VERSION "dbc-export 1 2026.26.6.5"

NS_ :

BS_:

BU_: APB APP APS DAS EPAS3S ESP GTW IBST PARK RADC RCM RCM2 RCM3 TPMS TRCM USM

BO_ 1113 APS_warningMatrix2: 8 APS
 SG_ APS_w129_ECU_Power_Issue : 0|1@1+ (1,0) [0|1] "" Vector__XXX
 SG_ APS_w130_ECU_Thermal_Issue : 1|1@1+ (1,0) [0|1] "" Vector__XXX
 SG_ APS_w131_trap_exception : 2|1@1+ (1,0) [0|1] "" Vector__XXX
 SG_ APS_w132_appVersionMismatch : 3|1@1+ (1,0) [0|1] "" Vector__XXX
 SG_ APS_w133_ETHSwitchError : 4|1@1+ (1,0) [0|1] "" Vector__XXX
 SG_ APS_w134_appMia : 5|1@1+ (1,0) [0|1] "" Vector__XXX
 SG_ APS_w135_appCritical : 6|1@1+ (1,0) [0|1] "" Vector__XXX
 SG_ APS_w136_gpsDisabled : 7|1@1+ (1,0) [0|1] "" Vector__XXX
 SG_ APS_w137_gpsFaultReset : 8|1@1+ (1,0) [0|1] "" Vector__XXX
 SG_ APS_w138_gpsComIssue : 9|1@1+ (1,0) [0|1] "" Vector__XXX
 SG_ APS_w139_udpBufferOverflow : 10|1@1+ (1,0) [0|1] "" Vector__XXX
 SG_ APS_w140_vcfrontMiaVehicleBus : 11|1@1+ (1,0) [0|1] "" Vector__XXX
 SG_ APS_w141_rcmMiaPartyBus : 12|1@1+ (1,0) [0|1] "" Vector__XXX
 SG_ APS_w142_diMiaPartyBus : 13|1@1+ (1,0) [0|1] "" Vector__XXX
 SG_ APS_w143_espMiaPartyBus : 14|1@1+ (1,0) [0|1] "" Vector__XXX
 SG_ APS_w144_vcleftMiaPartyBus : 15|1@1+ (1,0) [0|1] "" Vector__XXX
 SG_ APS_w145_vcrightMiaPartyBus : 16|1@1+ (1,0) [0|1] "" Vector__XXX
 SG_ APS_w146_epas3pMiaPartyBus : 17|1@1+ (1,0) [0|1] "" Vector__XXX
 SG_ APS_w147_vcleftMiaVehBus : 18|1@1+ (1,0) [0|1] "" Vector__XXX
 SG_ APS_w148_vcrightMiaVehBus : 19|1@1+ (1,0) [0|1] "" Vector__XXX
 SG_ APS_w149_epblMiaVehBus : 20|1@1+ (1,0) [0|1] "" Vector__XXX
 SG_ APS_w150_sccmMiaVehBus : 21|1@1+ (1,0) [0|1] "" Vector__XXX
 SG_ APS_w151_apRecovered : 22|1@1+ (1,0) [0|1] "" Vector__XXX
 SG_ APS_w152_gpsFusionStatus : 23|1@1+ (1,0) [0|1] "" Vector__XXX
 SG_ APS_w153_eacInhibit : 24|1@1+ (1,0) [0|1] "" Vector__XXX
 SG_ APS_w155_ethLwipError : 26|1@1+ (1,0) [0|1] "" Vector__XXX
 SG_ APS_w156_lwipAssert : 27|1@1+ (1,0) [0|1] "" Vector__XXX
 SG_ APS_w157_autopilotReboot : 28|1@1+ (1,0) [0|1] "" Vector__XXX
 SG_ APS_w158_apbMia : 29|1@1+ (1,0) [0|1] "" Vector__XXX
 SG_ APS_w159_apbCritical : 30|1@1+ (1,0) [0|1] "" Vector__XXX
 SG_ APS_w160_apbVersionMismatch : 31|1@1+ (1,0) [0|1] "" Vector__XXX
 SG_ APS_w161_gpsAntennaDisconnected : 32|1@1+ (1,0) [0|1] "" Vector__XXX
 SG_ APS_w162_TurboA_DisRegPgoodErr : 33|1@1+ (1,0) [0|1] "" Vector__XXX
 SG_ APS_w163_TurboA_DisRegNFault : 34|1@1+ (1,0) [0|1] "" Vector__XXX
 SG_ APS_w164_TurboA_12VFuseFault : 35|1@1+ (1,0) [0|1] "" Vector__XXX
 SG_ APS_w165_TurboA_Temp_NOS : 36|1@1+ (1,0) [0|1] "" Vector__XXX
 SG_ APS_w166_TurboA_SMSLockStepErr : 37|1@1+ (1,0) [0|1] "" Vector__XXX
 SG_ APS_w167_TurboA_TMU_Throttle : 38|1@1+ (1,0) [0|1] "" Vector__XXX
 SG_ APS_w168_TurboA_SMS_WDOG : 39|1@1+ (1,0) [0|1] "" Vector__XXX
 SG_ APS_w169_TurboA_SCS_LKUP : 40|1@1+ (1,0) [0|1] "" Vector__XXX
 SG_ APS_w170_TurboA_A72_watchdog : 41|1@1+ (1,0) [0|1] "" Vector__XXX
 SG_ APS_w171_TurboA_SMS_taskUtilErr : 42|1@1+ (1,0) [0|1] "" Vector__XXX
 SG_ APS_w172_apFeaturesUnavailable : 43|1@1+ (1,0) [0|1] "" Vector__XXX
 SG_ APS_w178_TurboB_DisRegPgoodErr : 49|1@1+ (1,0) [0|1] "" Vector__XXX
 SG_ APS_w179_TurboB_DisRegNFault : 50|1@1+ (1,0) [0|1] "" Vector__XXX
 SG_ APS_w180_TurboB_12VFuseFault : 51|1@1+ (1,0) [0|1] "" Vector__XXX
 SG_ APS_w181_TurboB_Temp_NOS : 52|1@1+ (1,0) [0|1] "" Vector__XXX
 SG_ APS_w182_TurboB_SMSLockStepErr : 53|1@1+ (1,0) [0|1] "" Vector__XXX
 SG_ APS_w183_TurboB_TMU_Throttle : 54|1@1+ (1,0) [0|1] "" Vector__XXX
 SG_ APS_w184_TurboB_SMS_WDOG : 55|1@1+ (1,0) [0|1] "" Vector__XXX
 SG_ APS_w185_TurboB_SCS_LKUP : 56|1@1+ (1,0) [0|1] "" Vector__XXX
 SG_ APS_w186_TurboB_A72_watchdog : 57|1@1+ (1,0) [0|1] "" Vector__XXX
 SG_ APS_w187_TurboB_SMS_taskUtilErr : 58|1@1+ (1,0) [0|1] "" Vector__XXX
 SG_ APS_w188_otherTurboUartMIA : 59|1@1+ (1,0) [0|1] "" Vector__XXX
 SG_ APS_w189_vcfrontMiaPartyBus : 60|1@1+ (1,0) [0|1] "" Vector__XXX
 SG_ APS_w190_iboosterMia : 61|1@1+ (1,0) [0|1] "" Vector__XXX
 SG_ APS_w191_timesyncError : 62|1@1+ (1,0) [0|1] "" Vector__XXX
 SG_ APS_w192_CANFault : 63|1@1+ (1,0) [0|1] "" Vector__XXX

BO_ 848 APS_warningMatrix3: 8 APS
 SG_ APS_w193_camWindshieldUnclean : 0|1@1+ (1,0) [0|1] "" Vector__XXX
 SG_ APS_w194_accDriverResumeRqrd : 1|1@1+ (1,0) [0|1] "" Vector__XXX
 SG_ APS_w195_scwUnavailable : 2|1@1+ (1,0) [0|1] "" Vector__XXX
 SG_ APS_w196_stopSignWarning : 3|1@1+ (1,0) [0|1] "" Vector__XXX
 SG_ APS_w197_redLightWarning : 4|1@1+ (1,0) [0|1] "" Vector__XXX
 SG_ APS_w198_tsrUnavailable : 5|1@1+ (1,0) [0|1] "" Vector__XXX
 SG_ APS_w199_apcAbort : 6|1@1+ (1,0) [0|1] "" Vector__XXX
 SG_ APS_w200_lcSlowdown : 7|1@1+ (1,0) [0|1] "" Vector__XXX
 SG_ APS_w201_lcAborting : 8|1@1+ (1,0) [0|1] "" Vector__XXX
 SG_ APS_w202_scwNoisyEnvironment : 9|1@1+ (1,0) [0|1] "" Vector__XXX
 SG_ APS_w203_apcActivation : 10|1@1+ (1,0) [0|1] "" Vector__XXX
 SG_ APS_w204_apcFinalFront : 11|1@1+ (1,0) [0|1] "" Vector__XXX
 SG_ APS_w205_apcFinalRear : 12|1@1+ (1,0) [0|1] "" Vector__XXX
 SG_ APS_w206_autosteerNotEnabled : 13|1@1+ (1,0) [0|1] "" Vector__XXX
 SG_ APS_w207_autosteerUnavailable : 14|1@1+ (1,0) [0|1] "" Vector__XXX
 SG_ APS_w208_rackDetected : 15|1@1+ (1,0) [0|1] "" Vector__XXX
 SG_ APS_w209_autoSummonRequest : 16|1@1+ (1,0) [0|1] "" Vector__XXX
 SG_ APS_w210_camObstrcted : 17|1@1+ (1,0) [0|1] "" Vector__XXX
 SG_ APS_w211_accNoSeatBelt : 18|1@1+ (1,0) [0|1] "" Vector__XXX
 SG_ APS_w212_lcUnavailableStrikeOut : 19|1@1+ (1,0) [0|1] "" Vector__XXX
 SG_ APS_w213_autosteerStruckOut : 20|1@1+ (1,0) [0|1] "" Vector__XXX
 SG_ APS_w214_driverNotIntracting : 21|1@1+ (1,0) [0|1] "" Vector__XXX
 SG_ APS_w215_contDriverNotIntracting : 22|1@1+ (1,0) [0|1] "" Vector__XXX
 SG_ APS_w216_driverOverriding : 23|1@1+ (1,0) [0|1] "" Vector__XXX
 SG_ APS_w217_lcUnavailableSpeeding : 24|1@1+ (1,0) [0|1] "" Vector__XXX
 SG_ APS_w218_lcSpeedExceededLimit : 25|1@1+ (1,0) [0|1] "" Vector__XXX
 SG_ APS_w219_lcTempUnavailableSpeed : 26|1@1+ (1,0) [0|1] "" Vector__XXX
 SG_ APS_w220_lcTempUnavailableRoad : 27|1@1+ (1,0) [0|1] "" Vector__XXX
 SG_ APS_w221_accRadarBlind : 28|1@1+ (1,0) [0|1] "" Vector__XXX
 SG_ APS_w222_accCameraBlind : 29|1@1+ (1,0) [0|1] "" Vector__XXX
 SG_ APS_w223_accObjectInPath : 30|1@1+ (1,0) [0|1] "" Vector__XXX
 SG_ APS_w224_accCameraCalibration : 31|1@1+ (1,0) [0|1] "" Vector__XXX
 SG_ APS_w225_lcDegradedVisSpeedLmt : 32|1@1+ (1,0) [0|1] "" Vector__XXX
 SG_ APS_w226_lcCamCalNeededSpeedLmt : 33|1@1+ (1,0) [0|1] "" Vector__XXX
 SG_ APS_w227_virtualWallBlocked : 34|1@1+ (1,0) [0|1] "" Vector__XXX
 SG_ APS_w228_DEPRECATED : 35|1@1+ (1,0) [0|1] "" Vector__XXX
 SG_ APS_w229_alcUltrasoundDamaged : 36|1@1+ (1,0) [0|1] "" Vector__XXX
 SG_ APS_w230_alcUltrasoundBlocked : 37|1@1+ (1,0) [0|1] "" Vector__XXX
 SG_ APS_w231_idfEvent : 38|1@1+ (1,0) [0|1] "" Vector__XXX
 SG_ APS_w232_laneChangeRequested : 39|1@1+ (1,0) [0|1] "" Vector__XXX
 SG_ APS_w235_a72LoopDetected : 42|1@1+ (1,0) [0|1] "" Vector__XXX
 SG_ APS_w236_canSharedMemError : 43|1@1+ (1,0) [0|1] "" Vector__XXX
 SG_ APS_w237_faultMgrEventDetected : 44|1@1+ (1,0) [0|1] "" Vector__XXX
 SG_ APS_w238_resetReason : 45|1@1+ (1,0) [0|1] "" Vector__XXX
 SG_ APS_w241_ddrInitFailures : 48|1@1+ (1,0) [0|1] "" Vector__XXX
 SG_ APS_w242_tripMBISTFailure : 49|1@1+ (1,0) [0|1] "" Vector__XXX
 SG_ APS_w243_tripHWErrorStatus : 50|1@1+ (1,0) [0|1] "" Vector__XXX
 SG_ APS_w244_gpuHWFaultStatus : 51|1@1+ (1,0) [0|1] "" Vector__XXX
 SG_ APS_w245_eloopRxFromUnexpectedSo : 52|1@1+ (1,0) [0|1] "" Vector__XXX
 SG_ APS_w246_ethloopSwitchPortLinkDo : 53|1@1+ (1,0) [0|1] "" Vector__XXX
 SG_ APS_w247_ethernetFrameError : 54|1@1+ (1,0) [0|1] "" Vector__XXX
 SG_ APS_w248_ethloopSwitchPoorSqi : 55|1@1+ (1,0) [0|1] "" Vector__XXX
 SG_ APS_w249_ufsFailures : 56|1@1+ (1,0) [0|1] "" Vector__XXX
 SG_ APS_w250_ethloopSwitchMemUsageTo : 57|1@1+ (1,0) [0|1] "" Vector__XXX
 SG_ APS_w251_ethloopSwitchMemUsageTo : 58|1@1+ (1,0) [0|1] "" Vector__XXX
 SG_ APS_w252_ethSwitchPortLinkDown : 59|1@1+ (1,0) [0|1] "" Vector__XXX
 SG_ APS_w253_powerStateTimeout : 60|1@1+ (1,0) [0|1] "" Vector__XXX
 SG_ APS_w254_sleepStateTimeout : 61|1@1+ (1,0) [0|1] "" Vector__XXX
 SG_ APS_w255_bootHealth : 62|1@1+ (1,0) [0|1] "" Vector__XXX

BO_ 784 APS_warningMatrix4: 8 APS
 SG_ APS_w257_assertFailure : 0|1@1+ (1,0) [0|1] "" Vector__XXX
 SG_ APS_w258_qspiFlashSectorChecksum : 1|1@1+ (1,0) [0|1] "" Vector__XXX
 SG_ APS_w259_qspiFailure : 2|1@1+ (1,0) [0|1] "" Vector__XXX
 SG_ APS_w260_pgoodFailure : 3|1@1+ (1,0) [0|1] "" Vector__XXX
 SG_ APS_w261_vrmFaultGrpA : 4|1@1+ (1,0) [0|1] "" Vector__XXX
 SG_ APS_w262_vrmFaultGrpB : 5|1@1+ (1,0) [0|1] "" Vector__XXX
 SG_ APS_w263_vrmFaultGrpC : 6|1@1+ (1,0) [0|1] "" Vector__XXX
 SG_ APS_w264_ddrPhy0Failures : 7|1@1+ (1,0) [0|1] "" Vector__XXX
 SG_ APS_w265_ddrPhy1Failures : 8|1@1+ (1,0) [0|1] "" Vector__XXX
 SG_ APS_w266_ddrPhy2Failures : 9|1@1+ (1,0) [0|1] "" Vector__XXX
 SG_ APS_w267_ddrPhy3Failures : 10|1@1+ (1,0) [0|1] "" Vector__XXX
 SG_ APS_w268_ddrControllerFailures : 11|1@1+ (1,0) [0|1] "" Vector__XXX
 SG_ APS_w269_ethSwitchRxPageCountToo : 12|1@1+ (1,0) [0|1] "" Vector__XXX
 SG_ APS_w270_ethSwitchRxPageCountToo : 13|1@1+ (1,0) [0|1] "" Vector__XXX
 SG_ APS_w271_ddrScheduler0EccErrors : 14|1@1+ (1,0) [0|1] "" Vector__XXX
 SG_ APS_w272_ddrScheduler1EccErrors : 15|1@1+ (1,0) [0|1] "" Vector__XXX
 SG_ APS_w273_ddrScheduler2EccErrors : 16|1@1+ (1,0) [0|1] "" Vector__XXX
 SG_ APS_w274_ddrScheduler3EccErrors : 17|1@1+ (1,0) [0|1] "" Vector__XXX
 SG_ APS_w275_ddrScheduler4EccErrors : 18|1@1+ (1,0) [0|1] "" Vector__XXX
 SG_ APS_w276_ddrScheduler5EccErrors : 19|1@1+ (1,0) [0|1] "" Vector__XXX
 SG_ APS_w277_ddrScheduler6EccErrors : 20|1@1+ (1,0) [0|1] "" Vector__XXX
 SG_ APS_w278_ddrScheduler7EccErrors : 21|1@1+ (1,0) [0|1] "" Vector__XXX
 SG_ APS_w279_ufsPartitionError : 22|1@1+ (1,0) [0|1] "" Vector__XXX
 SG_ APS_w280_pepsMia : 23|1@1+ (1,0) [0|1] "" Vector__XXX
 SG_ APS_w281_rsaMia : 24|1@1+ (1,0) [0|1] "" Vector__XXX
 SG_ APS_w282_smmuError : 25|1@1+ (1,0) [0|1] "" Vector__XXX
 SG_ APS_w283_psfaMia : 26|1@1+ (1,0) [0|1] "" Vector__XXX
 SG_ APS_w284_cam12VBuckBoostAPwrIssu : 27|1@1+ (1,0) [0|1] "" Vector__XXX
 SG_ APS_w285_cam12VBuckBoostBPwrIssu : 28|1@1+ (1,0) [0|1] "" Vector__XXX
 SG_ APS_w286_cam12VEFuseAPrimaryIssu : 29|1@1+ (1,0) [0|1] "" Vector__XXX
 SG_ APS_w287_cam12VEFuseASecondaryIs : 30|1@1+ (1,0) [0|1] "" Vector__XXX
 SG_ APS_w288_brakeboosterMia : 31|1@1+ (1,0) [0|1] "" Vector__XXX
 SG_ APS_w289_turboTemperatureWarning : 32|1@1+ (1,0) [0|1] "" Vector__XXX
 SG_ APS_w290_cam12VBuckBoostBPwrRing : 33|1@1+ (1,0) [0|1] "" Vector__XXX
 SG_ APS_w291_eplannerError : 34|1@1+ (1,0) [0|1] "" Vector__XXX
 SG_ APS_w292_CH_busOff : 35|1@1+ (1,0) [0|1] "" Vector__XXX
 SG_ APS_w293_PARTY_busOff : 36|1@1+ (1,0) [0|1] "" Vector__XXX
 SG_ APS_w294_VEH_busOff : 37|1@1+ (1,0) [0|1] "" Vector__XXX
 SG_ APS_w295_PT_busOff : 38|1@1+ (1,0) [0|1] "" Vector__XXX
 SG_ APS_w296_wdogMonTaskDeadlineMiss : 39|1@1+ (1,0) [0|1] "" Vector__XXX
 SG_ APS_w297_earlyWDogAlert : 40|1@1+ (1,0) [0|1] "" Vector__XXX
 SG_ APS_w298_cpuToApCanSharedMemErro : 41|1@1+ (1,0) [0|1] "" Vector__XXX
 SG_ APS_w299_apToCpuCanSharedMemErro : 42|1@1+ (1,0) [0|1] "" Vector__XXX
 SG_ APS_w300_sharedMemoryAccessError : 43|1@1+ (1,0) [0|1] "" Vector__XXX
 SG_ APS_w301_nocTimeoutDetected : 44|1@1+ (1,0) [0|1] "" Vector__XXX
 SG_ APS_w302_canAPShmFifoFull : 45|1@1+ (1,0) [0|1] "" Vector__XXX
 SG_ APS_w303_canAPShmFifoEmpty : 46|1@1+ (1,0) [0|1] "" Vector__XXX
 SG_ APS_w304_dataAbort : 47|1@1+ (1,0) [0|1] "" Vector__XXX
 SG_ APS_w305_gpsPgoodFailure : 48|1@1+ (1,0) [0|1] "" Vector__XXX
 SG_ APS_w306_ethPgoodFailure : 49|1@1+ (1,0) [0|1] "" Vector__XXX
 SG_ APS_w307_eccEventDetected : 50|1@1+ (1,0) [0|1] "" Vector__XXX
 SG_ APS_w308_pmicErrorDetected : 51|1@1+ (1,0) [0|1] "" Vector__XXX
 SG_ APS_w309_ethBridgeDown : 52|1@1+ (1,0) [0|1] "" Vector__XXX
 SG_ APS_w310_wakeBootMetrics : 53|1@1+ (1,0) [0|1] "" Vector__XXX
 SG_ APS_w311_apbdgDasMia : 54|1@1+ (1,0) [0|1] "" Vector__XXX
 SG_ APS_w312_apbdgApMia : 55|1@1+ (1,0) [0|1] "" Vector__XXX
 SG_ APS_w313_BDY_busOff : 56|1@1+ (1,0) [0|1] "" Vector__XXX
 SG_ APS_w315_epas3pMiaBdyBus : 58|1@1+ (1,0) [0|1] "" Vector__XXX
 SG_ APS_w316_apBootHealth : 59|1@1+ (1,0) [0|1] "" Vector__XXX
 SG_ APS_w317_uiMia : 60|1@1+ (1,0) [0|1] "" Vector__XXX
 SG_ APS_w318_ethernetNetworkBufferHi : 61|1@1+ (1,0) [0|1] "" Vector__XXX
 SG_ APS_w319_vehDasImposterDetected : 62|1@1+ (1,0) [0|1] "" Vector__XXX
 SG_ APS_w320_eplannerPreconditionsMe : 63|1@1+ (1,0) [0|1] "" Vector__XXX

BO_ 1465 DAS_alertLog: 8 DAS
 SG_ DAS_alertID M : 0|15@1+ (1,0) [0|32767] "" Vector__XXX
 SG_ DAS_alertState : 15|1@1+ (1,0) [0|1] "" Vector__XXX
 SG_ DAS_sw073_escalateLDWs m73 : 16|1@1+ (1,0) [0|1] "" Vector__XXX
 SG_ DAS_sw073_silentEscalatedLDW m73 : 17|1@1+ (1,0) [0|1] "" Vector__XXX
 SG_ DAS_sw073_escalateLDWreason m73 : 18|3@1+ (1,0) [0|7] "" Vector__XXX
 SG_ DAS_sw073_rawMobileyeLDW m73 : 21|2@1+ (1,0) [0|3] "" Vector__XXX
 SG_ DAS_sw073_freespaceLDW m73 : 24|2@1+ (1,0) [0|3] "" Vector__XXX
 SG_ DAS_sw073_freespaceLeftC0 m73 : 26|7@1+ (0.2,-12.8) [-12.8|12.6] "m" Vector__XXX
 SG_ DAS_sw073_freespaceRightC0 m73 : 33|7@1+ (0.2,-12.8) [-12.8|12.6] "m" Vector__XXX
 SG_ DAS_sw073_freespaceLeftC1 m73 : 40|8@1+ (0.0016,-0.2) [-0.2|0.208] "rad" Vector__XXX
 SG_ DAS_sw073_freespaceRightC1 m73 : 48|8@1+ (0.0016,-0.2) [-0.2|0.208] "rad" Vector__XXX
 SG_ DAS_sw073_freespaceLeftFarZ m73 : 56|4@1+ (4,0) [0|60] "m" Vector__XXX
 SG_ DAS_sw073_freespaceRightFarZ m73 : 60|4@1+ (4,0) [0|60] "m" Vector__XXX
 SG_ DAS_sw230_sensor1Blocked m230 : 16|1@1+ (1,0) [0|1] "" Vector__XXX
 SG_ DAS_sw230_sensor2Blocked m230 : 17|1@1+ (1,0) [0|1] "" Vector__XXX
 SG_ DAS_sw230_sensor3Blocked m230 : 18|1@1+ (1,0) [0|1] "" Vector__XXX
 SG_ DAS_sw230_sensor4Blocked m230 : 19|1@1+ (1,0) [0|1] "" Vector__XXX
 SG_ DAS_sw230_sensor5Blocked m230 : 20|1@1+ (1,0) [0|1] "" Vector__XXX
 SG_ DAS_sw230_sensor6Blocked m230 : 21|1@1+ (1,0) [0|1] "" Vector__XXX
 SG_ DAS_sw230_sensor7Blocked m230 : 22|1@1+ (1,0) [0|1] "" Vector__XXX
 SG_ DAS_sw230_sensor8Blocked m230 : 23|1@1+ (1,0) [0|1] "" Vector__XXX
 SG_ DAS_sw230_sensor9Blocked m230 : 24|1@1+ (1,0) [0|1] "" Vector__XXX
 SG_ DAS_sw230_sensor10Blocked m230 : 25|1@1+ (1,0) [0|1] "" Vector__XXX
 SG_ DAS_sw230_sensor11Blocked m230 : 26|1@1+ (1,0) [0|1] "" Vector__XXX
 SG_ DAS_sw230_sensor12Blocked m230 : 27|1@1+ (1,0) [0|1] "" Vector__XXX

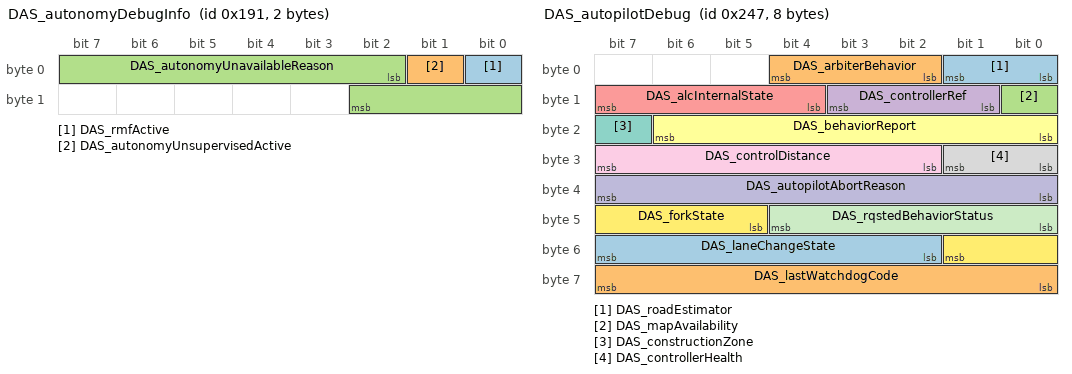
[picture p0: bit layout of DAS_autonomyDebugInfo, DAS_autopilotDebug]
BO_ 401 DAS_autonomyDebugInfo: 2 DAS
 SG_ DAS_rmfActive : 0|1@1+ (1,0) [0|1] "" Vector__XXX
 SG_ DAS_autonomyUnsupervisedActive : 1|1@1+ (1,0) [0|1] "" Vector__XXX
 SG_ DAS_autonomyUnavailableReason : 2|9@1+ (1,0) [0|511] "" Vector__XXX

BO_ 583 DAS_autopilotDebug: 8 DAS
 SG_ DAS_roadEstimator : 0|2@1+ (1,0) [0|3] "" Vector__XXX
 SG_ DAS_arbiterBehavior : 2|3@1+ (1,0) [0|7] "" Vector__XXX
 SG_ DAS_mapAvailability : 8|1@1+ (1,0) [0|1] "" Vector__XXX
 SG_ DAS_controllerRef : 9|3@1+ (1,0) [0|7] "" Vector__XXX
 SG_ DAS_alcInternalState : 12|4@1+ (1,0) [0|15] "" Vector__XXX
 SG_ DAS_behaviorReport : 16|7@1+ (1,0) [0|127] "" Vector__XXX
 SG_ DAS_constructionZone : 23|1@1+ (1,0) [0|1] "" Vector__XXX
 SG_ DAS_controllerHealth : 24|2@1+ (1,0) [0|3] "" Vector__XXX
 SG_ DAS_controlDistance : 26|6@1+ (2,0) [0|126] "m" Vector__XXX
 SG_ DAS_autopilotAbortReason : 32|8@1+ (1,0) [0|255] "" Vector__XXX
 SG_ DAS_rqstedBehaviorStatus : 40|5@1+ (1,0) [0|31] "" Vector__XXX
 SG_ DAS_forkState : 45|5@1+ (1,0) [0|31] "" Vector__XXX
 SG_ DAS_laneChangeState : 50|6@1+ (1,0) [0|63] "" Vector__XXX
 SG_ DAS_lastWatchdogCode : 56|8@1+ (1,0) [0|255] "" Vector__XXX

BO_ 1497 DAS_carLog: 8 DAS
 SG_ DAS_carLogMultiplexer M : 0|4@1+ (1,0) [0|15] "" Vector__XXX
 SG_ DAS_radarTarget5_dx m1 : 4|12@1+ (0.0625,0) [0|255.9375] "m" Vector__XXX
 SG_ DAS_radarTarget1_dx m1 : 24|12@1+ (0.0625,0) [0|255.9375] "m" Vector__XXX
 SG_ DAS_radarTarget1_VxRel m1 : 36|8@1+ (0.2,-25.6) [-25.6|25.4] "m/s" Vector__XXX
 SG_ DAS_mobileyeVehAebFlag m2 : 4|1@1+ (1,0) [0|1] "" Vector__XXX
 SG_ DAS_mobileyePedAebFlag m2 : 5|1@1+ (1,0) [0|1] "" Vector__XXX
 SG_ DAS_mobileyeIPSOapproved m2 : 6|1@1+ (1,0) [0|1] "" Vector__XXX
 SG_ DAS_fcmSteeringOverride m2 : 7|1@1+ (1,0) [0|1] "" Vector__XXX
 SG_ DAS_fcmCollisionStage3Checks m2 : 8|8@1+ (1,0) [0|255] "" Vector__XXX
 SG_ DAS_fcmThreatAssesmentMode m2 : 16|3@1+ (1,0) [0|7] "" Vector__XXX
 SG_ DAS_constructionArea m2 : 19|2@1+ (1,0) [0|3] "" Vector__XXX
 SG_ DAS_restrictionLowSpeedTraffic m2 : 21|1@1+ (1,0) [0|1] "" Vector__XXX
 SG_ DAS_associated_rad_object m2 : 22|2@1+ (1,0) [0|3] "" Vector__XXX
 SG_ DAS_LC_handsOnReason m2 : 24|6@1+ (1,0) [0|63] "" Vector__XXX
 SG_ DAS_ACC_camStatus m2 : 30|2@1+ (1,0) [0|3] "" Vector__XXX
 SG_ DAS_aeb_not_activating_reason m2 : 32|5@1+ (1,0) [0|31] "" Vector__XXX
 SG_ DAS_handsOnDetected m2 : 38|2@1+ (1,0) [1|3] "" Vector__XXX
 SG_ DAS_driveOnNavUnavailableReason m2 : 40|5@1+ (1,0) [0|31] "" Vector__XXX
 SG_ DAS_accUnavailableReason m2 : 46|7@1+ (1,0) [0|127] "" Vector__XXX
 SG_ DAS_pmmNotActivatingReason m2 : 53|5@1+ (1,0) [0|31] "" Vector__XXX
 SG_ DAS_desiredTarget_dx m3 : 16|8@1+ (0.5,0) [0|127] "m" Vector__XXX
 SG_ DAS_radarTarget2_dx m3 : 24|12@1+ (0.0625,0) [0|255.9375] "m" Vector__XXX
 SG_ DAS_radarTarget3_dx m3 : 36|12@1+ (0.0625,0) [0|255.9375] "m" Vector__XXX
 SG_ DAS_radarTarget4_dx m3 : 48|12@1+ (0.0625,0) [0|255.9375] "m" Vector__XXX
 SG_ DAS_closestInLaneTargetDx m4 : 4|12@1+ (0.0625,0) [0|255.9375] "m" Vector__XXX
 SG_ DAS_secondInLaneTargetDx m4 : 16|12@1+ (0.0625,0) [0|255.9375] "m" Vector__XXX
 SG_ DAS_closestLeftLaneTargetDx m4 : 28|12@1+ (0.0625,0) [0|255.9375] "m" Vector__XXX
 SG_ DAS_closestRightLaneTargetDx m4 : 40|12@1+ (0.0625,0) [0|255.9375] "m" Vector__XXX
 SG_ DAS_closestInLaneTargetVxRel m4 : 52|10@1+ (0.1,-51.1) [-51.1|51.2] "m/s" Vector__XXX

BO_ 970 DAS_gpsStatus: 8 DAS
 SG_ DAS_gpsStatusMultiplexer M : 0|4@1+ (1,0) [0|15] "" Vector__XXX
 SG_ DAS_gpsTransportModeState m0 : 4|1@1+ (1,0) [0|1] "" Vector__XXX
 SG_ DAS_gpsSatsInUseHardware m0 : 5|4@1+ (1,0) [0|15] "" Vector__XXX
 SG_ DAS_gpsRejectingSatData m0 : 57|1@1+ (1,0) [0|1] "" Vector__XXX
 SG_ DAS_gpsWheelsOffMotionDetected m0 : 58|1@1+ (1,0) [0|1] "" Vector__XXX
 SG_ DAS_gpsFixTypeHardware m0 : 59|3@1+ (1,0) [0|7] "" Vector__XXX
 SG_ DAS_gpsRawxEnabled m0 : 62|1@1+ (1,0) [0|1] "" Vector__XXX
 SG_ DAS_gpsRxmRawxMia m1 : 4|1@1+ (1,0) [0|1] "" Vector__XXX
 SG_ DAS_gpsRxmSfrbxMia m1 : 5|1@1+ (1,0) [0|1] "" Vector__XXX
 SG_ DAS_gpsEsfMeasMia m1 : 6|1@1+ (1,0) [0|1] "" Vector__XXX
 SG_ DAS_gpsEsfRawMia m1 : 7|1@1+ (1,0) [0|1] "" Vector__XXX
 SG_ DAS_gpsNavStatusMia m1 : 8|1@1+ (1,0) [0|1] "" Vector__XXX
 SG_ DAS_gpsSoftwareConfigured m1 : 9|1@1+ (1,0) [0|1] "" Vector__XXX
 SG_ DAS_gpsSoftwareUsed m1 : 10|1@1+ (1,0) [0|1] "" Vector__XXX
 SG_ DAS_gpsSoftwareFastStartReady m1 : 11|1@1+ (1,0) [0|1] "" Vector__XXX
 SG_ DAS_gpsSatsInUseSoftware m1 : 12|4@1+ (1,0) [0|15] "" Vector__XXX
 SG_ DAS_gpsFixTypeSoftware m1 : 16|3@1+ (1,0) [0|7] "" Vector__XXX
 SG_ DAS_gpsCWJammingInidcator m1 : 19|5@1+ (8,0) [0|248] "-" Vector__XXX
 SG_ DAS_gpsJammingState m1 : 24|2@1+ (1,0) [0|3] "" Vector__XXX
 SG_ DAS_gpsSpoofDetectorState m1 : 26|2@1+ (1,0) [0|3] "" Vector__XXX
 SG_ DAS_gpsInvalidMsgPercentage m1 : 28|4@1+ (6,0) [0|90] "%" Vector__XXX
 SG_ DAS_gnssConstellationsState m1 : 32|2@1+ (1,0) [0|3] "" Vector__XXX
 SG_ DAS_gpsReceiverNoiseLevel m1 : 34|6@1+ (8,0) [0|504] "-" Vector__XXX
 SG_ DAS_gpsAutomaticGainControl m1 : 40|8@1+ (32,0) [0|8160] "-" Vector__XXX
 SG_ DAS_gpsPreviousPositionDeltaHw m1 : 48|6@1+ (3,0) [0|189] "m" Vector__XXX
 SG_ DAS_gpsPreviousPositionDeltaSw m1 : 54|6@1+ (3,0) [0|189] "m" Vector__XXX
 SG_ DAS_gpsNmeaDispatchFailureCount m1 : 60|4@1+ (5,0) [0|75] "-" Vector__XXX
 SG_ DAS_gnssMaxInstantaneousCnorGps m2 : 4|6@1+ (1,0) [0|63] "" Vector__XXX
 SG_ DAS_gnssMaxInstantaneousCnorGal m2 : 10|6@1+ (1,0) [0|63] "" Vector__XXX
 SG_ DAS_gnssMaxInstantaneousCnorBds m2 : 16|6@1+ (1,0) [0|63] "" Vector__XXX
 SG_ DAS_gpsResetReason m2 : 22|4@1+ (1,0) [0|15] "" Vector__XXX
 SG_ DAS_gpsAccuracyHorizontal m2 : 26|6@1+ (1,0) [0|63] "m" Vector__XXX
 SG_ DAS_gpsAccuracyVertical m2 : 32|6@1+ (1,0) [0|63] "m" Vector__XXX
 SG_ DAS_gpsSolutionFallback m2 : 38|1@1+ (1,0) [0|1] "" Vector__XXX
 SG_ DAS_gpsToMcuSource m2 : 39|3@1+ (1,0) [0|7] "" Vector__XXX
 SG_ DAS_gpsSolutionSoc m2 : 42|2@1+ (1,0) [0|3] "" Vector__XXX
 SG_ DAS_gpsRedundancyActive m2 : 44|1@1+ (1,0) [0|1] "" Vector__XXX
 SG_ DAS_gpsFixTypeSoftwareSocB m2 : 45|3@1+ (1,0) [0|7] "" Vector__XXX
 SG_ DAS_gpsSatsInUseSoftwareSocB m2 : 48|4@1+ (1,0) [0|15] "" Vector__XXX
 SG_ DAS_gnssNumSatsGps m3 : 4|4@1+ (1,0) [0|15] "" Vector__XXX
 SG_ DAS_gnssNumSatsGal m3 : 8|4@1+ (1,0) [0|15] "" Vector__XXX
 SG_ DAS_gnssNumSatsBds m3 : 12|4@1+ (1,0) [0|15] "" Vector__XXX
 SG_ DAS_gnssAvgInstantaneousCnorGps m3 : 16|6@1+ (1,0) [0|63] "" Vector__XXX
 SG_ DAS_gnssAvgInstantaneousCnorGal m3 : 22|6@1+ (1,0) [0|63] "" Vector__XXX
 SG_ DAS_gnssAvgInstantaneousCnorBds m3 : 28|6@1+ (1,0) [0|63] "" Vector__XXX
 SG_ DAS_gnssAvgInstantaneousCnorGpsL m3 : 46|6@1+ (1,0) [0|63] "" Vector__XXX
 SG_ DAS_gnssAvgInstantaneousCnorGalL m3 : 52|6@1+ (1,0) [0|63] "" Vector__XXX
 SG_ DAS_gnssAvgInstantaneousCnorBdsL m3 : 58|6@1+ (1,0) [0|63] "" Vector__XXX

BO_ 1337 DAS_info: 8 DAS
 SG_ DAS_infoIndex M : 0|8@1+ (1,0) [0|255] "" Vector__XXX
 SG_ DAS_infoBuildType m10 : 8|8@1+ (1,0) [0|255] "" Vector__XXX
 SG_ DAS_infoBuildConfigID m10 : 16|16@1+ (1,0) [0|65535] "" Vector__XXX
 SG_ DAS_infoHardwareID m10 : 32|16@1+ (1,0) [0|65535] "" Vector__XXX
 SG_ DAS_infoComponentID m10 : 48|16@1+ (1,0) [0|65535] "" Vector__XXX
 SG_ DAS_infoPcbaID m11 : 16|8@1+ (1,0) [0|255] "" Vector__XXX
 SG_ DAS_infoAssemblyID m11 : 24|8@1+ (1,0) [0|255] "" Vector__XXX
 SG_ DAS_infoUsageID m11 : 32|16@1+ (1,0) [0|65535] "" Vector__XXX
 SG_ DAS_infoSubUsageID m11 : 48|16@1+ (1,0) [0|65535] "" Vector__XXX
 SG_ DAS_infoApplicationCRC m13 : 32|32@1+ (1,0) [0|4294967295] "" Vector__XXX
 SG_ DAS_infoAppGitHashBytes m17 : 8|56@1+ (1,0) [0|7.20575940379e+16] "" Vector__XXX
 SG_ DAS_infoBootGitHashBytes m18 : 8|56@1+ (1,0) [0|7.20575940379e+16] "" Vector__XXX

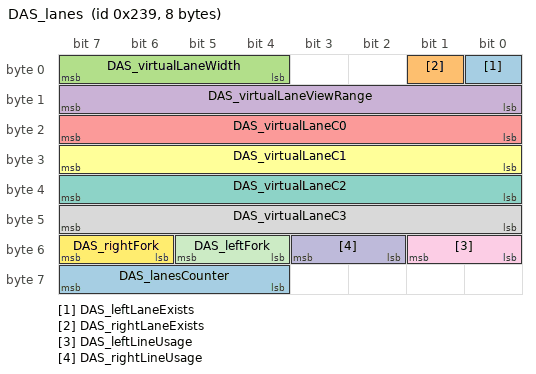
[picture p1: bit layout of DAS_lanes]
BO_ 569 DAS_lanes: 8 DAS
 SG_ DAS_leftLaneExists : 0|1@1+ (1,0) [0|1] "" Vector__XXX
 SG_ DAS_rightLaneExists : 1|1@1+ (1,0) [0|1] "" Vector__XXX
 SG_ DAS_virtualLaneWidth : 4|4@1+ (0.3125,2) [2|6.6875] "m" Vector__XXX
 SG_ DAS_virtualLaneViewRange : 8|8@1+ (1,0) [0|160] "m" Vector__XXX
 SG_ DAS_virtualLaneC0 : 16|8@1+ (0.035,-3.5) [-3.5|3.5] "m" Vector__XXX
 SG_ DAS_virtualLaneC1 : 24|8@1+ (0.0016,-0.2) [-0.2|0.2] "rad" Vector__XXX
 SG_ DAS_virtualLaneC2 : 32|8@1+ (2.0e-05,-0.0025) [-0.0025|0.0025] "m-1" Vector__XXX
 SG_ DAS_virtualLaneC3 : 40|8@1+ (2.4e-07,-3.0e-05) [-3.0e-05|3.0e-05] "m-2" Vector__XXX
 SG_ DAS_leftLineUsage : 48|2@1+ (1,0) [0|3] "" Vector__XXX
 SG_ DAS_rightLineUsage : 50|2@1+ (1,0) [0|3] "" Vector__XXX
 SG_ DAS_leftFork : 52|2@1+ (1,0) [0|3] "" Vector__XXX
 SG_ DAS_rightFork : 54|2@1+ (1,0) [0|3] "" Vector__XXX
 SG_ DAS_lanesCounter : 60|4@1+ (1,0) [0|15] "" Vector__XXX

BO_ 921 DAS_status: 8 DAS
 SG_ DAS_autopilotState : 0|4@1+ (1,0) [0|14] "" Vector__XXX
 SG_ DAS_blindSpotRearLeft : 4|2@1+ (1,0) [0|2] "" Vector__XXX
 SG_ DAS_blindSpotRearRight : 6|2@1+ (1,0) [0|2] "" Vector__XXX
 SG_ DAS_fusedSpeedLimit : 8|5@1+ (5,0) [5|150] "kph/mph" Vector__XXX
 SG_ DAS_suppressSpeedWarning : 13|1@1+ (1,0) [0|1] "" Vector__XXX
 SG_ DAS_summonObstacle : 14|1@1+ (1,0) [0|1] "" Vector__XXX
 SG_ DAS_summonClearedGate : 15|1@1+ (1,0) [0|1] "" Vector__XXX
 SG_ DAS_visionOnlySpeedLimit : 16|5@1+ (5,0) [5|150] "kph/mph" Vector__XXX
 SG_ DAS_heaterState : 21|1@1+ (1,0) [0|1] "" Vector__XXX
 SG_ DAS_forwardCollisionWarning : 22|2@1+ (1,0) [0|2] "" Vector__XXX
 SG_ DAS_autoparkReady : 24|1@1+ (1,0) [0|1] "" Vector__XXX
 SG_ DAS_autoParked : 25|1@1+ (1,0) [0|1] "" Vector__XXX
 SG_ DAS_autoparkActive : 26|1@1+ (1,0) [0|1] "" Vector__XXX
 SG_ DAS_summonFwdLeashReached : 27|1@1+ (1,0) [0|1] "" Vector__XXX
 SG_ DAS_summonRvsLeashReached : 28|1@1+ (1,0) [0|1] "" Vector__XXX
 SG_ DAS_lssState : 29|3@1+ (1,0) [0|7] "" Vector__XXX
 SG_ DAS_sideCollisionAvoid : 32|2@1+ (1,0) [0|2] "" Vector__XXX
 SG_ DAS_sideCollisionWarning : 34|2@1+ (1,0) [0|3] "" Vector__XXX
 SG_ DAS_sideCollisionInhibit : 36|1@1+ (1,0) [0|1] "" Vector__XXX
 SG_ DAS_laneDepartureWarning : 37|3@1+ (1,0) [0|7] "" Vector__XXX
 SG_ DAS_fleetSpeedState : 40|2@1+ (1,0) [0|3] "" Vector__XXX
 SG_ DAS_autopilotHandsOnState : 42|4@1+ (1,0) [0|14] "" Vector__XXX
 SG_ DAS_autoLaneChangeState : 46|5@1+ (1,0) [0|30] "" Vector__XXX
 SG_ DAS_summonAvailable : 51|1@1+ (1,0) [0|1] "" Vector__XXX
 SG_ DAS_statusCounter : 52|4@1+ (1,0) [0|15] "" Vector__XXX
 SG_ DAS_statusChecksum : 56|8@1+ (1,0) [0|255] "" Vector__XXX

BO_ 905 DAS_status2: 8 DAS
 SG_ DAS_accSpeedLimit : 0|9@1+ (0.4,0) [0|200] "mph" Vector__XXX
 SG_ DAS_versionIdentifier : 9|1@1+ (1,0) [0|1] "" Vector__XXX
 SG_ DAS_pmmObstacleSeverity : 10|3@1+ (1,0) [0|6] "" Vector__XXX
 SG_ DAS_pmmLoggingRequest : 13|1@1+ (1,0) [0|1] "" Vector__XXX
 SG_ DAS_activationFailureStatus : 14|2@1+ (1,0) [0|3] "" Vector__XXX
 SG_ DAS_pmmUltrasonicsFaultReason : 16|3@1+ (1,0) [0|7] "" Vector__XXX
 SG_ DAS_pmmRadarFaultReason : 19|2@1+ (1,0) [0|3] "" Vector__XXX
 SG_ DAS_pmmSysFaultReason : 21|3@1+ (1,0) [0|7] "" Vector__XXX
 SG_ DAS_pmmCameraFaultReason : 24|2@1+ (1,0) [0|3] "" Vector__XXX
 SG_ DAS_ACC_report : 26|5@1+ (1,0) [0|31] "" Vector__XXX
 SG_ DAS_relaxCruiseLimits : 31|1@1+ (1,0) [0|1] "" Vector__XXX
 SG_ DAS_csaState : 32|2@1+ (1,0) [0|3] "" Vector__XXX
 SG_ DAS_radarTelemetry : 34|2@1+ (1,0) [0|3] "" Vector__XXX
 SG_ DAS_robState : 36|2@1+ (1,0) [0|3] "" Vector__XXX
 SG_ DAS_driverInteractionLevel : 38|2@1+ (1,0) [0|3] "" Vector__XXX
 SG_ DAS_ppOffsetDesiredRamp : 40|8@1+ (0.01,-1.28) [-1.28|1.27] "m" Vector__XXX
 SG_ DAS_longCollisionWarning : 48|4@1+ (1,0) [0|14] "" Vector__XXX
 SG_ DAS_status2Counter : 52|4@1+ (1,0) [0|15] "" Vector__XXX
 SG_ DAS_status2Checksum : 56|8@1+ (1,0) [0|255] "" Vector__XXX

BO_ 1625 DAS_udsResponse: 8 DAS
 SG_ DAS_udsResponseData : 7|64@0+ (1,0) [0|1.84467440737e+19] "" Vector__XXX

BO_ 586 DAS_visualDebug: 8 DAS
 SG_ DAS_autosteerVehiclesUsage : 4|2@1+ (1,0) [0|3] "" Vector__XXX
 SG_ DAS_autosteerHPPUsage : 6|2@1+ (1,0) [0|3] "" Vector__XXX
 SG_ DAS_autosteerNavigationUsage : 8|2@1+ (1,0) [0|3] "" Vector__XXX
 SG_ DAS_autosteerModelUsage : 10|2@1+ (1,0) [0|3] "" Vector__XXX
 SG_ DAS_autosteerBottsDotsUsage : 12|2@1+ (1,0) [0|3] "" Vector__XXX
 SG_ DAS_offsetSide : 14|2@1+ (1,0) [0|3] "" Vector__XXX
 SG_ DAS_roadSurfaceType : 16|2@1+ (1,0) [1|3] "" Vector__XXX
 SG_ DAS_autosteerHealthAnomalyLevel : 18|3@1+ (1,0) [0|7] "" Vector__XXX
 SG_ DAS_autosteerHealthState : 21|3@1+ (1,0) [0|7] "" Vector__XXX
 SG_ DAS_lastLinePreferenceReason : 24|4@1+ (1,0) [0|15] "" Vector__XXX
 SG_ DAS_plannerState : 28|4@1+ (1,0) [0|15] "" Vector__XXX
 SG_ DAS_lastAutosteerAbortReason : 32|6@1+ (1,0) [0|63] "" Vector__XXX
 SG_ DAS_devAppInterfaceEnabled : 38|1@1+ (1,0) [0|1] "" Vector__XXX
 SG_ DAS_navAvailable : 39|1@1+ (1,0) [0|1] "" Vector__XXX
 SG_ DAS_navDistance : 40|8@1+ (100,0) [0|25500] "km" Vector__XXX
 SG_ DAS_accSmartSpeedActive : 48|1@1+ (1,0) [0|1] "" Vector__XXX
 SG_ DAS_accSmartSpeedState : 49|3@1+ (1,0) [0|6] "" Vector__XXX
 SG_ DAS_ulcInProgress : 52|1@1+ (1,0) [0|1] "" Vector__XXX
 SG_ DAS_trafficAwareSetSpeedInUse : 53|1@1+ (1,0) [0|1] "" Vector__XXX
 SG_ DAS_isaSystemState : 54|2@1+ (1,0) [0|3] "" Vector__XXX
 SG_ DAS_behaviorType : 56|2@1+ (1,0) [0|3] "" Vector__XXX
 SG_ DAS_ulcType : 58|2@1+ (1,0) [0|3] "" Vector__XXX
 SG_ DAS_rearVehDetectedThisCycle : 60|1@1+ (1,0) [0|1] "" Vector__XXX
 SG_ DAS_rearLeftVehDetectedCurrent : 61|1@1+ (1,0) [0|1] "" Vector__XXX
 SG_ DAS_rearRightVehDetectedTrip : 62|1@1+ (1,0) [0|1] "" Vector__XXX
 SG_ DAS_rearLeftVehDetectedTrip : 63|1@1+ (1,0) [0|1] "" Vector__XXX

BO_ 810 DAS_warningMatrix0: 8 DAS
 SG_ DAS_w002_ldwDisabled : 1|1@1+ (1,0) [0|1] "" Vector__XXX
 SG_ DAS_w003_isaDisabled : 2|1@1+ (1,0) [0|1] "" Vector__XXX
 SG_ DAS_w004_accDisabled : 3|1@1+ (1,0) [0|1] "" Vector__XXX
 SG_ DAS_w005_fcwCancelled : 4|1@1+ (1,0) [0|1] "" Vector__XXX
 SG_ DAS_w006_aebCancelled : 5|1@1+ (1,0) [0|1] "" Vector__XXX
 SG_ DAS_w007_ahlbDisabled : 6|1@1+ (1,0) [0|1] "" Vector__XXX
 SG_ DAS_w008_parkDisabled : 7|1@1+ (1,0) [0|1] "" Vector__XXX
 SG_ DAS_w009_aebFault : 8|1@1+ (1,0) [0|1] "" Vector__XXX
 SG_ DAS_w010_radcCalibIssue : 9|1@1+ (1,0) [0|1] "" Vector__XXX
 SG_ DAS_w011_scaEvent : 10|1@1+ (1,0) [0|1] "" Vector__XXX
 SG_ DAS_w012_Cam_BootFailure : 11|1@1+ (1,0) [0|1] "" Vector__XXX
 SG_ DAS_w013_Cam_Watchdog : 12|1@1+ (1,0) [0|1] "" Vector__XXX
 SG_ DAS_w014_swAssert : 13|1@1+ (1,0) [0|1] "" Vector__XXX
 SG_ DAS_w015_Camera_Failsafes : 14|1@1+ (1,0) [0|1] "" Vector__XXX
 SG_ DAS_w016_aeb_e_event : 15|1@1+ (1,0) [0|1] "" Vector__XXX
 SG_ DAS_w017_Cam_Msg_MIA : 16|1@1+ (1,0) [0|1] "" Vector__XXX
 SG_ DAS_w018_ECU_Power_Issue : 17|1@1+ (1,0) [0|1] "" Vector__XXX
 SG_ DAS_w019_ECU_Stack_Overflow : 18|1@1+ (1,0) [0|1] "" Vector__XXX
 SG_ DAS_w020_ECU_checkstopError : 19|1@1+ (1,0) [0|1] "" Vector__XXX
 SG_ DAS_w021_ECU_Temperature_Issue : 20|1@1+ (1,0) [0|1] "" Vector__XXX
 SG_ DAS_w022_ECU_EEPROM_Failure : 21|1@1+ (1,0) [0|1] "" Vector__XXX
 SG_ DAS_w023_ECU_Cam_Statemismatc : 22|1@1+ (1,0) [0|1] "" Vector__XXX
 SG_ DAS_w024_ECU_Watchdog_Reset : 23|1@1+ (1,0) [0|1] "" Vector__XXX
 SG_ DAS_w025_LC_Steering_Override : 24|1@1+ (1,0) [0|1] "" Vector__XXX
 SG_ DAS_w026_ECU_timingIssue : 25|1@1+ (1,0) [0|1] "" Vector__XXX
 SG_ DAS_w027_ECU_Reset_Fault : 26|1@1+ (1,0) [0|1] "" Vector__XXX
 SG_ DAS_w028_spi_rx_error : 27|1@1+ (1,0) [0|1] "" Vector__XXX
 SG_ DAS_w029_spi_tx_error : 28|1@1+ (1,0) [0|1] "" Vector__XXX
 SG_ DAS_w030_Heater_Issue : 29|1@1+ (1,0) [0|1] "" Vector__XXX
 SG_ DAS_w031_canRxError : 30|1@1+ (1,0) [0|1] "" Vector__XXX
 SG_ DAS_w032_canTxError : 31|1@1+ (1,0) [0|1] "" Vector__XXX
 SG_ DAS_w033_gtwMia : 32|1@1+ (1,0) [0|1] "" Vector__XXX
 SG_ DAS_w034_sccmMia : 33|1@1+ (1,0) [0|1] "" Vector__XXX
 SG_ DAS_w035_espMia : 34|1@1+ (1,0) [0|1] "" Vector__XXX
 SG_ DAS_w036_bdyMia : 35|1@1+ (1,0) [0|1] "" Vector__XXX
 SG_ DAS_w037_camTacIssue : 36|1@1+ (1,0) [0|1] "" Vector__XXX
 SG_ DAS_w038_camFailure : 37|1@1+ (1,0) [0|1] "" Vector__XXX
 SG_ DAS_w039_sdm_rcm_Mia : 38|1@1+ (1,0) [0|1] "" Vector__XXX
 SG_ DAS_w040_autopilotAngleSaturated : 39|1@1+ (1,0) [0|1] "" Vector__XXX
 SG_ DAS_w041_autopilotRateSaturated : 40|1@1+ (1,0) [0|1] "" Vector__XXX
 SG_ DAS_w042_autopilotAborting : 41|1@1+ (1,0) [0|1] "" Vector__XXX
 SG_ DAS_w043_camLongRunTime : 42|1@1+ (1,0) [0|1] "" Vector__XXX
 SG_ DAS_w044_appMobileyeFailure : 43|1@1+ (1,0) [0|1] "" Vector__XXX
 SG_ DAS_w045_radMia : 44|1@1+ (1,0) [0|1] "" Vector__XXX
 SG_ DAS_w046_eepromRecordAbsent : 45|1@1+ (1,0) [0|1] "" Vector__XXX
 SG_ DAS_w047_edrEvent : 46|1@1+ (1,0) [0|1] "" Vector__XXX
 SG_ DAS_w048_DAS_Features_Disabled : 47|1@1+ (1,0) [0|1] "" Vector__XXX
 SG_ DAS_w049_eyeqVersionMismatch : 48|1@1+ (1,0) [0|1] "" Vector__XXX
 SG_ DAS_w050_aeb_event : 49|1@1+ (1,0) [0|1] "" Vector__XXX
 SG_ DAS_w051_radcEcuIssue : 50|1@1+ (1,0) [0|1] "" Vector__XXX
 SG_ DAS_w052_radcSensorIssue : 51|1@1+ (1,0) [0|1] "" Vector__XXX
 SG_ DAS_w053_radcCommIssue : 52|1@1+ (1,0) [0|1] "" Vector__XXX
 SG_ DAS_w054_camAutofix : 53|1@1+ (1,0) [0|1] "" Vector__XXX
 SG_ DAS_w055_radcVersionMismatch : 54|1@1+ (1,0) [0|1] "" Vector__XXX
 SG_ DAS_w056_diMia : 55|1@1+ (1,0) [0|1] "" Vector__XXX
 SG_ DAS_w057_mcuMia : 56|1@1+ (1,0) [0|1] "" Vector__XXX
 SG_ DAS_w058_epbMia : 57|1@1+ (1,0) [0|1] "" Vector__XXX
 SG_ DAS_w059_parkMia : 58|1@1+ (1,0) [0|1] "" Vector__XXX
 SG_ DAS_w060_fcw_event : 59|1@1+ (1,0) [0|1] "" Vector__XXX
 SG_ DAS_w061_airSuspensionMia : 60|1@1+ (1,0) [0|1] "" Vector__XXX
 SG_ DAS_w062_radcAlignment : 61|1@1+ (1,0) [0|1] "" Vector__XXX
 SG_ DAS_w063_parkVersionMismatch : 62|1@1+ (1,0) [0|1] "" Vector__XXX
 SG_ DAS_w064_epasMia : 63|1@1+ (1,0) [0|1] "" Vector__XXX

BO_ 874 DAS_warningMatrix1: 8 DAS
 SG_ DAS_w065_deserializerOvercurrent : 0|1@1+ (1,0) [0|1] "" Vector__XXX
 SG_ DAS_w066_deserializerLockLost : 1|1@1+ (1,0) [0|1] "" Vector__XXX
 SG_ DAS_w067_steeringAlignment : 2|1@1+ (1,0) [0|1] "" Vector__XXX
 SG_ DAS_w068_vlInconsistency : 3|1@1+ (1,0) [0|1] "" Vector__XXX
 SG_ DAS_w069_apcSpaceMasked : 4|1@1+ (1,0) [0|1] "" Vector__XXX
 SG_ DAS_w070_apcIncompleteCal : 5|1@1+ (1,0) [0|1] "" Vector__XXX
 SG_ DAS_w071_selfparkStarted : 6|1@1+ (1,0) [0|1] "" Vector__XXX
 SG_ DAS_w072_selfparkComplete : 7|1@1+ (1,0) [0|1] "" Vector__XXX
 SG_ DAS_w073_issueEscalatedLDW : 8|1@1+ (1,0) [0|1] "" Vector__XXX
 SG_ DAS_w074_inPathStationaryObst : 9|1@1+ (1,0) [0|1] "" Vector__XXX
 SG_ DAS_w075_scMia : 10|1@1+ (1,0) [0|1] "" Vector__XXX
 SG_ DAS_w076_mobilEyeSetC : 11|1@1+ (1,0) [0|1] "" Vector__XXX
 SG_ DAS_w077_pmmActive : 12|1@1+ (1,0) [0|1] "" Vector__XXX
 SG_ DAS_w078_pmmActive2 : 13|1@1+ (1,0) [0|1] "" Vector__XXX
 SG_ DAS_w079_edrAvailable : 14|1@1+ (1,0) [0|1] "" Vector__XXX
 SG_ DAS_w080_accFailedActivation : 15|1@1+ (1,0) [0|1] "" Vector__XXX
 SG_ DAS_w081_pmmActiveBraking : 16|1@1+ (1,0) [0|1] "" Vector__XXX
 SG_ DAS_w082_inPathFSviolation : 17|1@1+ (1,0) [0|1] "" Vector__XXX
 SG_ DAS_w083_inPathRADObject : 18|1@1+ (1,0) [0|1] "" Vector__XXX
 SG_ DAS_w084_pmmIPSO : 19|1@1+ (1,0) [0|1] "" Vector__XXX
 SG_ DAS_w085_pmmSteering : 20|1@1+ (1,0) [0|1] "" Vector__XXX
 SG_ DAS_w086_robCollision : 21|1@1+ (1,0) [0|1] "" Vector__XXX
 SG_ DAS_w087_DEPRECATED : 22|1@1+ (1,0) [0|1] "" Vector__XXX
 SG_ DAS_w088_DEPRECATED : 23|1@1+ (1,0) [0|1] "" Vector__XXX
 SG_ DAS_w089_DEPRECATED : 24|1@1+ (1,0) [0|1] "" Vector__XXX
 SG_ DAS_w090_DEPRECATED : 25|1@1+ (1,0) [0|1] "" Vector__XXX
 SG_ DAS_w091_DEPRECATED : 26|1@1+ (1,0) [0|1] "" Vector__XXX
 SG_ DAS_w092_DEPRECATED : 27|1@1+ (1,0) [0|1] "" Vector__XXX
 SG_ DAS_w093_DEPRECATED : 28|1@1+ (1,0) [0|1] "" Vector__XXX
 SG_ DAS_w094_DEPRECATED : 29|1@1+ (1,0) [0|1] "" Vector__XXX
 SG_ DAS_w095_DEPRECATED : 30|1@1+ (1,0) [0|1] "" Vector__XXX
 SG_ DAS_w096_DEPRECATED : 31|1@1+ (1,0) [0|1] "" Vector__XXX
 SG_ DAS_w097_DEPRECATED : 32|1@1+ (1,0) [0|1] "" Vector__XXX
 SG_ DAS_w098_DEPRECATED : 33|1@1+ (1,0) [0|1] "" Vector__XXX
 SG_ DAS_w099_DEPRECATED : 34|1@1+ (1,0) [0|1] "" Vector__XXX
 SG_ DAS_w100_DEPRECATED : 35|1@1+ (1,0) [0|1] "" Vector__XXX
 SG_ DAS_w101_DEPRECATED : 36|1@1+ (1,0) [0|1] "" Vector__XXX
 SG_ DAS_w102_DEPRECATED : 37|1@1+ (1,0) [0|1] "" Vector__XXX
 SG_ DAS_w103_robExperimentalAEB : 38|1@1+ (1,0) [0|1] "" Vector__XXX
 SG_ DAS_w104_DEPRECATED : 39|1@1+ (1,0) [0|1] "" Vector__XXX
 SG_ DAS_w105_DEPRECATED : 40|1@1+ (1,0) [0|1] "" Vector__XXX
 SG_ DAS_w106_torsionBarCalibrated : 41|1@1+ (1,0) [0|1] "" Vector__XXX

BO_ 841 DAS_warningMatrix2: 8 DAS
 SG_ DAS_w129_mainCamExtNotCal : 0|1@1+ (1,0) [0|1] "" Vector__XXX
 SG_ DAS_w130_narrowCamExtNotCal : 1|1@1+ (1,0) [0|1] "" Vector__XXX
 SG_ DAS_w131_mainCamCalSaved : 2|1@1+ (1,0) [0|1] "" Vector__XXX
 SG_ DAS_w132_narrowCamCalSaved : 3|1@1+ (1,0) [0|1] "" Vector__XXX
 SG_ DAS_w133_mainCamInitFault : 4|1@1+ (1,0) [0|1] "" Vector__XXX
 SG_ DAS_w134_narrowCamInitFault : 5|1@1+ (1,0) [0|1] "" Vector__XXX
 SG_ DAS_w135_fisheyeCamInitFault : 6|1@1+ (1,0) [0|1] "" Vector__XXX
 SG_ DAS_w136_lPillarCamInitFault : 7|1@1+ (1,0) [0|1] "" Vector__XXX
 SG_ DAS_w137_rPillarCamInitFault : 8|1@1+ (1,0) [0|1] "" Vector__XXX
 SG_ DAS_w138_lRepeatCamInitFault : 9|1@1+ (1,0) [0|1] "" Vector__XXX
 SG_ DAS_w139_rRepeatCamInitFault : 10|1@1+ (1,0) [0|1] "" Vector__XXX
 SG_ DAS_w140_backupCamInitFault : 11|1@1+ (1,0) [0|1] "" Vector__XXX
 SG_ DAS_w141_ECU_Thermal_Issue : 12|1@1+ (1,0) [0|1] "" Vector__XXX
 SG_ DAS_w142_fwdCamPitchProblem : 13|1@1+ (1,0) [0|1] "" Vector__XXX
 SG_ DAS_w143_IDF_event : 14|1@1+ (1,0) [0|1] "" Vector__XXX
 SG_ DAS_w144_selfieCamInitFault : 15|1@1+ (1,0) [0|1] "" Vector__XXX
 SG_ DAS_w171_fisheyeCamExtNotCal : 42|1@1+ (1,0) [0|1] "" Vector__XXX
 SG_ DAS_w172_lPillarCamExtNotCal : 43|1@1+ (1,0) [0|1] "" Vector__XXX
 SG_ DAS_w173_rPillarCamExtNotCal : 44|1@1+ (1,0) [0|1] "" Vector__XXX
 SG_ DAS_w174_lRepeatCamExtNotCal : 45|1@1+ (1,0) [0|1] "" Vector__XXX
 SG_ DAS_w175_rRepeatCamExtNotCal : 46|1@1+ (1,0) [0|1] "" Vector__XXX
 SG_ DAS_w177_fisheyeCamCalSaved : 48|1@1+ (1,0) [0|1] "" Vector__XXX
 SG_ DAS_w178_lPillarCamCalSaved : 49|1@1+ (1,0) [0|1] "" Vector__XXX
 SG_ DAS_w179_rPillarCamCalSaved : 50|1@1+ (1,0) [0|1] "" Vector__XXX
 SG_ DAS_w180_lRepeatCamCalSaved : 51|1@1+ (1,0) [0|1] "" Vector__XXX
 SG_ DAS_w181_rRepeatCamCalSaved : 52|1@1+ (1,0) [0|1] "" Vector__XXX

BO_ 1082 DAS_warningMatrix3: 8 DAS
 SG_ DAS_w193_camWindshieldUnclean : 0|1@1+ (1,0) [0|1] "" Vector__XXX
 SG_ DAS_w194_accDriverResumeRqrd : 1|1@1+ (1,0) [0|1] "" Vector__XXX
 SG_ DAS_w195_scwUnavailable : 2|1@1+ (1,0) [0|1] "" Vector__XXX
 SG_ DAS_w196_stopSignWarning : 3|1@1+ (1,0) [0|1] "" Vector__XXX
 SG_ DAS_w197_redLightWarning : 4|1@1+ (1,0) [0|1] "" Vector__XXX
 SG_ DAS_w198_tsrUnavailable : 5|1@1+ (1,0) [0|1] "" Vector__XXX
 SG_ DAS_w199_apcAbort : 6|1@1+ (1,0) [0|1] "" Vector__XXX
 SG_ DAS_w200_lcSlowdown : 7|1@1+ (1,0) [0|1] "" Vector__XXX
 SG_ DAS_w201_lcAborting : 8|1@1+ (1,0) [0|1] "" Vector__XXX
 SG_ DAS_w202_scwNoisyEnvironment : 9|1@1+ (1,0) [0|1] "" Vector__XXX
 SG_ DAS_w203_apcActivation : 10|1@1+ (1,0) [0|1] "" Vector__XXX
 SG_ DAS_w204_apcFinalFront : 11|1@1+ (1,0) [0|1] "" Vector__XXX
 SG_ DAS_w205_apcFinalRear : 12|1@1+ (1,0) [0|1] "" Vector__XXX
 SG_ DAS_w206_autosteerNotEnabled : 13|1@1+ (1,0) [0|1] "" Vector__XXX
 SG_ DAS_w207_autosteerUnavailable : 14|1@1+ (1,0) [0|1] "" Vector__XXX
 SG_ DAS_w208_rackDetected : 15|1@1+ (1,0) [0|1] "" Vector__XXX
 SG_ DAS_w209_autoSummonRequest : 16|1@1+ (1,0) [0|1] "" Vector__XXX
 SG_ DAS_w210_camObstrcted : 17|1@1+ (1,0) [0|1] "" Vector__XXX
 SG_ DAS_w211_accNoSeatBelt : 18|1@1+ (1,0) [0|1] "" Vector__XXX
 SG_ DAS_w212_lcUnavailableStrikeOut : 19|1@1+ (1,0) [0|1] "" Vector__XXX
 SG_ DAS_w213_autosteerStruckOut : 20|1@1+ (1,0) [0|1] "" Vector__XXX
 SG_ DAS_w214_driverNotIntracting : 21|1@1+ (1,0) [0|1] "" Vector__XXX
 SG_ DAS_w215_contDriverNotIntracting : 22|1@1+ (1,0) [0|1] "" Vector__XXX
 SG_ DAS_w216_driverOverriding : 23|1@1+ (1,0) [0|1] "" Vector__XXX
 SG_ DAS_w217_lcUnavailableSpeeding : 24|1@1+ (1,0) [0|1] "" Vector__XXX
 SG_ DAS_w218_lcSpeedExceededLimit : 25|1@1+ (1,0) [0|1] "" Vector__XXX
 SG_ DAS_w219_lcTempUnavailableSpeed : 26|1@1+ (1,0) [0|1] "" Vector__XXX
 SG_ DAS_w220_lcTempUnavailableRoad : 27|1@1+ (1,0) [0|1] "" Vector__XXX
 SG_ DAS_w221_accRadarBlind : 28|1@1+ (1,0) [0|1] "" Vector__XXX
 SG_ DAS_w222_accCameraBlind : 29|1@1+ (1,0) [0|1] "" Vector__XXX
 SG_ DAS_w223_accObjectInPath : 30|1@1+ (1,0) [0|1] "" Vector__XXX
 SG_ DAS_w224_accCameraCalibration : 31|1@1+ (1,0) [0|1] "" Vector__XXX
 SG_ DAS_w225_lcDegradedVisSpeedLmt : 32|1@1+ (1,0) [0|1] "" Vector__XXX
 SG_ DAS_w226_lcCamCalNeededSpeedLmt : 33|1@1+ (1,0) [0|1] "" Vector__XXX
 SG_ DAS_w227_virtualWallBlocked : 34|1@1+ (1,0) [0|1] "" Vector__XXX
 SG_ DAS_w228_DEPRECATED : 35|1@1+ (1,0) [0|1] "" Vector__XXX
 SG_ DAS_w229_alcUltrasoundDamaged : 36|1@1+ (1,0) [0|1] "" Vector__XXX
 SG_ DAS_w230_alcUltrasoundBlocked : 37|1@1+ (1,0) [0|1] "" Vector__XXX
 SG_ DAS_w231_idfEvent : 38|1@1+ (1,0) [0|1] "" Vector__XXX
 SG_ DAS_w232_laneChangeRequested : 39|1@1+ (1,0) [0|1] "" Vector__XXX

BO_ 1425 EPAS3S_alertLog: 8 EPAS3S
 SG_ EPAS3S_alertID M : 0|8@1+ (1,0) [0|255] "" Vector__XXX
 SG_ EPAS3S_alertState : 15|1@1+ (1,0) [0|1] "" Vector__XXX
 SG_ EPAS3S_a147_transitionReason m147 : 16|2@1+ (1,0) [0|3] "" Vector__XXX
 SG_ EPAS3S_a149_pcbTemp m149 : 16|8@1- (1,60) [-68|187] "degC" Vector__XXX
 SG_ EPAS3S_a150_pcbTemp m150 : 16|8@1- (1,60) [-68|187] "degC" Vector__XXX
 SG_ EPAS3S_a150_phaUMainPathCalcDiff m150 : 24|15@1+ (1,0) [0|32767] "Counts" Vector__XXX
 SG_ EPAS3S_a150_phaVMainPathCalcDiff m150 : 39|15@1+ (1,0) [0|32767] "Counts" Vector__XXX
 SG_ EPAS3S_a150_otherECUAssistStatus m150 : 54|1@1+ (1,0) [0|1] "" Vector__XXX
 SG_ EPAS3S_a155_vehicleSpeed m155 : 16|10@1+ (0.5,0) [0|511.5] "kph" Vector__XXX
 SG_ EPAS3S_a156_vehicleSpeed m156 : 16|10@1+ (0.5,0) [0|511.5] "kph" Vector__XXX
 SG_ EPAS3S_a160_currentSensorStatus m160 : 16|2@1+ (1,0) [0|3] "" Vector__XXX
 SG_ EPAS3S_a160_gateDriverStatus m160 : 18|2@1+ (1,0) [0|3] "" Vector__XXX
 SG_ EPAS3S_a160_highSideDisconnectFe m160 : 20|2@1+ (1,0) [0|3] "" Vector__XXX
 SG_ EPAS3S_a160_phaseDisconnectFetSt m160 : 22|2@1+ (1,0) [0|3] "" Vector__XXX
 SG_ EPAS3S_a160_inverterFetStatus m160 : 24|2@1+ (1,0) [0|3] "" Vector__XXX
 SG_ EPAS3S_a160_hsdFetFailShortTest m160 : 26|2@1+ (1,0) [0|3] "" Vector__XXX
 SG_ EPAS3S_a160_phaDisconnFailOpenTe m160 : 28|2@1+ (1,0) [0|3] "" Vector__XXX
 SG_ EPAS3S_a160_phaDisconnFailShortT m160 : 30|2@1+ (1,0) [0|3] "" Vector__XXX
 SG_ EPAS3S_a160_invFetInitTest m160 : 32|2@1+ (1,0) [0|3] "" Vector__XXX
 SG_ EPAS3S_a160_gateDrvrInitTest m160 : 34|2@1+ (1,0) [0|3] "" Vector__XXX
 SG_ EPAS3S_a160_latentFaultTestTimeo m160 : 36|1@1+ (1,0) [0|1] "" Vector__XXX
 SG_ EPAS3S_a161_pcoMinPhaseBCurrent m161 : 16|12@1- (0.1025,0) [-209.92|209.8175] "Amps" Vector__XXX
 SG_ EPAS3S_a161_pcoMaxPhaseBCurrent m161 : 28|12@1- (0.1025,0) [-209.92|209.8175] "Amps" Vector__XXX
 SG_ EPAS3S_a161_pcoMinPhaseACurrent m161 : 40|12@1- (0.1025,0) [-209.92|209.8175] "Amps" Vector__XXX
 SG_ EPAS3S_a161_pcoMaxPhaseACurrent m161 : 52|12@1- (0.1025,0) [-209.92|209.8175] "Amps" Vector__XXX
 SG_ EPAS3S_a162_vBridgeClosed m162 : 16|16@1+ (0.00537,0) [0|351.92295] "Volts" Vector__XXX
 SG_ EPAS3S_a162_vBridgeOpen m162 : 32|16@1+ (0.00537,0) [0|351.92295] "Volts" Vector__XXX
 SG_ EPAS3S_a163_gateDrvrStatusReg m163 : 16|11@1+ (1,0) [0|2047] "Counts" Vector__XXX
 SG_ EPAS3S_a163_gateDrvrDiag2Reg m163 : 27|9@1+ (1,0) [0|511] "Counts" Vector__XXX
 SG_ EPAS3S_a163_gateDrvrDiag1Reg m163 : 36|9@1+ (1,0) [0|511] "Counts" Vector__XXX
 SG_ EPAS3S_a163_gateDrvrDiag0Reg m163 : 45|9@1+ (1,0) [0|511] "Counts" Vector__XXX
 SG_ EPAS3S_a163_diagStatus m163 : 54|1@1+ (1,0) [0|1] "" Vector__XXX
 SG_ EPAS3S_a163_powerStatus m163 : 55|1@1+ (1,0) [0|1] "" Vector__XXX
 SG_ EPAS3S_a164_dcsRegister0x19 m164 : 16|16@1+ (1,0) [0|65535] "Counts" Vector__XXX
 SG_ EPAS3S_a164_currentSensorRailed m164 : 32|1@1+ (1,0) [0|1] "" Vector__XXX

BO_TX_BU_ 1113 : APS;
BO_TX_BU_ 848 : APS;
BO_TX_BU_ 784 : APS;
BO_TX_BU_ 1465 : DAS;
BO_TX_BU_ 401 : DAS;
BO_TX_BU_ 583 : DAS;
BO_TX_BU_ 1497 : DAS;
BO_TX_BU_ 970 : DAS;
BO_TX_BU_ 1337 : DAS;
BO_TX_BU_ 569 : DAS;
BO_TX_BU_ 921 : DAS;
BO_TX_BU_ 905 : DAS;
BO_TX_BU_ 1625 : DAS;
BO_TX_BU_ 586 : DAS;
BO_TX_BU_ 810 : DAS;
BO_TX_BU_ 874 : DAS;
BO_TX_BU_ 841 : DAS;
BO_TX_BU_ 1082 : DAS;
BO_TX_BU_ 1425 : EPAS3S;
CM_ BO_ 1113 "Driver assistance computer (secondary) message: warning matrix2; frame length from the layout, not yet observed on a vehicle bus";
CM_ SG_ 1113 APS_w129_ECU_Power_Issue "Driver assistance computer (secondary): w129 ECU power issue";
CM_ SG_ 1113 APS_w130_ECU_Thermal_Issue "Driver assistance computer (secondary): w130 ECU thermal issue";
CM_ SG_ 1113 APS_w131_trap_exception "Driver assistance computer (secondary): w131 trap exception";
CM_ SG_ 1113 APS_w132_appVersionMismatch "Driver assistance computer (secondary): w132 app version mismatch";
CM_ SG_ 1113 APS_w133_ETHSwitchError "Driver assistance computer (secondary): w133 ETH switch error";
CM_ SG_ 1113 APS_w134_appMia "Driver assistance computer (secondary): w134 app mia";
CM_ SG_ 1113 APS_w135_appCritical "Driver assistance computer (secondary): w135 app critical";
CM_ SG_ 1113 APS_w136_gpsDisabled "Driver assistance computer (secondary): w136 gps disabled";
CM_ SG_ 1113 APS_w137_gpsFaultReset "Driver assistance computer (secondary): w137 gps fault reset";
CM_ SG_ 1113 APS_w138_gpsComIssue "Driver assistance computer (secondary): w138 gps com issue";
CM_ SG_ 1113 APS_w139_udpBufferOverflow "Driver assistance computer (secondary): w139 udp buffer overflow";
CM_ SG_ 1113 APS_w140_vcfrontMiaVehicleBus "Driver assistance computer (secondary): w140 vcfront mia vehicle bus";
CM_ SG_ 1113 APS_w141_rcmMiaPartyBus "Driver assistance computer (secondary): w141 rcm mia party bus";
CM_ SG_ 1113 APS_w142_diMiaPartyBus "Driver assistance computer (secondary): w142 di mia party bus";
CM_ SG_ 1113 APS_w143_espMiaPartyBus "Driver assistance computer (secondary): w143 esp mia party bus";
CM_ SG_ 1113 APS_w144_vcleftMiaPartyBus "Driver assistance computer (secondary): w144 vcleft mia party bus";
CM_ SG_ 1113 APS_w145_vcrightMiaPartyBus "Driver assistance computer (secondary): w145 vcright mia party bus";
CM_ SG_ 1113 APS_w146_epas3pMiaPartyBus "Driver assistance computer (secondary): w146 epas3p mia party bus";
CM_ SG_ 1113 APS_w147_vcleftMiaVehBus "Driver assistance computer (secondary): w147 vcleft mia veh bus";
CM_ SG_ 1113 APS_w148_vcrightMiaVehBus "Driver assistance computer (secondary): w148 vcright mia veh bus";
CM_ SG_ 1113 APS_w149_epblMiaVehBus "Driver assistance computer (secondary): w149 epbl mia veh bus";
CM_ SG_ 1113 APS_w150_sccmMiaVehBus "Driver assistance computer (secondary): w150 sccm mia veh bus";
CM_ SG_ 1113 APS_w151_apRecovered "Driver assistance computer (secondary): w151 ap recovered";
CM_ SG_ 1113 APS_w152_gpsFusionStatus "Driver assistance computer (secondary): w152 gps fusion status";
CM_ SG_ 1113 APS_w153_eacInhibit "Driver assistance computer (secondary): w153 eac inhibit";
CM_ SG_ 1113 APS_w155_ethLwipError "Driver assistance computer (secondary): w155 eth lwip error";
CM_ SG_ 1113 APS_w156_lwipAssert "Driver assistance computer (secondary): w156 lwip assert";
CM_ SG_ 1113 APS_w157_autopilotReboot "Driver assistance computer (secondary): w157 autopilot reboot";
CM_ SG_ 1113 APS_w158_apbMia "Driver assistance computer (secondary): w158 apb mia";
CM_ SG_ 1113 APS_w159_apbCritical "Driver assistance computer (secondary): w159 apb critical";
CM_ SG_ 1113 APS_w160_apbVersionMismatch "Driver assistance computer (secondary): w160 apb version mismatch";
CM_ SG_ 1113 APS_w161_gpsAntennaDisconnected "Driver assistance computer (secondary): w161 gps antenna disconnected";
CM_ SG_ 1113 APS_w162_TurboA_DisRegPgoodErr "Driver assistance computer (secondary): w162 turbo a dis reg pgood err";
CM_ SG_ 1113 APS_w163_TurboA_DisRegNFault "Driver assistance computer (secondary): w163 turbo a dis reg n fault";
CM_ SG_ 1113 APS_w164_TurboA_12VFuseFault "Driver assistance computer (secondary): w164 turbo a 12 v fuse fault";
CM_ SG_ 1113 APS_w165_TurboA_Temp_NOS "Driver assistance computer (secondary): w165 turbo a temp NOS";
CM_ SG_ 1113 APS_w166_TurboA_SMSLockStepErr "Driver assistance computer (secondary): w166 turbo a SMS lock step err";
CM_ SG_ 1113 APS_w167_TurboA_TMU_Throttle "Driver assistance computer (secondary): w167 turbo a TMU throttle";
CM_ SG_ 1113 APS_w168_TurboA_SMS_WDOG "Driver assistance computer (secondary): w168 turbo a SMS WDOG";
CM_ SG_ 1113 APS_w169_TurboA_SCS_LKUP "Driver assistance computer (secondary): w169 turbo a SCS LKUP";
CM_ SG_ 1113 APS_w170_TurboA_A72_watchdog "Driver assistance computer (secondary): w170 turbo a A72 watchdog";
CM_ SG_ 1113 APS_w171_TurboA_SMS_taskUtilErr "Driver assistance computer (secondary): w171 turbo a SMS task util err";
CM_ SG_ 1113 APS_w172_apFeaturesUnavailable "Driver assistance computer (secondary): w172 ap features unavailable";
CM_ SG_ 1113 APS_w178_TurboB_DisRegPgoodErr "Driver assistance computer (secondary): w178 turbo b dis reg pgood err";
CM_ SG_ 1113 APS_w179_TurboB_DisRegNFault "Driver assistance computer (secondary): w179 turbo b dis reg n fault";
CM_ SG_ 1113 APS_w180_TurboB_12VFuseFault "Driver assistance computer (secondary): w180 turbo b 12 v fuse fault";
CM_ SG_ 1113 APS_w181_TurboB_Temp_NOS "Driver assistance computer (secondary): w181 turbo b temp NOS";
CM_ SG_ 1113 APS_w182_TurboB_SMSLockStepErr "Driver assistance computer (secondary): w182 turbo b SMS lock step err";
CM_ SG_ 1113 APS_w183_TurboB_TMU_Throttle "Driver assistance computer (secondary): w183 turbo b TMU throttle";
CM_ SG_ 1113 APS_w184_TurboB_SMS_WDOG "Driver assistance computer (secondary): w184 turbo b SMS WDOG";
CM_ SG_ 1113 APS_w185_TurboB_SCS_LKUP "Driver assistance computer (secondary): w185 turbo b SCS LKUP";
CM_ SG_ 1113 APS_w186_TurboB_A72_watchdog "Driver assistance computer (secondary): w186 turbo b A72 watchdog";
CM_ SG_ 1113 APS_w187_TurboB_SMS_taskUtilErr "Driver assistance computer (secondary): w187 turbo b SMS task util err";
CM_ SG_ 1113 APS_w188_otherTurboUartMIA "Driver assistance computer (secondary): w188 other turbo uart MIA";
CM_ SG_ 1113 APS_w189_vcfrontMiaPartyBus "Driver assistance computer (secondary): w189 vcfront mia party bus";
CM_ SG_ 1113 APS_w190_iboosterMia "Driver assistance computer (secondary): w190 ibooster mia";
CM_ SG_ 1113 APS_w191_timesyncError "Driver assistance computer (secondary): w191 timesync error";
CM_ SG_ 1113 APS_w192_CANFault "Driver assistance computer (secondary): w192 CAN fault";
CM_ BO_ 848 "Driver assistance computer (secondary) message: warning matrix3; frame length from the layout, not yet observed on a vehicle bus";
CM_ SG_ 848 APS_w193_camWindshieldUnclean "Driver assistance computer (secondary): w193 cam windshield unclean";
CM_ SG_ 848 APS_w194_accDriverResumeRqrd "Driver assistance computer (secondary): w194 acc driver resume rqrd";
CM_ SG_ 848 APS_w195_scwUnavailable "Driver assistance computer (secondary): w195 scw unavailable";
CM_ SG_ 848 APS_w196_stopSignWarning "Driver assistance computer (secondary): w196 stop sign warning";
CM_ SG_ 848 APS_w197_redLightWarning "Driver assistance computer (secondary): w197 red light warning";
CM_ SG_ 848 APS_w198_tsrUnavailable "Driver assistance computer (secondary): w198 tsr unavailable";
CM_ SG_ 848 APS_w199_apcAbort "Driver assistance computer (secondary): w199 apc abort";
CM_ SG_ 848 APS_w200_lcSlowdown "Driver assistance computer (secondary): w200 lc slowdown";
CM_ SG_ 848 APS_w201_lcAborting "Driver assistance computer (secondary): w201 lc aborting";
CM_ SG_ 848 APS_w202_scwNoisyEnvironment "Driver assistance computer (secondary): w202 scw noisy environment";
CM_ SG_ 848 APS_w203_apcActivation "Driver assistance computer (secondary): w203 apc activation";
CM_ SG_ 848 APS_w204_apcFinalFront "Driver assistance computer (secondary): w204 apc final front";
CM_ SG_ 848 APS_w205_apcFinalRear "Driver assistance computer (secondary): w205 apc final rear";
CM_ SG_ 848 APS_w206_autosteerNotEnabled "Driver assistance computer (secondary): w206 autosteer not enabled";
CM_ SG_ 848 APS_w207_autosteerUnavailable "Driver assistance computer (secondary): w207 autosteer unavailable";
CM_ SG_ 848 APS_w208_rackDetected "Driver assistance computer (secondary): w208 rack detected";
CM_ SG_ 848 APS_w209_autoSummonRequest "Driver assistance computer (secondary): w209 auto summon request";
CM_ SG_ 848 APS_w210_camObstrcted "Driver assistance computer (secondary): w210 cam obstrcted";
CM_ SG_ 848 APS_w211_accNoSeatBelt "Driver assistance computer (secondary): w211 acc no seat belt";
CM_ SG_ 848 APS_w212_lcUnavailableStrikeOut "Driver assistance computer (secondary): w212 lc unavailable strike out";
CM_ SG_ 848 APS_w213_autosteerStruckOut "Driver assistance computer (secondary): w213 autosteer struck out";
CM_ SG_ 848 APS_w214_driverNotIntracting "Driver assistance computer (secondary): w214 driver not intracting";
CM_ SG_ 848 APS_w215_contDriverNotIntracting "Driver assistance computer (secondary): w215 cont driver not intracting";
CM_ SG_ 848 APS_w216_driverOverriding "Driver assistance computer (secondary): w216 driver overriding";
CM_ SG_ 848 APS_w217_lcUnavailableSpeeding "Driver assistance computer (secondary): w217 lc unavailable speeding";
CM_ SG_ 848 APS_w218_lcSpeedExceededLimit "Driver assistance computer (secondary): w218 lc speed exceeded limit";
CM_ SG_ 848 APS_w219_lcTempUnavailableSpeed "Driver assistance computer (secondary): w219 lc temp unavailable speed";
CM_ SG_ 848 APS_w220_lcTempUnavailableRoad "Driver assistance computer (secondary): w220 lc temp unavailable road";
CM_ SG_ 848 APS_w221_accRadarBlind "Driver assistance computer (secondary): w221 acc radar blind";
CM_ SG_ 848 APS_w222_accCameraBlind "Driver assistance computer (secondary): w222 acc camera blind";
CM_ SG_ 848 APS_w223_accObjectInPath "Driver assistance computer (secondary): w223 acc object in path";
CM_ SG_ 848 APS_w224_accCameraCalibration "Driver assistance computer (secondary): w224 acc camera calibration";
CM_ SG_ 848 APS_w225_lcDegradedVisSpeedLmt "Driver assistance computer (secondary): w225 lc degraded vis speed lmt";
CM_ SG_ 848 APS_w226_lcCamCalNeededSpeedLmt "Driver assistance computer (secondary): w226 lc cam cal needed speed lmt";
CM_ SG_ 848 APS_w227_virtualWallBlocked "Driver assistance computer (secondary): w227 virtual wall blocked";
CM_ SG_ 848 APS_w228_DEPRECATED "Driver assistance computer (secondary): w228 DEPRECATED";
CM_ SG_ 848 APS_w229_alcUltrasoundDamaged "Driver assistance computer (secondary): w229 alc ultrasound damaged";
CM_ SG_ 848 APS_w230_alcUltrasoundBlocked "Driver assistance computer (secondary): w230 alc ultrasound blocked";
CM_ SG_ 848 APS_w231_idfEvent "Driver assistance computer (secondary): w231 idf event";
CM_ SG_ 848 APS_w232_laneChangeRequested "Driver assistance computer (secondary): w232 lane change requested";
CM_ SG_ 848 APS_w235_a72LoopDetected "Driver assistance computer (secondary): w235 a72 loop detected";
CM_ SG_ 848 APS_w236_canSharedMemError "Driver assistance computer (secondary): w236 can shared mem error";
CM_ SG_ 848 APS_w237_faultMgrEventDetected "Driver assistance computer (secondary): w237 fault mgr event detected";
CM_ SG_ 848 APS_w238_resetReason "Driver assistance computer (secondary): w238 reset reason";
CM_ SG_ 848 APS_w241_ddrInitFailures "Driver assistance computer (secondary): w241 ddr init failures";
CM_ SG_ 848 APS_w242_tripMBISTFailure "Driver assistance computer (secondary): w242 trip MBIST failure";
CM_ SG_ 848 APS_w243_tripHWErrorStatus "Driver assistance computer (secondary): w243 trip HW error status";
CM_ SG_ 848 APS_w244_gpuHWFaultStatus "Driver assistance computer (secondary): w244 gpu HW fault status";
CM_ SG_ 848 APS_w245_eloopRxFromUnexpectedSo "Driver assistance computer (secondary): w245 eloop rx from unexpected source MAC";
CM_ SG_ 848 APS_w246_ethloopSwitchPortLinkDo "Driver assistance computer (secondary): w246 ethloop switch port link down";
CM_ SG_ 848 APS_w247_ethernetFrameError "Driver assistance computer (secondary): w247 ethernet frame error";
CM_ SG_ 848 APS_w248_ethloopSwitchPoorSqi "Driver assistance computer (secondary): w248 ethloop switch poor sqi";
CM_ SG_ 848 APS_w249_ufsFailures "Driver assistance computer (secondary): w249 ufs failures";
CM_ SG_ 848 APS_w250_ethloopSwitchMemUsageTo "Driver assistance computer (secondary): w250 ethloop switch mem usage too high port2";
CM_ SG_ 848 APS_w251_ethloopSwitchMemUsageTo "Driver assistance computer (secondary): w251 ethloop switch mem usage too high port3";
CM_ SG_ 848 APS_w252_ethSwitchPortLinkDown "Driver assistance computer (secondary): w252 eth switch port link down";
CM_ SG_ 848 APS_w253_powerStateTimeout "Driver assistance computer (secondary): w253 power state timeout";
CM_ SG_ 848 APS_w254_sleepStateTimeout "Driver assistance computer (secondary): w254 sleep state timeout";
CM_ SG_ 848 APS_w255_bootHealth "Driver assistance computer (secondary): w255 boot health";
CM_ BO_ 784 "Driver assistance computer (secondary) message: warning matrix4; frame length from the layout, not yet observed on a vehicle bus";
CM_ SG_ 784 APS_w257_assertFailure "Driver assistance computer (secondary): w257 assert failure";
CM_ SG_ 784 APS_w258_qspiFlashSectorChecksum "Driver assistance computer (secondary): w258 qspi flash sector checksum mismatch";
CM_ SG_ 784 APS_w259_qspiFailure "Driver assistance computer (secondary): w259 qspi failure";
CM_ SG_ 784 APS_w260_pgoodFailure "Driver assistance computer (secondary): w260 pgood failure";
CM_ SG_ 784 APS_w261_vrmFaultGrpA "Driver assistance computer (secondary): w261 vrm fault grp a";
CM_ SG_ 784 APS_w262_vrmFaultGrpB "Driver assistance computer (secondary): w262 vrm fault grp b";
CM_ SG_ 784 APS_w263_vrmFaultGrpC "Driver assistance computer (secondary): w263 vrm fault grp c";
CM_ SG_ 784 APS_w264_ddrPhy0Failures "Driver assistance computer (secondary): w264 ddr phy0 failures";
CM_ SG_ 784 APS_w265_ddrPhy1Failures "Driver assistance computer (secondary): w265 ddr phy1 failures";
CM_ SG_ 784 APS_w266_ddrPhy2Failures "Driver assistance computer (secondary): w266 ddr phy2 failures";
CM_ SG_ 784 APS_w267_ddrPhy3Failures "Driver assistance computer (secondary): w267 ddr phy3 failures";
CM_ SG_ 784 APS_w268_ddrControllerFailures "Driver assistance computer (secondary): w268 ddr controller failures";
CM_ SG_ 784 APS_w269_ethSwitchRxPageCountToo "Driver assistance computer (secondary): w269 eth switch rx page count too high port0 3";
CM_ SG_ 784 APS_w270_ethSwitchRxPageCountToo "Driver assistance computer (secondary): w270 eth switch rx page count too high port4 7";
CM_ SG_ 784 APS_w271_ddrScheduler0EccErrors "Driver assistance computer (secondary): w271 ddr scheduler0 ecc errors";
CM_ SG_ 784 APS_w272_ddrScheduler1EccErrors "Driver assistance computer (secondary): w272 ddr scheduler1 ecc errors";
CM_ SG_ 784 APS_w273_ddrScheduler2EccErrors "Driver assistance computer (secondary): w273 ddr scheduler2 ecc errors";
CM_ SG_ 784 APS_w274_ddrScheduler3EccErrors "Driver assistance computer (secondary): w274 ddr scheduler3 ecc errors";
CM_ SG_ 784 APS_w275_ddrScheduler4EccErrors "Driver assistance computer (secondary): w275 ddr scheduler4 ecc errors";
CM_ SG_ 784 APS_w276_ddrScheduler5EccErrors "Driver assistance computer (secondary): w276 ddr scheduler5 ecc errors";
CM_ SG_ 784 APS_w277_ddrScheduler6EccErrors "Driver assistance computer (secondary): w277 ddr scheduler6 ecc errors";
CM_ SG_ 784 APS_w278_ddrScheduler7EccErrors "Driver assistance computer (secondary): w278 ddr scheduler7 ecc errors";
CM_ SG_ 784 APS_w279_ufsPartitionError "Driver assistance computer (secondary): w279 ufs partition error";
CM_ SG_ 784 APS_w280_pepsMia "Driver assistance computer (secondary): w280 peps mia";
CM_ SG_ 784 APS_w281_rsaMia "Driver assistance computer (secondary): w281 rsa mia";
CM_ SG_ 784 APS_w282_smmuError "Driver assistance computer (secondary): w282 smmu error";
CM_ SG_ 784 APS_w283_psfaMia "Driver assistance computer (secondary): w283 psfa mia";
CM_ SG_ 784 APS_w284_cam12VBuckBoostAPwrIssu "Driver assistance computer (secondary): w284 cam12 v buck boost a pwr issue";
CM_ SG_ 784 APS_w285_cam12VBuckBoostBPwrIssu "Driver assistance computer (secondary): w285 cam12 v buck boost b pwr issue";
CM_ SG_ 784 APS_w286_cam12VEFuseAPrimaryIssu "Driver assistance computer (secondary): w286 cam12 VE fuse a primary issue";
CM_ SG_ 784 APS_w287_cam12VEFuseASecondaryIs "Driver assistance computer (secondary): w287 cam12 VE fuse a secondary issue";
CM_ SG_ 784 APS_w288_brakeboosterMia "Driver assistance computer (secondary): w288 brakebooster mia";
CM_ SG_ 784 APS_w289_turboTemperatureWarning "Driver assistance computer (secondary): w289 turbo temperature warning";
CM_ SG_ 784 APS_w290_cam12VBuckBoostBPwrRing "Driver assistance computer (secondary): w290 cam12 v buck boost b pwr ringing";
CM_ SG_ 784 APS_w291_eplannerError "Driver assistance computer (secondary): w291 eplanner error";
CM_ SG_ 784 APS_w292_CH_busOff "Driver assistance computer (secondary): w292 CH bus off";
CM_ SG_ 784 APS_w293_PARTY_busOff "Driver assistance computer (secondary): w293 PARTY bus off";
CM_ SG_ 784 APS_w294_VEH_busOff "Driver assistance computer (secondary): w294 VEH bus off";
CM_ SG_ 784 APS_w295_PT_busOff "Driver assistance computer (secondary): w295 PT bus off";
CM_ SG_ 784 APS_w296_wdogMonTaskDeadlineMiss "Driver assistance computer (secondary): w296 wdog mon task deadline miss";
CM_ SG_ 784 APS_w297_earlyWDogAlert "Driver assistance computer (secondary): w297 early w dog alert";
CM_ SG_ 784 APS_w298_cpuToApCanSharedMemErro "Driver assistance computer (secondary): w298 cpu to ap can shared mem error";
CM_ SG_ 784 APS_w299_apToCpuCanSharedMemErro "Driver assistance computer (secondary): w299 ap to cpu can shared mem error";
CM_ SG_ 784 APS_w300_sharedMemoryAccessError "Driver assistance computer (secondary): w300 shared memory access error";
CM_ SG_ 784 APS_w301_nocTimeoutDetected "Driver assistance computer (secondary): w301 noc timeout detected";
CM_ SG_ 784 APS_w302_canAPShmFifoFull "Driver assistance computer (secondary): w302 can AP shm fifo full";
CM_ SG_ 784 APS_w303_canAPShmFifoEmpty "Driver assistance computer (secondary): w303 can AP shm fifo empty";
CM_ SG_ 784 APS_w304_dataAbort "Driver assistance computer (secondary): w304 data abort";
CM_ SG_ 784 APS_w305_gpsPgoodFailure "Driver assistance computer (secondary): w305 gps pgood failure";
CM_ SG_ 784 APS_w306_ethPgoodFailure "Driver assistance computer (secondary): w306 eth pgood failure";
CM_ SG_ 784 APS_w307_eccEventDetected "Driver assistance computer (secondary): w307 ecc event detected";
CM_ SG_ 784 APS_w308_pmicErrorDetected "Driver assistance computer (secondary): w308 pmic error detected";
CM_ SG_ 784 APS_w309_ethBridgeDown "Driver assistance computer (secondary): w309 eth bridge down";
CM_ SG_ 784 APS_w310_wakeBootMetrics "Driver assistance computer (secondary): w310 wake boot metrics";
CM_ SG_ 784 APS_w311_apbdgDasMia "Driver assistance computer (secondary): w311 apbdg das mia";
CM_ SG_ 784 APS_w312_apbdgApMia "Driver assistance computer (secondary): w312 apbdg ap mia";
CM_ SG_ 784 APS_w313_BDY_busOff "Driver assistance computer (secondary): w313 BDY bus off";
CM_ SG_ 784 APS_w315_epas3pMiaBdyBus "Driver assistance computer (secondary): w315 epas3p mia bdy bus";
CM_ SG_ 784 APS_w316_apBootHealth "Driver assistance computer (secondary): w316 ap boot health";
CM_ SG_ 784 APS_w317_uiMia "Driver assistance computer (secondary): w317 ui mia";
CM_ SG_ 784 APS_w318_ethernetNetworkBufferHi "Driver assistance computer (secondary): w318 ethernet network buffer high watermark";
CM_ SG_ 784 APS_w319_vehDasImposterDetected "Driver assistance computer (secondary): w319 veh das imposter detected";
CM_ SG_ 784 APS_w320_eplannerPreconditionsMe "Driver assistance computer (secondary): w320 eplanner preconditions met";
CM_ BO_ 1465 "Driver assistance computer message: alert log; frame length from the layout, not yet observed on a vehicle bus";
CM_ SG_ 1465 DAS_alertID "Driver assistance computer: alert ID";
CM_ SG_ 1465 DAS_alertState "Driver assistance computer: alert state";
CM_ SG_ 1465 DAS_sw073_escalateLDWs "Driver assistance computer: sw073 escalate LD ws";
CM_ SG_ 1465 DAS_sw073_silentEscalatedLDW "Driver assistance computer: sw073 silent escalated LDW";
CM_ SG_ 1465 DAS_sw073_escalateLDWreason "Driver assistance computer: sw073 escalate LD wreason";
CM_ SG_ 1465 DAS_sw073_rawMobileyeLDW "Driver assistance computer: sw073 raw mobileye LDW";
CM_ SG_ 1465 DAS_sw073_freespaceLDW "Driver assistance computer: sw073 freespace LDW";
CM_ SG_ 1465 DAS_sw073_freespaceLeftC0 "Driver assistance computer: sw073 freespace left C0";
CM_ SG_ 1465 DAS_sw073_freespaceRightC0 "Driver assistance computer: sw073 freespace right C0";
CM_ SG_ 1465 DAS_sw073_freespaceLeftC1 "Driver assistance computer: sw073 freespace left C1";
CM_ SG_ 1465 DAS_sw073_freespaceRightC1 "Driver assistance computer: sw073 freespace right C1";
CM_ SG_ 1465 DAS_sw073_freespaceLeftFarZ "Driver assistance computer: sw073 freespace left far z";
CM_ SG_ 1465 DAS_sw073_freespaceRightFarZ "Driver assistance computer: sw073 freespace right far z";
CM_ SG_ 1465 DAS_sw230_sensor1Blocked "Driver assistance computer: sw230 sensor1 blocked";
CM_ SG_ 1465 DAS_sw230_sensor2Blocked "Driver assistance computer: sw230 sensor2 blocked";
CM_ SG_ 1465 DAS_sw230_sensor3Blocked "Driver assistance computer: sw230 sensor3 blocked";
CM_ SG_ 1465 DAS_sw230_sensor4Blocked "Driver assistance computer: sw230 sensor4 blocked";
CM_ SG_ 1465 DAS_sw230_sensor5Blocked "Driver assistance computer: sw230 sensor5 blocked";
CM_ SG_ 1465 DAS_sw230_sensor6Blocked "Driver assistance computer: sw230 sensor6 blocked";
CM_ SG_ 1465 DAS_sw230_sensor7Blocked "Driver assistance computer: sw230 sensor7 blocked";
CM_ SG_ 1465 DAS_sw230_sensor8Blocked "Driver assistance computer: sw230 sensor8 blocked";
CM_ SG_ 1465 DAS_sw230_sensor9Blocked "Driver assistance computer: sw230 sensor9 blocked";
CM_ SG_ 1465 DAS_sw230_sensor10Blocked "Driver assistance computer: sw230 sensor10 blocked";
CM_ SG_ 1465 DAS_sw230_sensor11Blocked "Driver assistance computer: sw230 sensor11 blocked";
CM_ SG_ 1465 DAS_sw230_sensor12Blocked "Driver assistance computer: sw230 sensor12 blocked";
CM_ BO_ 401 "Driver assistance computer message: autonomy debug info; frame length from the layout, not yet observed on a vehicle bus";
CM_ SG_ 401 DAS_rmfActive "Driver assistance computer: rmf active";
CM_ SG_ 401 DAS_autonomyUnsupervisedActive "Reports when the Robotaxi Unsupervised (no takeover) autonomy mode is active";
CM_ SG_ 401 DAS_autonomyUnavailableReason "Reports the reason for Autonomy being unavailable";
CM_ BO_ 583 "Driver assistance computer message: autopilot debug; frame length from the layout, not yet observed on a vehicle bus";
CM_ SG_ 583 DAS_roadEstimator "Driver assistance computer: road estimator";
CM_ SG_ 583 DAS_arbiterBehavior "Which behavior task the arbiter has selected and sent to the controller";
CM_ SG_ 583 DAS_mapAvailability "Driver assistance computer: map availability";
CM_ SG_ 583 DAS_controllerRef "Driver assistance computer: controller ref";
CM_ SG_ 583 DAS_alcInternalState "Reports the internal state of the Automatic Lane Change (ALC) machine.";
CM_ SG_ 583 DAS_behaviorReport "Which target source are we controlling for longitudinally.";
CM_ SG_ 583 DAS_constructionZone "Driver assistance computer: construction zone";
CM_ SG_ 583 DAS_controllerHealth "Driver assistance computer: controller health";
CM_ SG_ 583 DAS_controlDistance "Driver assistance computer: control distance";
CM_ SG_ 583 DAS_autopilotAbortReason "Driver assistance computer: autopilot abort reason";
CM_ SG_ 583 DAS_rqstedBehaviorStatus "Indicates the autopilot behavior state with respect to automatic lane change.";
CM_ SG_ 583 DAS_forkState "Reports the internal state of the mission planner fork state machine.";
CM_ SG_ 583 DAS_laneChangeState "Indicates the state of the lane change state machine.";
CM_ SG_ 583 DAS_lastWatchdogCode "Tracks the last APP task to have triggered a Watchdog reset.";
CM_ BO_ 1497 "Driver assistance computer message: car log; frame length from the layout, not yet observed on a vehicle bus";
CM_ SG_ 1497 DAS_carLogMultiplexer "Driver assistance computer: car log multiplexer";
CM_ SG_ 1497 DAS_radarTarget5_dx "Measures the longitudinal distance from the radar to the nearest in-path stationary radar target.";
CM_ SG_ 1497 DAS_radarTarget1_dx "The longitudinal distance from the radar to radar target 1 (closest in-path vehicle)";
CM_ SG_ 1497 DAS_radarTarget1_VxRel "Measures the relative longitudinal velocity to the Adaptive Cruise Control (ACC) radar target 1.";
CM_ SG_ 1497 DAS_mobileyeVehAebFlag "Driver assistance computer: mobileye veh aeb flag";
CM_ SG_ 1497 DAS_mobileyePedAebFlag "Driver assistance computer: mobileye ped aeb flag";
CM_ SG_ 1497 DAS_mobileyeIPSOapproved "Driver assistance computer: mobileye IPS oapproved";
CM_ SG_ 1497 DAS_fcmSteeringOverride "Driver assistance computer: fcm steering override";
CM_ SG_ 1497 DAS_fcmCollisionStage3Checks "Reports the cross checks in the forward collision monitor.";
CM_ SG_ 1497 DAS_fcmThreatAssesmentMode "Driver assistance computer: fcm threat assesment mode";
CM_ SG_ 1497 DAS_constructionArea "Identifies construction area using the output of the 'scene tag' neural net.";
CM_ SG_ 1497 DAS_restrictionLowSpeedTraffic "Reports lane change restriction for low speed traffic.";
CM_ SG_ 1497 DAS_associated_rad_object "Indicates which radar target is associated with the vision object for Forward Collision Mitigation (FCM).";
CM_ SG_ 1497 DAS_LC_handsOnReason "Detects which hands on reason triggered the visual or audible hands-on-warning.";
CM_ SG_ 1497 DAS_ACC_camStatus "Driver assistance computer: ACC cam status";
CM_ SG_ 1497 DAS_aeb_not_activating_reason "Indicates the underlying reason why the next gen LCM AEB did not activate (not yet relevant)";
CM_ SG_ 1497 DAS_handsOnDetected "Driver assistance computer: hands on detected; raw 0 = signal not available (SNA)";
CM_ SG_ 1497 DAS_driveOnNavUnavailableReason "The high level reason why Navigate on Autopilot is not available.";
CM_ SG_ 1497 DAS_accUnavailableReason "The high level reason why ACC is not available.";
CM_ SG_ 1497 DAS_pmmNotActivatingReason "The high level reason why PMM v2 is not activating.";
CM_ SG_ 1497 DAS_desiredTarget_dx "Measures the distance to lead vehicle, or vehicle in the ego lane; raw 255 = signal not available (SNA)";
CM_ SG_ 1497 DAS_radarTarget2_dx "Measures the longitudinal distance from the radar to radar target 2, the 2nd closest in-path vehicle.";
CM_ SG_ 1497 DAS_radarTarget3_dx "Measures the longitudinal distance from the radar to the nearest vehicle in the right lane.";
CM_ SG_ 1497 DAS_radarTarget4_dx "Measures the longitudinal distance from the radar to the nearest vehicle in the left lane.";
CM_ SG_ 1497 DAS_closestInLaneTargetDx "Measures the longitudinal distance from front fascia to closest in-path object.";
CM_ SG_ 1497 DAS_secondInLaneTargetDx "Measures the longitudinal distance from front fascia to 2nd closest in-path object.";
CM_ SG_ 1497 DAS_closestLeftLaneTargetDx "Measures the longitudinal distance from front fascia to closest object in the left lane.";
CM_ SG_ 1497 DAS_closestRightLaneTargetDx "Measures the longitudinal distance from front fascia to closest object in the right lane.";
CM_ SG_ 1497 DAS_closestInLaneTargetVxRel "Measures the relative longitudinal velocity of closest in-path object.";
CM_ BO_ 970 "Driver assistance computer message: gps status; frame length from the layout, not yet observed on a vehicle bus";
CM_ SG_ 970 DAS_gpsStatusMultiplexer "Driver assistance computer: gps status multiplexer";
CM_ SG_ 970 DAS_gpsTransportModeState "Indicates if the transport mode algorithm detects the car is in transport mode.";
CM_ SG_ 970 DAS_gpsSatsInUseHardware "The number of GPS satellites currently in use by hardware solution.";
CM_ SG_ 970 DAS_gpsRejectingSatData "Indicates whether or not the GPS is rejecting satellites due to poor signal.";
CM_ SG_ 970 DAS_gpsWheelsOffMotionDetected "Indicates that wheels-off acceleration detected";
CM_ SG_ 970 DAS_gpsFixTypeHardware "The fix type of the GPS receiver, see u-blox M8 spec, section 33.13.1.1";
CM_ SG_ 970 DAS_gpsRawxEnabled "GPS receiver has raw messages enabled";
CM_ SG_ 970 DAS_gpsRxmRawxMia "Driver assistance computer: gps rxm rawx mia";
CM_ SG_ 970 DAS_gpsRxmSfrbxMia "Driver assistance computer: gps rxm sfrbx mia";
CM_ SG_ 970 DAS_gpsEsfMeasMia "AP is not receiving EsfMeas message from GPS receiver";
CM_ SG_ 970 DAS_gpsEsfRawMia "AP is not receiving EsfRaw message from GPS receiver";
CM_ SG_ 970 DAS_gpsNavStatusMia "AP is not receiving NavStatus message from GPS receiver";
CM_ SG_ 970 DAS_gpsSoftwareConfigured "Software GPS solution is allowed";
CM_ SG_ 970 DAS_gpsSoftwareUsed "Software GPS solution is actively used";
CM_ SG_ 970 DAS_gpsSoftwareFastStartReady "Software GPS solution could use fast start mechanism at boot-up";
CM_ SG_ 970 DAS_gpsSatsInUseSoftware "The number of GPS satellites currently in use by software solution on SOC-A.";
CM_ SG_ 970 DAS_gpsFixTypeSoftware "The fix type of the GPS software solution on SOC-A.";
CM_ SG_ 970 DAS_gpsCWJammingInidcator "Level of continuous wave jamming detected by GPS hardware";
CM_ SG_ 970 DAS_gpsJammingState "State of GPS jamming monitor";
CM_ SG_ 970 DAS_gpsSpoofDetectorState "Instantaneous state of GPS spoofing detector. Detection only triggers at the transition from real to suspected spoof signal.";
CM_ SG_ 970 DAS_gpsInvalidMsgPercentage "Percentage of messages received by AP from GPS receiver that were invalid. Calculated over up-to 10s window.";
CM_ SG_ 970 DAS_gnssConstellationsState "Indicates if GNSS constellations match expected configuration.";
CM_ SG_ 970 DAS_gpsReceiverNoiseLevel "General noise level of GPS receiver.";
CM_ SG_ 970 DAS_gpsAutomaticGainControl "Automatic Gain Control of GPS receiver.";
CM_ SG_ 970 DAS_gpsPreviousPositionDeltaHw "Change in position of two consecutive location outputs from GPS hardware solution.";
CM_ SG_ 970 DAS_gpsPreviousPositionDeltaSw "Change in position of two consecutive location outputs from GPS software solution.";
CM_ SG_ 970 DAS_gpsNmeaDispatchFailureCount "Number of GPS messages dropped by AP without sending over to UI. Calculated over up-to 10s window.";
CM_ SG_ 970 DAS_gnssMaxInstantaneousCnorGps "Maximum carrier-to-noise ratio among all satellites from GPS constellation.";
CM_ SG_ 970 DAS_gnssMaxInstantaneousCnorGal "Maximum carrier-to-noise ratio among all satellites from GALILEO constellation.";
CM_ SG_ 970 DAS_gnssMaxInstantaneousCnorBds "Maximum carrier-to-noise ratio among all satellites from BEIDOU constellation.";
CM_ SG_ 970 DAS_gpsResetReason "When AP resets GPS receiver, this signal indicates the reason why";
CM_ SG_ 970 DAS_gpsAccuracyHorizontal "Self-reported horizontal GPS accuracy";
CM_ SG_ 970 DAS_gpsAccuracyVertical "Self-reported vertical GPS accuracy";
CM_ SG_ 970 DAS_gpsSolutionFallback "GPS solution falling back from software to hardware";
CM_ SG_ 970 DAS_gpsToMcuSource "This signal exposes which localization solution is being sent to the MCU.";
CM_ SG_ 970 DAS_gpsSolutionSoc "Reports which System on Chip (SOC) is producing the GPS localization solution.";
CM_ SG_ 970 DAS_gpsRedundancyActive "Reports whether the GPS Redundancy feature is active on the Autopilot (AP) board. This feature enables either System on Chip (SOC) to publish the Global Navigation Satellite System (GNSS) solution.";
CM_ SG_ 970 DAS_gpsFixTypeSoftwareSocB "Reports the fix type of the GPS software solution on System on Chip B (SOC-B).";
CM_ SG_ 970 DAS_gpsSatsInUseSoftwareSocB "Reports the number of GPS satellites currently in use by software solution on System on Chip B (SOC-B).";
CM_ SG_ 970 DAS_gnssNumSatsGps "Number of satellites visible from GPS constellation.";
CM_ SG_ 970 DAS_gnssNumSatsGal "Number of satellites visible from GALILEO constellation.";
CM_ SG_ 970 DAS_gnssNumSatsBds "Number of satellites visible from BEIDOU constellation.";
CM_ SG_ 970 DAS_gnssAvgInstantaneousCnorGps "Average carrier-to-noise ratio among all satellites from GPS constellation on the high band as reported by the Positioning Engine on SOC-A.";
CM_ SG_ 970 DAS_gnssAvgInstantaneousCnorGal "Average carrier-to-noise ratio among all satellites from GALILEO constellation on the high band.";
CM_ SG_ 970 DAS_gnssAvgInstantaneousCnorBds "Average carrier-to-noise ratio among all satellites from BEIDOU constellation on the high band as reported by the Positioning Engine on SOC-A.";
CM_ SG_ 970 DAS_gnssAvgInstantaneousCnorGpsL "Measures the average carrier-to-noise ratio among all satellites from GPS constellation on the low band as reported by the Positioning Engine on System on Chip A (SOC-A).";
CM_ SG_ 970 DAS_gnssAvgInstantaneousCnorGalL "Measures the average carrier-to-noise ratio among all satellites from GALILEO constellation on the low band.";
CM_ SG_ 970 DAS_gnssAvgInstantaneousCnorBdsL "Measures the average carrier-to-noise ratio among all satellites from BEIDOU constellation on the low band as reported by the Positioning Engine on System on Chip A (SOC-A).";
CM_ BO_ 1337 "Driver assistance computer message: info; frame length from the layout, not yet observed on a vehicle bus";
CM_ SG_ 1337 DAS_infoIndex "Driver assistance computer: info index";
CM_ SG_ 1337 DAS_infoBuildType "Driver assistance computer: info build type";
CM_ SG_ 1337 DAS_infoBuildConfigID "Driver assistance computer: info build config ID";
CM_ SG_ 1337 DAS_infoHardwareID "Driver assistance computer: info hardware ID";
CM_ SG_ 1337 DAS_infoComponentID "Driver assistance computer: info component ID";
CM_ SG_ 1337 DAS_infoPcbaID "Driver assistance computer: info pcba ID";
CM_ SG_ 1337 DAS_infoAssemblyID "Driver assistance computer: info assembly ID";
CM_ SG_ 1337 DAS_infoUsageID "Driver assistance computer: info usage ID";
CM_ SG_ 1337 DAS_infoSubUsageID "Driver assistance computer: info sub usage ID";
CM_ SG_ 1337 DAS_infoApplicationCRC "Driver assistance computer: info application CRC";
CM_ SG_ 1337 DAS_infoAppGitHashBytes "Driver assistance computer: info app git hash bytes";
CM_ SG_ 1337 DAS_infoBootGitHashBytes "Driver assistance computer: info boot git hash bytes";
CM_ BO_ 569 "Driver assistance computer message: lanes; frame length from the layout, not yet observed on a vehicle bus";
CM_ SG_ 569 DAS_leftLaneExists "Driver assistance computer: left lane exists";
CM_ SG_ 569 DAS_rightLaneExists "Driver assistance computer: right lane exists";
CM_ SG_ 569 DAS_virtualLaneWidth "Driver assistance computer: virtual lane width";
CM_ SG_ 569 DAS_virtualLaneViewRange "Driver assistance computer: virtual lane view range";
CM_ SG_ 569 DAS_virtualLaneC0 "Driver assistance computer: virtual lane C0";
CM_ SG_ 569 DAS_virtualLaneC1 "Driver assistance computer: virtual lane C1";
CM_ SG_ 569 DAS_virtualLaneC2 "Driver assistance computer: virtual lane C2";
CM_ SG_ 569 DAS_virtualLaneC3 "Driver assistance computer: virtual lane C3";
CM_ SG_ 569 DAS_leftLineUsage "Driver assistance computer: left line usage";
CM_ SG_ 569 DAS_rightLineUsage "Driver assistance computer: right line usage";
CM_ SG_ 569 DAS_leftFork "Driver assistance computer: left fork";
CM_ SG_ 569 DAS_rightFork "Driver assistance computer: right fork";
CM_ SG_ 569 DAS_lanesCounter "Driver assistance computer: lanes counter";
CM_ BO_ 921 "Driver assistance computer message: status; frame length from the layout, not yet observed on a vehicle bus";
CM_ SG_ 921 DAS_autopilotState "Reports the high level autopilot state; raw 15 = signal not available (SNA)";
CM_ SG_ 921 DAS_blindSpotRearLeft "Reports rear left blind spot warning level; raw 3 = signal not available (SNA)";
CM_ SG_ 921 DAS_blindSpotRearRight "Reports rear right blind spot warning level; raw 3 = signal not available (SNA)";
CM_ SG_ 921 DAS_fusedSpeedLimit "Driver assistance computer: fused speed limit; raw 0 = signal not available (SNA)";
CM_ SG_ 921 DAS_suppressSpeedWarning "Driver assistance computer: suppress speed warning";
CM_ SG_ 921 DAS_summonObstacle "Driver assistance computer: summon obstacle";
CM_ SG_ 921 DAS_summonClearedGate "Driver assistance computer: summon cleared gate";
CM_ SG_ 921 DAS_visionOnlySpeedLimit "Driver assistance computer: vision only speed limit; raw 0 = signal not available (SNA)";
CM_ SG_ 921 DAS_heaterState "The state of the app which runs the front glass heater; raw 0 = signal not available (SNA)";
CM_ SG_ 921 DAS_forwardCollisionWarning "Driver assistance computer: forward collision warning; raw 3 = signal not available (SNA)";
CM_ SG_ 921 DAS_autoparkReady "Indicates if all the conditions for Autopark are met.";
CM_ SG_ 921 DAS_autoParked "Driver assistance computer: auto parked";
CM_ SG_ 921 DAS_autoparkActive "Reports whether Autopark is currently active.";
CM_ SG_ 921 DAS_summonFwdLeashReached "Driver assistance computer: summon fwd leash reached";
CM_ SG_ 921 DAS_summonRvsLeashReached "Driver assistance computer: summon rvs leash reached";
CM_ SG_ 921 DAS_lssState "Tracks lane support system state and whether it is controlling steering angle requests for LKA / ELKA.";
CM_ SG_ 921 DAS_sideCollisionAvoid "Reports if the side collision avoidance function is active on the left or right; raw 3 = signal not available (SNA)";
CM_ SG_ 921 DAS_sideCollisionWarning "Reports if the side collision warning function is active in the left or right.";
CM_ SG_ 921 DAS_sideCollisionInhibit "Driver assistance computer: side collision inhibit";
CM_ SG_ 921 DAS_laneDepartureWarning "Driver assistance computer: lane departure warning; raw 5 = signal not available (SNA)";
CM_ SG_ 921 DAS_fleetSpeedState "The state of the fleet speed algorithm.";
CM_ SG_ 921 DAS_autopilotHandsOnState "Reports the state of the hands on state machine; raw 15 = signal not available (SNA)";
CM_ SG_ 921 DAS_autoLaneChangeState "Reports the legacy Automatic Lane Change (ALC) state used to drive the instrument cluster User Interface (UI); raw 31 = signal not available (SNA)";
CM_ SG_ 921 DAS_summonAvailable "Driver assistance computer: summon available";
CM_ SG_ 921 DAS_statusCounter "Driver assistance computer: status counter";
CM_ SG_ 921 DAS_statusChecksum "Driver assistance computer: status checksum";
CM_ BO_ 905 "Driver assistance computer message: status2; frame length from the layout, not yet observed on a vehicle bus";
CM_ SG_ 905 DAS_accSpeedLimit "Reports the Adaptive Cruise Control (ACC) speed limit, which is derived from speed limits embedded in maps; raw 511 = signal not available (SNA)";
CM_ SG_ 905 DAS_versionIdentifier "Driver assistance computer: version identifier";
CM_ SG_ 905 DAS_pmmObstacleSeverity "Detects the output of the Pedal Misapplication Mitigation (PMM) function, which limits torque or applies the brake; raw 7 = signal not available (SNA)";
CM_ SG_ 905 DAS_pmmLoggingRequest "Driver assistance computer: pmm logging request";
CM_ SG_ 905 DAS_activationFailureStatus "Driver assistance computer: activation failure status";
CM_ SG_ 905 DAS_pmmUltrasonicsFaultReason "Reports if there is a reason Pedal Misapplication Mitigation (PMM) is disabled due to a condition with the ultrasonics.";
CM_ SG_ 905 DAS_pmmRadarFaultReason "Reports if there is a reason Pedal Misapplication Mitigation (PMM) is disabled due to a radar issue.";
CM_ SG_ 905 DAS_pmmSysFaultReason "Reports if there is a reason Pedal Misapplication Mitigation (PMM) is disabled due to a system malfunction.";
CM_ SG_ 905 DAS_pmmCameraFaultReason "Reports if there is a reason Pedal Misapplication Mitigation (PMM) is disabled due to camera issues.";
CM_ SG_ 905 DAS_ACC_report "Indicates what control target Traffic-Aware Cruise Control (TACC) is controlling for. Only relevant during TACC (not Autosteer).";
CM_ SG_ 905 DAS_relaxCruiseLimits "Indicates whether DI should relax accel limits";
CM_ SG_ 905 DAS_csaState "Reports the state of the curve speed adaption algorithm.";
CM_ SG_ 905 DAS_radarTelemetry "Driver assistance computer: radar telemetry";
CM_ SG_ 905 DAS_robState "Driver assistance computer: rob state";
CM_ SG_ 905 DAS_driverInteractionLevel "Driver assistance computer: driver interaction level";
CM_ SG_ 905 DAS_ppOffsetDesiredRamp "Driver assistance computer: pp offset desired ramp";
CM_ SG_ 905 DAS_longCollisionWarning "Driver assistance computer: long collision warning; raw 15 = signal not available (SNA)";
CM_ SG_ 905 DAS_status2Counter "Driver assistance computer: status2 counter";
CM_ SG_ 905 DAS_status2Checksum "Driver assistance computer: status2 checksum";
CM_ BO_ 1625 "Driver assistance computer message: uds response; frame length from the layout, not yet observed on a vehicle bus";
CM_ SG_ 1625 DAS_udsResponseData "Driver assistance computer: uds response data";
CM_ BO_ 586 "Driver assistance computer message: visual debug; frame length from the layout, not yet observed on a vehicle bus";
CM_ SG_ 586 DAS_autosteerVehiclesUsage "Driver assistance computer: autosteer vehicles usage";
CM_ SG_ 586 DAS_autosteerHPPUsage "Driver assistance computer: autosteer HPP usage";
CM_ SG_ 586 DAS_autosteerNavigationUsage "Driver assistance computer: autosteer navigation usage";
CM_ SG_ 586 DAS_autosteerModelUsage "Driver assistance computer: autosteer model usage";
CM_ SG_ 586 DAS_autosteerBottsDotsUsage "Driver assistance computer: autosteer botts dots usage";
CM_ SG_ 586 DAS_offsetSide "Driver assistance computer: offset side";
CM_ SG_ 586 DAS_roadSurfaceType "Driver assistance computer: road surface type; raw 0 = signal not available (SNA)";
CM_ SG_ 586 DAS_autosteerHealthAnomalyLevel "Driver assistance computer: autosteer health anomaly level";
CM_ SG_ 586 DAS_autosteerHealthState "Driver assistance computer: autosteer health state";
CM_ SG_ 586 DAS_lastLinePreferenceReason "Driver assistance computer: last line preference reason";
CM_ SG_ 586 DAS_plannerState "Driver assistance computer: planner state";
CM_ SG_ 586 DAS_lastAutosteerAbortReason "Driver assistance computer: last autosteer abort reason";
CM_ SG_ 586 DAS_devAppInterfaceEnabled "Driver assistance computer: dev app interface enabled";
CM_ SG_ 586 DAS_navAvailable "Driver assistance computer: nav available";
CM_ SG_ 586 DAS_navDistance "Driver assistance computer: nav distance";
CM_ SG_ 586 DAS_accSmartSpeedActive "Driver assistance computer: acc smart speed active";
CM_ SG_ 586 DAS_accSmartSpeedState "Driver assistance computer: acc smart speed state; raw 7 = signal not available (SNA)";
CM_ SG_ 586 DAS_ulcInProgress "Reports active lane changes that were not commanded.";
CM_ SG_ 586 DAS_trafficAwareSetSpeedInUse "Indicates that autopilot is using cruise set speed based on flow of traffic";
CM_ SG_ 586 DAS_isaSystemState "ISA system state";
CM_ SG_ 586 DAS_behaviorType "Driver assistance computer: behavior type";
CM_ SG_ 586 DAS_ulcType "Reports the underlying reason for the uncommanded lane change, whether for speed or route.";
CM_ SG_ 586 DAS_rearVehDetectedThisCycle "Driver assistance computer: rear veh detected this cycle";
CM_ SG_ 586 DAS_rearLeftVehDetectedCurrent "Driver assistance computer: rear left veh detected current";
CM_ SG_ 586 DAS_rearRightVehDetectedTrip "Driver assistance computer: rear right veh detected trip";
CM_ SG_ 586 DAS_rearLeftVehDetectedTrip "Driver assistance computer: rear left veh detected trip";
CM_ BO_ 810 "Driver assistance computer message: warning matrix0; frame length from the layout, not yet observed on a vehicle bus";
CM_ SG_ 810 DAS_w002_ldwDisabled "Driver assistance computer: w002 ldw disabled";
CM_ SG_ 810 DAS_w003_isaDisabled "Driver assistance computer: w003 isa disabled";
CM_ SG_ 810 DAS_w004_accDisabled "Driver assistance computer: w004 acc disabled";
CM_ SG_ 810 DAS_w005_fcwCancelled "Driver assistance computer: w005 fcw cancelled";
CM_ SG_ 810 DAS_w006_aebCancelled "Driver assistance computer: w006 aeb cancelled";
CM_ SG_ 810 DAS_w007_ahlbDisabled "Driver assistance computer: w007 ahlb disabled";
CM_ SG_ 810 DAS_w008_parkDisabled "Driver assistance computer: w008 park disabled";
CM_ SG_ 810 DAS_w009_aebFault "Driver assistance computer: w009 aeb fault";
CM_ SG_ 810 DAS_w010_radcCalibIssue "Driver assistance computer: w010 radc calib issue";
CM_ SG_ 810 DAS_w011_scaEvent "Driver assistance computer: w011 sca event";
CM_ SG_ 810 DAS_w012_Cam_BootFailure "Driver assistance computer: w012 cam boot failure";
CM_ SG_ 810 DAS_w013_Cam_Watchdog "Driver assistance computer: w013 cam watchdog";
CM_ SG_ 810 DAS_w014_swAssert "Driver assistance computer: w014 sw assert";
CM_ SG_ 810 DAS_w015_Camera_Failsafes "Driver assistance computer: w015 camera failsafes";
CM_ SG_ 810 DAS_w016_aeb_e_event "Driver assistance computer: w016 aeb e event";
CM_ SG_ 810 DAS_w017_Cam_Msg_MIA "Driver assistance computer: w017 cam msg MIA";
CM_ SG_ 810 DAS_w018_ECU_Power_Issue "Driver assistance computer: w018 ECU power issue";
CM_ SG_ 810 DAS_w019_ECU_Stack_Overflow "Driver assistance computer: w019 ECU stack overflow";
CM_ SG_ 810 DAS_w020_ECU_checkstopError "Driver assistance computer: w020 ECU checkstop error";
CM_ SG_ 810 DAS_w021_ECU_Temperature_Issue "Driver assistance computer: w021 ECU temperature issue";
CM_ SG_ 810 DAS_w022_ECU_EEPROM_Failure "Driver assistance computer: w022 ECU EEPROM failure";
CM_ SG_ 810 DAS_w023_ECU_Cam_Statemismatc "Driver assistance computer: w023 ECU cam statemismatc";
CM_ SG_ 810 DAS_w024_ECU_Watchdog_Reset "Driver assistance computer: w024 ECU watchdog reset";
CM_ SG_ 810 DAS_w025_LC_Steering_Override "Driver assistance computer: w025 LC steering override";
CM_ SG_ 810 DAS_w026_ECU_timingIssue "Driver assistance computer: w026 ECU timing issue";
CM_ SG_ 810 DAS_w027_ECU_Reset_Fault "Driver assistance computer: w027 ECU reset fault";
CM_ SG_ 810 DAS_w028_spi_rx_error "Driver assistance computer: w028 spi rx error";
CM_ SG_ 810 DAS_w029_spi_tx_error "Driver assistance computer: w029 spi tx error";
CM_ SG_ 810 DAS_w030_Heater_Issue "Driver assistance computer: w030 heater issue";
CM_ SG_ 810 DAS_w031_canRxError "Driver assistance computer: w031 can rx error";
CM_ SG_ 810 DAS_w032_canTxError "Driver assistance computer: w032 can tx error";
CM_ SG_ 810 DAS_w033_gtwMia "Driver assistance computer: w033 gtw mia";
CM_ SG_ 810 DAS_w034_sccmMia "Driver assistance computer: w034 sccm mia";
CM_ SG_ 810 DAS_w035_espMia "Driver assistance computer: w035 esp mia";
CM_ SG_ 810 DAS_w036_bdyMia "Driver assistance computer: w036 bdy mia";
CM_ SG_ 810 DAS_w037_camTacIssue "Driver assistance computer: w037 cam tac issue";
CM_ SG_ 810 DAS_w038_camFailure "Driver assistance computer: w038 cam failure";
CM_ SG_ 810 DAS_w039_sdm_rcm_Mia "Driver assistance computer: w039 sdm rcm mia";
CM_ SG_ 810 DAS_w040_autopilotAngleSaturated "Driver assistance computer: w040 autopilot angle saturated";
CM_ SG_ 810 DAS_w041_autopilotRateSaturated "Driver assistance computer: w041 autopilot rate saturated";
CM_ SG_ 810 DAS_w042_autopilotAborting "Driver assistance computer: w042 autopilot aborting";
CM_ SG_ 810 DAS_w043_camLongRunTime "Driver assistance computer: w043 cam long run time";
CM_ SG_ 810 DAS_w044_appMobileyeFailure "Driver assistance computer: w044 app mobileye failure";
CM_ SG_ 810 DAS_w045_radMia "Driver assistance computer: w045 rad mia";
CM_ SG_ 810 DAS_w046_eepromRecordAbsent "Driver assistance computer: w046 eeprom record absent";
CM_ SG_ 810 DAS_w047_edrEvent "Driver assistance computer: w047 edr event";
CM_ SG_ 810 DAS_w048_DAS_Features_Disabled "Driver assistance computer: w048 DAS features disabled";
CM_ SG_ 810 DAS_w049_eyeqVersionMismatch "Driver assistance computer: w049 eyeq version mismatch";
CM_ SG_ 810 DAS_w050_aeb_event "Driver assistance computer: w050 aeb event";
CM_ SG_ 810 DAS_w051_radcEcuIssue "Driver assistance computer: w051 radc ecu issue";
CM_ SG_ 810 DAS_w052_radcSensorIssue "Driver assistance computer: w052 radc sensor issue";
CM_ SG_ 810 DAS_w053_radcCommIssue "Driver assistance computer: w053 radc comm issue";
CM_ SG_ 810 DAS_w054_camAutofix "Driver assistance computer: w054 cam autofix";
CM_ SG_ 810 DAS_w055_radcVersionMismatch "Driver assistance computer: w055 radc version mismatch";
CM_ SG_ 810 DAS_w056_diMia "Driver assistance computer: w056 di mia";
CM_ SG_ 810 DAS_w057_mcuMia "Driver assistance computer: w057 mcu mia";
CM_ SG_ 810 DAS_w058_epbMia "Driver assistance computer: w058 epb mia";
CM_ SG_ 810 DAS_w059_parkMia "Driver assistance computer: w059 park mia";
CM_ SG_ 810 DAS_w060_fcw_event "Driver assistance computer: w060 fcw event";
CM_ SG_ 810 DAS_w061_airSuspensionMia "Driver assistance computer: w061 air suspension mia";
CM_ SG_ 810 DAS_w062_radcAlignment "Driver assistance computer: w062 radc alignment";
CM_ SG_ 810 DAS_w063_parkVersionMismatch "Driver assistance computer: w063 park version mismatch";
CM_ SG_ 810 DAS_w064_epasMia "Driver assistance computer: w064 epas mia";
CM_ BO_ 874 "Driver assistance computer message: warning matrix1; frame length from the layout, not yet observed on a vehicle bus";
CM_ SG_ 874 DAS_w065_deserializerOvercurrent "Driver assistance computer: w065 deserializer overcurrent";
CM_ SG_ 874 DAS_w066_deserializerLockLost "Driver assistance computer: w066 deserializer lock lost";
CM_ SG_ 874 DAS_w067_steeringAlignment "Driver assistance computer: w067 steering alignment";
CM_ SG_ 874 DAS_w068_vlInconsistency "Driver assistance computer: w068 vl inconsistency";
CM_ SG_ 874 DAS_w069_apcSpaceMasked "Driver assistance computer: w069 apc space masked";
CM_ SG_ 874 DAS_w070_apcIncompleteCal "Driver assistance computer: w070 apc incomplete cal";
CM_ SG_ 874 DAS_w071_selfparkStarted "Driver assistance computer: w071 selfpark started";
CM_ SG_ 874 DAS_w072_selfparkComplete "Driver assistance computer: w072 selfpark complete";
CM_ SG_ 874 DAS_w073_issueEscalatedLDW "Driver assistance computer: w073 issue escalated LDW";
CM_ SG_ 874 DAS_w074_inPathStationaryObst "Driver assistance computer: w074 in path stationary obst";
CM_ SG_ 874 DAS_w075_scMia "Driver assistance computer: w075 sc mia";
CM_ SG_ 874 DAS_w076_mobilEyeSetC "Driver assistance computer: w076 mobil eye set c";
CM_ SG_ 874 DAS_w077_pmmActive "Driver assistance computer: w077 pmm active";
CM_ SG_ 874 DAS_w078_pmmActive2 "Driver assistance computer: w078 pmm active2";
CM_ SG_ 874 DAS_w079_edrAvailable "Driver assistance computer: w079 edr available";
CM_ SG_ 874 DAS_w080_accFailedActivation "Driver assistance computer: w080 acc failed activation";
CM_ SG_ 874 DAS_w081_pmmActiveBraking "Driver assistance computer: w081 pmm active braking";
CM_ SG_ 874 DAS_w082_inPathFSviolation "Driver assistance computer: w082 in path f sviolation";
CM_ SG_ 874 DAS_w083_inPathRADObject "Driver assistance computer: w083 in path RAD object";
CM_ SG_ 874 DAS_w084_pmmIPSO "Driver assistance computer: w084 pmm IPSO";
CM_ SG_ 874 DAS_w085_pmmSteering "Driver assistance computer: w085 pmm steering";
CM_ SG_ 874 DAS_w086_robCollision "Driver assistance computer: w086 rob collision";
CM_ SG_ 874 DAS_w087_DEPRECATED "Driver assistance computer: w087 DEPRECATED";
CM_ SG_ 874 DAS_w088_DEPRECATED "Driver assistance computer: w088 DEPRECATED";
CM_ SG_ 874 DAS_w089_DEPRECATED "Driver assistance computer: w089 DEPRECATED";
CM_ SG_ 874 DAS_w090_DEPRECATED "Driver assistance computer: w090 DEPRECATED";
CM_ SG_ 874 DAS_w091_DEPRECATED "Driver assistance computer: w091 DEPRECATED";
CM_ SG_ 874 DAS_w092_DEPRECATED "Driver assistance computer: w092 DEPRECATED";
CM_ SG_ 874 DAS_w093_DEPRECATED "Driver assistance computer: w093 DEPRECATED";
CM_ SG_ 874 DAS_w094_DEPRECATED "Driver assistance computer: w094 DEPRECATED";
CM_ SG_ 874 DAS_w095_DEPRECATED "Driver assistance computer: w095 DEPRECATED";
CM_ SG_ 874 DAS_w096_DEPRECATED "Driver assistance computer: w096 DEPRECATED";
CM_ SG_ 874 DAS_w097_DEPRECATED "Driver assistance computer: w097 DEPRECATED";
CM_ SG_ 874 DAS_w098_DEPRECATED "Driver assistance computer: w098 DEPRECATED";
CM_ SG_ 874 DAS_w099_DEPRECATED "Driver assistance computer: w099 DEPRECATED";
CM_ SG_ 874 DAS_w100_DEPRECATED "Driver assistance computer: w100 DEPRECATED";
CM_ SG_ 874 DAS_w101_DEPRECATED "Driver assistance computer: w101 DEPRECATED";
CM_ SG_ 874 DAS_w102_DEPRECATED "Driver assistance computer: w102 DEPRECATED";
CM_ SG_ 874 DAS_w103_robExperimentalAEB "Driver assistance computer: w103 rob experimental AEB";
CM_ SG_ 874 DAS_w104_DEPRECATED "Driver assistance computer: w104 DEPRECATED";
CM_ SG_ 874 DAS_w105_DEPRECATED "Driver assistance computer: w105 DEPRECATED";
CM_ SG_ 874 DAS_w106_torsionBarCalibrated "Driver assistance computer: w106 torsion bar calibrated";
CM_ BO_ 841 "Driver assistance computer message: warning matrix2; frame length from the layout, not yet observed on a vehicle bus";
CM_ SG_ 841 DAS_w129_mainCamExtNotCal "Driver assistance computer: w129 main cam ext not cal";
CM_ SG_ 841 DAS_w130_narrowCamExtNotCal "Driver assistance computer: w130 narrow cam ext not cal";
CM_ SG_ 841 DAS_w131_mainCamCalSaved "Driver assistance computer: w131 main cam cal saved";
CM_ SG_ 841 DAS_w132_narrowCamCalSaved "Driver assistance computer: w132 narrow cam cal saved";
CM_ SG_ 841 DAS_w133_mainCamInitFault "Driver assistance computer: w133 main cam init fault";
CM_ SG_ 841 DAS_w134_narrowCamInitFault "Driver assistance computer: w134 narrow cam init fault";
CM_ SG_ 841 DAS_w135_fisheyeCamInitFault "Driver assistance computer: w135 fisheye cam init fault";
CM_ SG_ 841 DAS_w136_lPillarCamInitFault "Driver assistance computer: w136 l pillar cam init fault";
CM_ SG_ 841 DAS_w137_rPillarCamInitFault "Driver assistance computer: w137 r pillar cam init fault";
CM_ SG_ 841 DAS_w138_lRepeatCamInitFault "Driver assistance computer: w138 l repeat cam init fault";
CM_ SG_ 841 DAS_w139_rRepeatCamInitFault "Driver assistance computer: w139 r repeat cam init fault";
CM_ SG_ 841 DAS_w140_backupCamInitFault "Driver assistance computer: w140 backup cam init fault";
CM_ SG_ 841 DAS_w141_ECU_Thermal_Issue "Driver assistance computer: w141 ECU thermal issue";
CM_ SG_ 841 DAS_w142_fwdCamPitchProblem "Driver assistance computer: w142 fwd cam pitch problem";
CM_ SG_ 841 DAS_w143_IDF_event "Driver assistance computer: w143 IDF event";
CM_ SG_ 841 DAS_w144_selfieCamInitFault "Driver assistance computer: w144 selfie cam init fault";
CM_ SG_ 841 DAS_w171_fisheyeCamExtNotCal "Driver assistance computer: w171 fisheye cam ext not cal";
CM_ SG_ 841 DAS_w172_lPillarCamExtNotCal "Driver assistance computer: w172 l pillar cam ext not cal";
CM_ SG_ 841 DAS_w173_rPillarCamExtNotCal "Driver assistance computer: w173 r pillar cam ext not cal";
CM_ SG_ 841 DAS_w174_lRepeatCamExtNotCal "Driver assistance computer: w174 l repeat cam ext not cal";
CM_ SG_ 841 DAS_w175_rRepeatCamExtNotCal "Driver assistance computer: w175 r repeat cam ext not cal";
CM_ SG_ 841 DAS_w177_fisheyeCamCalSaved "Driver assistance computer: w177 fisheye cam cal saved";
CM_ SG_ 841 DAS_w178_lPillarCamCalSaved "Driver assistance computer: w178 l pillar cam cal saved";
CM_ SG_ 841 DAS_w179_rPillarCamCalSaved "Driver assistance computer: w179 r pillar cam cal saved";
CM_ SG_ 841 DAS_w180_lRepeatCamCalSaved "Driver assistance computer: w180 l repeat cam cal saved";
CM_ SG_ 841 DAS_w181_rRepeatCamCalSaved "Driver assistance computer: w181 r repeat cam cal saved";
CM_ BO_ 1082 "Driver assistance computer message: warning matrix3; frame length from the layout, not yet observed on a vehicle bus";
CM_ SG_ 1082 DAS_w193_camWindshieldUnclean "Driver assistance computer: w193 cam windshield unclean";
CM_ SG_ 1082 DAS_w194_accDriverResumeRqrd "Driver assistance computer: w194 acc driver resume rqrd";
CM_ SG_ 1082 DAS_w195_scwUnavailable "Driver assistance computer: w195 scw unavailable";
CM_ SG_ 1082 DAS_w196_stopSignWarning "Driver assistance computer: w196 stop sign warning";
CM_ SG_ 1082 DAS_w197_redLightWarning "Driver assistance computer: w197 red light warning";
CM_ SG_ 1082 DAS_w198_tsrUnavailable "Driver assistance computer: w198 tsr unavailable";
CM_ SG_ 1082 DAS_w199_apcAbort "Driver assistance computer: w199 apc abort";
CM_ SG_ 1082 DAS_w200_lcSlowdown "Driver assistance computer: w200 lc slowdown";
CM_ SG_ 1082 DAS_w201_lcAborting "Driver assistance computer: w201 lc aborting";
CM_ SG_ 1082 DAS_w202_scwNoisyEnvironment "Driver assistance computer: w202 scw noisy environment";
CM_ SG_ 1082 DAS_w203_apcActivation "Driver assistance computer: w203 apc activation";
CM_ SG_ 1082 DAS_w204_apcFinalFront "Driver assistance computer: w204 apc final front";
CM_ SG_ 1082 DAS_w205_apcFinalRear "Driver assistance computer: w205 apc final rear";
CM_ SG_ 1082 DAS_w206_autosteerNotEnabled "Driver assistance computer: w206 autosteer not enabled";
CM_ SG_ 1082 DAS_w207_autosteerUnavailable "Driver assistance computer: w207 autosteer unavailable";
CM_ SG_ 1082 DAS_w208_rackDetected "Driver assistance computer: w208 rack detected";
CM_ SG_ 1082 DAS_w209_autoSummonRequest "Driver assistance computer: w209 auto summon request";
CM_ SG_ 1082 DAS_w210_camObstrcted "Driver assistance computer: w210 cam obstrcted";
CM_ SG_ 1082 DAS_w211_accNoSeatBelt "Driver assistance computer: w211 acc no seat belt";
CM_ SG_ 1082 DAS_w212_lcUnavailableStrikeOut "Driver assistance computer: w212 lc unavailable strike out";
CM_ SG_ 1082 DAS_w213_autosteerStruckOut "Driver assistance computer: w213 autosteer struck out";
CM_ SG_ 1082 DAS_w214_driverNotIntracting "Driver assistance computer: w214 driver not intracting";
CM_ SG_ 1082 DAS_w215_contDriverNotIntracting "Driver assistance computer: w215 cont driver not intracting";
CM_ SG_ 1082 DAS_w216_driverOverriding "Driver assistance computer: w216 driver overriding";
CM_ SG_ 1082 DAS_w217_lcUnavailableSpeeding "Driver assistance computer: w217 lc unavailable speeding";
CM_ SG_ 1082 DAS_w218_lcSpeedExceededLimit "Driver assistance computer: w218 lc speed exceeded limit";
CM_ SG_ 1082 DAS_w219_lcTempUnavailableSpeed "Driver assistance computer: w219 lc temp unavailable speed";
CM_ SG_ 1082 DAS_w220_lcTempUnavailableRoad "Driver assistance computer: w220 lc temp unavailable road";
CM_ SG_ 1082 DAS_w221_accRadarBlind "Driver assistance computer: w221 acc radar blind";
CM_ SG_ 1082 DAS_w222_accCameraBlind "Driver assistance computer: w222 acc camera blind";
CM_ SG_ 1082 DAS_w223_accObjectInPath "Driver assistance computer: w223 acc object in path";
CM_ SG_ 1082 DAS_w224_accCameraCalibration "Driver assistance computer: w224 acc camera calibration";
CM_ SG_ 1082 DAS_w225_lcDegradedVisSpeedLmt "Driver assistance computer: w225 lc degraded vis speed lmt";
CM_ SG_ 1082 DAS_w226_lcCamCalNeededSpeedLmt "Driver assistance computer: w226 lc cam cal needed speed lmt";
CM_ SG_ 1082 DAS_w227_virtualWallBlocked "Driver assistance computer: w227 virtual wall blocked";
CM_ SG_ 1082 DAS_w228_DEPRECATED "Driver assistance computer: w228 DEPRECATED";
CM_ SG_ 1082 DAS_w229_alcUltrasoundDamaged "Driver assistance computer: w229 alc ultrasound damaged";
CM_ SG_ 1082 DAS_w230_alcUltrasoundBlocked "Driver assistance computer: w230 alc ultrasound blocked";
CM_ SG_ 1082 DAS_w231_idfEvent "Driver assistance computer: w231 idf event";
CM_ SG_ 1082 DAS_w232_laneChangeRequested "Driver assistance computer: w232 lane change requested";
CM_ BO_ 1425 "Electric power steering (secondary) message: alert log; frame length from the layout, not yet observed on a vehicle bus";
CM_ SG_ 1425 EPAS3S_alertID "Electric power steering (secondary): alert ID";
CM_ SG_ 1425 EPAS3S_alertState "Electric power steering (secondary): alert state";
CM_ SG_ 1425 EPAS3S_a147_transitionReason "Electric power steering (secondary): a147 transition reason";
CM_ SG_ 1425 EPAS3S_a149_pcbTemp "Electric power steering (secondary): a149 pcb temp";
CM_ SG_ 1425 EPAS3S_a150_pcbTemp "Electric power steering (secondary): a150 pcb temp";
CM_ SG_ 1425 EPAS3S_a150_phaUMainPathCalcDiff "Electric power steering (secondary): a150 pha u main path calc diff";
CM_ SG_ 1425 EPAS3S_a150_phaVMainPathCalcDiff "Electric power steering (secondary): a150 pha v main path calc diff";
CM_ SG_ 1425 EPAS3S_a150_otherECUAssistStatus "Electric power steering (secondary): a150 other ECU assist status flag";
CM_ SG_ 1425 EPAS3S_a155_vehicleSpeed "Electric power steering (secondary): a155 vehicle speed";
CM_ SG_ 1425 EPAS3S_a156_vehicleSpeed "Electric power steering (secondary): a156 vehicle speed";
CM_ SG_ 1425 EPAS3S_a160_currentSensorStatus "Electric power steering (secondary): a160 current sensor status";
CM_ SG_ 1425 EPAS3S_a160_gateDriverStatus "Electric power steering (secondary): a160 gate driver status";
CM_ SG_ 1425 EPAS3S_a160_highSideDisconnectFe "Electric power steering (secondary): a160 high side disconnect fet status";
CM_ SG_ 1425 EPAS3S_a160_phaseDisconnectFetSt "Electric power steering (secondary): a160 phase disconnect fet status";
CM_ SG_ 1425 EPAS3S_a160_inverterFetStatus "Electric power steering (secondary): a160 inverter fet status";
CM_ SG_ 1425 EPAS3S_a160_hsdFetFailShortTest "Electric power steering (secondary): a160 hsd fet fail short test";
CM_ SG_ 1425 EPAS3S_a160_phaDisconnFailOpenTe "Electric power steering (secondary): a160 pha disconn fail open test";
CM_ SG_ 1425 EPAS3S_a160_phaDisconnFailShortT "Electric power steering (secondary): a160 pha disconn fail short test";
CM_ SG_ 1425 EPAS3S_a160_invFetInitTest "Electric power steering (secondary): a160 inv fet init test";
CM_ SG_ 1425 EPAS3S_a160_gateDrvrInitTest "Electric power steering (secondary): a160 gate drvr init test";
CM_ SG_ 1425 EPAS3S_a160_latentFaultTestTimeo "Electric power steering (secondary): a160 latent fault test timeout";
CM_ SG_ 1425 EPAS3S_a161_pcoMinPhaseBCurrent "Electric power steering (secondary): a161 pco min phase b current";
CM_ SG_ 1425 EPAS3S_a161_pcoMaxPhaseBCurrent "Electric power steering (secondary): a161 pco max phase b current";
CM_ SG_ 1425 EPAS3S_a161_pcoMinPhaseACurrent "Electric power steering (secondary): a161 pco min phase a current";
CM_ SG_ 1425 EPAS3S_a161_pcoMaxPhaseACurrent "Electric power steering (secondary): a161 pco max phase a current";
CM_ SG_ 1425 EPAS3S_a162_vBridgeClosed "Electric power steering (secondary): a162 v bridge closed";
CM_ SG_ 1425 EPAS3S_a162_vBridgeOpen "Electric power steering (secondary): a162 v bridge open";
CM_ SG_ 1425 EPAS3S_a163_gateDrvrStatusReg "Electric power steering (secondary): a163 gate drvr status reg";
CM_ SG_ 1425 EPAS3S_a163_gateDrvrDiag2Reg "Electric power steering (secondary): a163 gate drvr diag2 reg";
CM_ SG_ 1425 EPAS3S_a163_gateDrvrDiag1Reg "Electric power steering (secondary): a163 gate drvr diag1 reg";
CM_ SG_ 1425 EPAS3S_a163_gateDrvrDiag0Reg "Electric power steering (secondary): a163 gate drvr diag0 reg";
CM_ SG_ 1425 EPAS3S_a163_diagStatus "Electric power steering (secondary): a163 diag status";
CM_ SG_ 1425 EPAS3S_a163_powerStatus "Electric power steering (secondary): a163 power status";
CM_ SG_ 1425 EPAS3S_a164_dcsRegister0x19 "Electric power steering (secondary): a164 dcs register0x19";
CM_ SG_ 1425 EPAS3S_a164_currentSensorRailed "Electric power steering (secondary): a164 current sensor railed";
BA_DEF_ BO_ "GenMsgCycleTime" INT 0 3600000;
BA_DEF_ BO_ "GenMsgSendType" ENUM "Cyclic","NotUsed","NotUsed","NotUsed","NotUsed","NotUsed","NotUsed","IfActive","NoMsgSendType","NotUsed";
BA_DEF_ BO_ "VFrameFormat" ENUM "StandardCAN","ExtendedCAN","reserved","J1939PG","reserved","reserved","reserved","reserved","reserved","reserved","reserved","reserved","reserved","reserved","StandardCAN_FD","ExtendedCAN_FD";
BA_DEF_ BO_ "CANFD_BRS" ENUM "0","1";
BA_DEF_ SG_ "GenSigSNA" STRING;
BA_DEF_ SG_ "SystemSignalLongSymbol" STRING;
BA_DEF_ SG_ "Confidence" ENUM "validated","plausible","layout-only","contradicted";
BA_DEF_DEF_ "GenMsgCycleTime" 0;
BA_DEF_DEF_ "GenMsgSendType" "NoMsgSendType";
BA_DEF_DEF_ "VFrameFormat" "StandardCAN";
BA_DEF_DEF_ "CANFD_BRS" "1";
BA_DEF_DEF_ "GenSigSNA" "";
BA_DEF_DEF_ "SystemSignalLongSymbol" "";
BA_DEF_DEF_ "Confidence" "layout-only";
BA_ "GenMsgCycleTime" BO_ 1113 1000;
BA_ "GenMsgSendType" BO_ 1113 0;
BA_ "GenMsgCycleTime" BO_ 848 1000;
BA_ "GenMsgSendType" BO_ 848 0;
BA_ "GenMsgCycleTime" BO_ 784 1000;
BA_ "GenMsgSendType" BO_ 784 0;
BA_ "GenMsgCycleTime" BO_ 401 100;
BA_ "GenMsgSendType" BO_ 401 0;
BA_ "GenMsgCycleTime" BO_ 583 100;
BA_ "GenMsgSendType" BO_ 583 0;
BA_ "GenMsgCycleTime" BO_ 1497 333;
BA_ "GenMsgSendType" BO_ 1497 0;
BA_ "GenMsgCycleTime" BO_ 970 1000;
BA_ "GenMsgSendType" BO_ 970 0;
BA_ "GenMsgCycleTime" BO_ 1337 1000;
BA_ "GenMsgSendType" BO_ 1337 0;
BA_ "GenMsgCycleTime" BO_ 569 100;
BA_ "GenMsgSendType" BO_ 569 0;
BA_ "GenMsgCycleTime" BO_ 921 500;
BA_ "GenMsgSendType" BO_ 921 0;
BA_ "GenMsgCycleTime" BO_ 905 500;
BA_ "GenMsgSendType" BO_ 905 0;
BA_ "GenMsgCycleTime" BO_ 586 100;
BA_ "GenMsgSendType" BO_ 586 0;
BA_ "GenMsgCycleTime" BO_ 810 1000;
BA_ "GenMsgSendType" BO_ 810 0;
BA_ "GenMsgCycleTime" BO_ 874 1000;
BA_ "GenMsgSendType" BO_ 874 0;
BA_ "GenMsgCycleTime" BO_ 841 1000;
BA_ "GenMsgSendType" BO_ 841 0;
BA_ "GenMsgCycleTime" BO_ 1082 1000;
BA_ "GenMsgSendType" BO_ 1082 0;
BA_ "SystemSignalLongSymbol" SG_ 848 APS_w245_eloopRxFromUnexpectedSo "APS_w245_eloopRxFromUnexpectedSourceMAC";
BA_ "SystemSignalLongSymbol" SG_ 848 APS_w246_ethloopSwitchPortLinkDo "APS_w246_ethloopSwitchPortLinkDown";
BA_ "SystemSignalLongSymbol" SG_ 848 APS_w250_ethloopSwitchMemUsageTo "APS_w250_ethloopSwitchMemUsageTooHighPort2";
BA_ "SystemSignalLongSymbol" SG_ 848 APS_w251_ethloopSwitchMemUsageTo "APS_w251_ethloopSwitchMemUsageTooHighPort3";
BA_ "SystemSignalLongSymbol" SG_ 784 APS_w258_qspiFlashSectorChecksum "APS_w258_qspiFlashSectorChecksumMismatch";
BA_ "SystemSignalLongSymbol" SG_ 784 APS_w269_ethSwitchRxPageCountToo "APS_w269_ethSwitchRxPageCountTooHighPort0_3";
BA_ "SystemSignalLongSymbol" SG_ 784 APS_w270_ethSwitchRxPageCountToo "APS_w270_ethSwitchRxPageCountTooHighPort4_7";
BA_ "SystemSignalLongSymbol" SG_ 784 APS_w284_cam12VBuckBoostAPwrIssu "APS_w284_cam12VBuckBoostAPwrIssue";
BA_ "SystemSignalLongSymbol" SG_ 784 APS_w285_cam12VBuckBoostBPwrIssu "APS_w285_cam12VBuckBoostBPwrIssue";
BA_ "SystemSignalLongSymbol" SG_ 784 APS_w286_cam12VEFuseAPrimaryIssu "APS_w286_cam12VEFuseAPrimaryIssue";
BA_ "SystemSignalLongSymbol" SG_ 784 APS_w287_cam12VEFuseASecondaryIs "APS_w287_cam12VEFuseASecondaryIssue";
BA_ "SystemSignalLongSymbol" SG_ 784 APS_w290_cam12VBuckBoostBPwrRing "APS_w290_cam12VBuckBoostBPwrRinging";
BA_ "SystemSignalLongSymbol" SG_ 784 APS_w298_cpuToApCanSharedMemErro "APS_w298_cpuToApCanSharedMemError";
BA_ "SystemSignalLongSymbol" SG_ 784 APS_w299_apToCpuCanSharedMemErro "APS_w299_apToCpuCanSharedMemError";
BA_ "SystemSignalLongSymbol" SG_ 784 APS_w318_ethernetNetworkBufferHi "APS_w318_ethernetNetworkBufferHighWatermark";
BA_ "SystemSignalLongSymbol" SG_ 784 APS_w320_eplannerPreconditionsMe "APS_w320_eplannerPreconditionsMet";
BA_ "Confidence" SG_ 1465 DAS_alertID 1;
BA_ "Confidence" SG_ 1465 DAS_alertState 1;
BA_ "Confidence" SG_ 1465 DAS_sw073_escalateLDWreason 1;
BA_ "Confidence" SG_ 1465 DAS_sw073_freespaceLeftC0 1;
BA_ "Confidence" SG_ 1465 DAS_sw073_freespaceRightC0 1;
BA_ "Confidence" SG_ 1465 DAS_sw073_freespaceLeftC1 1;
BA_ "Confidence" SG_ 1465 DAS_sw073_freespaceRightC1 1;
BA_ "Confidence" SG_ 1465 DAS_sw073_freespaceLeftFarZ 1;
BA_ "Confidence" SG_ 1465 DAS_sw073_freespaceRightFarZ 1;
BA_ "Confidence" SG_ 401 DAS_rmfActive 0;
BA_ "Confidence" SG_ 401 DAS_autonomyUnsupervisedActive 0;
BA_ "Confidence" SG_ 401 DAS_autonomyUnavailableReason 0;
BA_ "Confidence" SG_ 583 DAS_roadEstimator 0;
BA_ "Confidence" SG_ 583 DAS_arbiterBehavior 0;
BA_ "Confidence" SG_ 583 DAS_mapAvailability 0;
BA_ "Confidence" SG_ 583 DAS_controllerRef 0;
BA_ "Confidence" SG_ 583 DAS_alcInternalState 0;
BA_ "Confidence" SG_ 583 DAS_behaviorReport 0;
BA_ "Confidence" SG_ 583 DAS_constructionZone 0;
BA_ "Confidence" SG_ 583 DAS_controllerHealth 0;
BA_ "Confidence" SG_ 583 DAS_controlDistance 0;
BA_ "Confidence" SG_ 583 DAS_autopilotAbortReason 0;
BA_ "Confidence" SG_ 583 DAS_rqstedBehaviorStatus 0;
BA_ "Confidence" SG_ 583 DAS_forkState 0;
BA_ "Confidence" SG_ 583 DAS_laneChangeState 0;
BA_ "Confidence" SG_ 583 DAS_lastWatchdogCode 0;
BA_ "Confidence" SG_ 1497 DAS_carLogMultiplexer 1;
BA_ "Confidence" SG_ 1497 DAS_radarTarget5_dx 0;
BA_ "Confidence" SG_ 1497 DAS_radarTarget1_dx 0;
BA_ "Confidence" SG_ 1497 DAS_radarTarget1_VxRel 0;
BA_ "Confidence" SG_ 1497 DAS_mobileyeVehAebFlag 0;
BA_ "Confidence" SG_ 1497 DAS_mobileyePedAebFlag 0;
BA_ "Confidence" SG_ 1497 DAS_mobileyeIPSOapproved 0;
BA_ "Confidence" SG_ 1497 DAS_fcmSteeringOverride 0;
BA_ "Confidence" SG_ 1497 DAS_fcmCollisionStage3Checks 0;
BA_ "Confidence" SG_ 1497 DAS_fcmThreatAssesmentMode 0;
BA_ "Confidence" SG_ 1497 DAS_constructionArea 0;
BA_ "Confidence" SG_ 1497 DAS_restrictionLowSpeedTraffic 0;
BA_ "Confidence" SG_ 1497 DAS_associated_rad_object 0;
BA_ "Confidence" SG_ 1497 DAS_LC_handsOnReason 0;
BA_ "Confidence" SG_ 1497 DAS_ACC_camStatus 0;
BA_ "Confidence" SG_ 1497 DAS_aeb_not_activating_reason 0;
BA_ "Confidence" SG_ 1497 DAS_handsOnDetected 0;
BA_ "GenSigSNA" SG_ 1497 DAS_handsOnDetected "0";
BA_ "Confidence" SG_ 1497 DAS_driveOnNavUnavailableReason 0;
BA_ "Confidence" SG_ 1497 DAS_accUnavailableReason 0;
BA_ "Confidence" SG_ 1497 DAS_pmmNotActivatingReason 0;
BA_ "Confidence" SG_ 1497 DAS_desiredTarget_dx 0;
BA_ "GenSigSNA" SG_ 1497 DAS_desiredTarget_dx "255";
BA_ "Confidence" SG_ 1497 DAS_radarTarget2_dx 0;
BA_ "Confidence" SG_ 1497 DAS_radarTarget3_dx 0;
BA_ "Confidence" SG_ 1497 DAS_radarTarget4_dx 0;
BA_ "Confidence" SG_ 1497 DAS_closestInLaneTargetDx 0;
BA_ "Confidence" SG_ 1497 DAS_secondInLaneTargetDx 0;
BA_ "Confidence" SG_ 1497 DAS_closestLeftLaneTargetDx 0;
BA_ "Confidence" SG_ 1497 DAS_closestRightLaneTargetDx 0;
BA_ "Confidence" SG_ 1497 DAS_closestInLaneTargetVxRel 0;
BA_ "Confidence" SG_ 970 DAS_gpsStatusMultiplexer 1;
BA_ "Confidence" SG_ 970 DAS_gpsTransportModeState 0;
BA_ "Confidence" SG_ 970 DAS_gpsSatsInUseHardware 0;
BA_ "Confidence" SG_ 970 DAS_gpsRejectingSatData 0;
BA_ "Confidence" SG_ 970 DAS_gpsWheelsOffMotionDetected 0;
BA_ "Confidence" SG_ 970 DAS_gpsFixTypeHardware 0;
BA_ "Confidence" SG_ 970 DAS_gpsRawxEnabled 0;
BA_ "Confidence" SG_ 970 DAS_gpsRxmRawxMia 0;
BA_ "Confidence" SG_ 970 DAS_gpsRxmSfrbxMia 0;
BA_ "Confidence" SG_ 970 DAS_gpsEsfMeasMia 0;
BA_ "Confidence" SG_ 970 DAS_gpsEsfRawMia 0;
BA_ "Confidence" SG_ 970 DAS_gpsNavStatusMia 0;
BA_ "Confidence" SG_ 970 DAS_gpsSoftwareConfigured 0;
BA_ "Confidence" SG_ 970 DAS_gpsSoftwareUsed 0;
BA_ "Confidence" SG_ 970 DAS_gpsSoftwareFastStartReady 0;
BA_ "Confidence" SG_ 970 DAS_gpsSatsInUseSoftware 0;
BA_ "Confidence" SG_ 970 DAS_gpsFixTypeSoftware 0;
BA_ "Confidence" SG_ 970 DAS_gpsCWJammingInidcator 0;
BA_ "Confidence" SG_ 970 DAS_gpsJammingState 0;
BA_ "Confidence" SG_ 970 DAS_gpsSpoofDetectorState 0;
BA_ "Confidence" SG_ 970 DAS_gpsInvalidMsgPercentage 0;
BA_ "Confidence" SG_ 970 DAS_gnssConstellationsState 0;
BA_ "Confidence" SG_ 970 DAS_gpsReceiverNoiseLevel 0;
BA_ "Confidence" SG_ 970 DAS_gpsAutomaticGainControl 0;
BA_ "Confidence" SG_ 970 DAS_gpsPreviousPositionDeltaHw 0;
BA_ "Confidence" SG_ 970 DAS_gpsPreviousPositionDeltaSw 0;
BA_ "Confidence" SG_ 970 DAS_gpsNmeaDispatchFailureCount 0;
BA_ "Confidence" SG_ 970 DAS_gnssMaxInstantaneousCnorGps 0;
BA_ "Confidence" SG_ 970 DAS_gnssMaxInstantaneousCnorGal 0;
BA_ "Confidence" SG_ 970 DAS_gnssMaxInstantaneousCnorBds 0;
BA_ "Confidence" SG_ 970 DAS_gpsResetReason 0;
BA_ "Confidence" SG_ 970 DAS_gpsAccuracyHorizontal 0;
BA_ "Confidence" SG_ 970 DAS_gpsAccuracyVertical 0;
BA_ "Confidence" SG_ 970 DAS_gpsSolutionFallback 0;
BA_ "Confidence" SG_ 970 DAS_gpsToMcuSource 0;
BA_ "Confidence" SG_ 970 DAS_gpsSolutionSoc 0;
BA_ "Confidence" SG_ 970 DAS_gpsRedundancyActive 0;
BA_ "Confidence" SG_ 970 DAS_gpsFixTypeSoftwareSocB 0;
BA_ "Confidence" SG_ 970 DAS_gpsSatsInUseSoftwareSocB 0;
BA_ "Confidence" SG_ 970 DAS_gnssNumSatsGps 0;
BA_ "Confidence" SG_ 970 DAS_gnssNumSatsGal 0;
BA_ "Confidence" SG_ 970 DAS_gnssNumSatsBds 0;
BA_ "Confidence" SG_ 970 DAS_gnssAvgInstantaneousCnorGps 0;
BA_ "Confidence" SG_ 970 DAS_gnssAvgInstantaneousCnorGal 0;
BA_ "Confidence" SG_ 970 DAS_gnssAvgInstantaneousCnorBds 0;
BA_ "Confidence" SG_ 970 DAS_gnssAvgInstantaneousCnorGpsL 0;
BA_ "SystemSignalLongSymbol" SG_ 970 DAS_gnssAvgInstantaneousCnorGpsL "DAS_gnssAvgInstantaneousCnorGpsLowBand";
BA_ "Confidence" SG_ 970 DAS_gnssAvgInstantaneousCnorGalL 0;
BA_ "SystemSignalLongSymbol" SG_ 970 DAS_gnssAvgInstantaneousCnorGalL "DAS_gnssAvgInstantaneousCnorGalLowBand";
BA_ "Confidence" SG_ 970 DAS_gnssAvgInstantaneousCnorBdsL 0;
BA_ "SystemSignalLongSymbol" SG_ 970 DAS_gnssAvgInstantaneousCnorBdsL "DAS_gnssAvgInstantaneousCnorBdsLowBand";
BA_ "Confidence" SG_ 1337 DAS_infoIndex 1;
BA_ "Confidence" SG_ 1337 DAS_infoBuildType 0;
BA_ "Confidence" SG_ 1337 DAS_infoBuildConfigID 0;
BA_ "Confidence" SG_ 1337 DAS_infoHardwareID 0;
BA_ "Confidence" SG_ 1337 DAS_infoComponentID 0;
BA_ "Confidence" SG_ 1337 DAS_infoPcbaID 0;
BA_ "Confidence" SG_ 1337 DAS_infoAssemblyID 0;
BA_ "Confidence" SG_ 1337 DAS_infoUsageID 0;
BA_ "Confidence" SG_ 1337 DAS_infoSubUsageID 0;
BA_ "Confidence" SG_ 1337 DAS_infoApplicationCRC 0;
BA_ "Confidence" SG_ 1337 DAS_infoAppGitHashBytes 0;
BA_ "Confidence" SG_ 1337 DAS_infoBootGitHashBytes 0;
BA_ "Confidence" SG_ 569 DAS_leftLaneExists 0;
BA_ "Confidence" SG_ 569 DAS_rightLaneExists 0;
BA_ "Confidence" SG_ 569 DAS_virtualLaneWidth 0;
BA_ "Confidence" SG_ 569 DAS_virtualLaneViewRange 0;
BA_ "Confidence" SG_ 569 DAS_virtualLaneC0 0;
BA_ "Confidence" SG_ 569 DAS_virtualLaneC1 0;
BA_ "Confidence" SG_ 569 DAS_virtualLaneC2 0;
BA_ "Confidence" SG_ 569 DAS_virtualLaneC3 0;
BA_ "Confidence" SG_ 569 DAS_leftLineUsage 0;
BA_ "Confidence" SG_ 569 DAS_rightLineUsage 0;
BA_ "Confidence" SG_ 569 DAS_leftFork 0;
BA_ "Confidence" SG_ 569 DAS_rightFork 0;
BA_ "Confidence" SG_ 569 DAS_lanesCounter 0;
BA_ "Confidence" SG_ 921 DAS_autopilotState 0;
BA_ "GenSigSNA" SG_ 921 DAS_autopilotState "15";
BA_ "Confidence" SG_ 921 DAS_blindSpotRearLeft 0;
BA_ "GenSigSNA" SG_ 921 DAS_blindSpotRearLeft "3";
BA_ "Confidence" SG_ 921 DAS_blindSpotRearRight 0;
BA_ "GenSigSNA" SG_ 921 DAS_blindSpotRearRight "3";
BA_ "Confidence" SG_ 921 DAS_fusedSpeedLimit 0;
BA_ "GenSigSNA" SG_ 921 DAS_fusedSpeedLimit "0";
BA_ "Confidence" SG_ 921 DAS_suppressSpeedWarning 0;
BA_ "Confidence" SG_ 921 DAS_summonObstacle 0;
BA_ "Confidence" SG_ 921 DAS_summonClearedGate 0;
BA_ "Confidence" SG_ 921 DAS_visionOnlySpeedLimit 0;
BA_ "GenSigSNA" SG_ 921 DAS_visionOnlySpeedLimit "0";
BA_ "Confidence" SG_ 921 DAS_heaterState 0;
BA_ "GenSigSNA" SG_ 921 DAS_heaterState "0";
BA_ "Confidence" SG_ 921 DAS_forwardCollisionWarning 0;
BA_ "GenSigSNA" SG_ 921 DAS_forwardCollisionWarning "3";
BA_ "Confidence" SG_ 921 DAS_autoparkReady 0;
BA_ "Confidence" SG_ 921 DAS_autoParked 0;
BA_ "Confidence" SG_ 921 DAS_autoparkActive 0;
BA_ "Confidence" SG_ 921 DAS_summonFwdLeashReached 0;
BA_ "Confidence" SG_ 921 DAS_summonRvsLeashReached 0;
BA_ "Confidence" SG_ 921 DAS_lssState 0;
BA_ "Confidence" SG_ 921 DAS_sideCollisionAvoid 0;
BA_ "GenSigSNA" SG_ 921 DAS_sideCollisionAvoid "3";
BA_ "Confidence" SG_ 921 DAS_sideCollisionWarning 0;
BA_ "Confidence" SG_ 921 DAS_sideCollisionInhibit 0;
BA_ "Confidence" SG_ 921 DAS_laneDepartureWarning 0;
BA_ "GenSigSNA" SG_ 921 DAS_laneDepartureWarning "5";
BA_ "Confidence" SG_ 921 DAS_fleetSpeedState 0;
BA_ "Confidence" SG_ 921 DAS_autopilotHandsOnState 0;
BA_ "GenSigSNA" SG_ 921 DAS_autopilotHandsOnState "15";
BA_ "Confidence" SG_ 921 DAS_autoLaneChangeState 0;
BA_ "GenSigSNA" SG_ 921 DAS_autoLaneChangeState "31";
BA_ "Confidence" SG_ 921 DAS_summonAvailable 0;
BA_ "Confidence" SG_ 921 DAS_statusCounter 0;
BA_ "Confidence" SG_ 921 DAS_statusChecksum 0;
BA_ "Confidence" SG_ 905 DAS_accSpeedLimit 0;
BA_ "GenSigSNA" SG_ 905 DAS_accSpeedLimit "511";
BA_ "Confidence" SG_ 905 DAS_versionIdentifier 0;
BA_ "Confidence" SG_ 905 DAS_pmmObstacleSeverity 0;
BA_ "GenSigSNA" SG_ 905 DAS_pmmObstacleSeverity "7";
BA_ "Confidence" SG_ 905 DAS_pmmLoggingRequest 0;
BA_ "Confidence" SG_ 905 DAS_activationFailureStatus 0;
BA_ "Confidence" SG_ 905 DAS_pmmUltrasonicsFaultReason 0;
BA_ "Confidence" SG_ 905 DAS_pmmRadarFaultReason 0;
BA_ "Confidence" SG_ 905 DAS_pmmSysFaultReason 0;
BA_ "Confidence" SG_ 905 DAS_pmmCameraFaultReason 0;
BA_ "Confidence" SG_ 905 DAS_ACC_report 0;
BA_ "Confidence" SG_ 905 DAS_relaxCruiseLimits 0;
BA_ "Confidence" SG_ 905 DAS_csaState 0;
BA_ "Confidence" SG_ 905 DAS_radarTelemetry 0;
BA_ "Confidence" SG_ 905 DAS_robState 0;
BA_ "Confidence" SG_ 905 DAS_driverInteractionLevel 0;
BA_ "Confidence" SG_ 905 DAS_ppOffsetDesiredRamp 0;
BA_ "Confidence" SG_ 905 DAS_longCollisionWarning 0;
BA_ "GenSigSNA" SG_ 905 DAS_longCollisionWarning "15";
BA_ "Confidence" SG_ 905 DAS_status2Counter 0;
BA_ "Confidence" SG_ 905 DAS_status2Checksum 0;
BA_ "Confidence" SG_ 1625 DAS_udsResponseData 1;
BA_ "Confidence" SG_ 586 DAS_autosteerVehiclesUsage 0;
BA_ "Confidence" SG_ 586 DAS_autosteerHPPUsage 0;
BA_ "Confidence" SG_ 586 DAS_autosteerNavigationUsage 0;
BA_ "Confidence" SG_ 586 DAS_autosteerModelUsage 0;
BA_ "Confidence" SG_ 586 DAS_autosteerBottsDotsUsage 0;
BA_ "Confidence" SG_ 586 DAS_offsetSide 0;
BA_ "Confidence" SG_ 586 DAS_roadSurfaceType 0;
BA_ "GenSigSNA" SG_ 586 DAS_roadSurfaceType "0";
BA_ "Confidence" SG_ 586 DAS_autosteerHealthAnomalyLevel 0;
BA_ "Confidence" SG_ 586 DAS_autosteerHealthState 0;
BA_ "Confidence" SG_ 586 DAS_lastLinePreferenceReason 0;
BA_ "Confidence" SG_ 586 DAS_plannerState 0;
BA_ "Confidence" SG_ 586 DAS_lastAutosteerAbortReason 0;
BA_ "Confidence" SG_ 586 DAS_devAppInterfaceEnabled 0;
BA_ "Confidence" SG_ 586 DAS_navAvailable 0;
BA_ "Confidence" SG_ 586 DAS_navDistance 0;
BA_ "Confidence" SG_ 586 DAS_accSmartSpeedActive 0;
BA_ "Confidence" SG_ 586 DAS_accSmartSpeedState 0;
BA_ "GenSigSNA" SG_ 586 DAS_accSmartSpeedState "7";
BA_ "Confidence" SG_ 586 DAS_ulcInProgress 0;
BA_ "Confidence" SG_ 586 DAS_trafficAwareSetSpeedInUse 0;
BA_ "Confidence" SG_ 586 DAS_isaSystemState 0;
BA_ "Confidence" SG_ 586 DAS_behaviorType 0;
BA_ "Confidence" SG_ 586 DAS_ulcType 0;
BA_ "Confidence" SG_ 586 DAS_rearVehDetectedThisCycle 0;
BA_ "Confidence" SG_ 586 DAS_rearLeftVehDetectedCurrent 0;
BA_ "Confidence" SG_ 586 DAS_rearRightVehDetectedTrip 0;
BA_ "Confidence" SG_ 586 DAS_rearLeftVehDetectedTrip 0;
BA_ "Confidence" SG_ 1425 EPAS3S_alertID 1;
BA_ "Confidence" SG_ 1425 EPAS3S_alertState 1;
BA_ "Confidence" SG_ 1425 EPAS3S_a147_transitionReason 1;
BA_ "Confidence" SG_ 1425 EPAS3S_a149_pcbTemp 1;
BA_ "Confidence" SG_ 1425 EPAS3S_a150_pcbTemp 1;
BA_ "Confidence" SG_ 1425 EPAS3S_a150_phaUMainPathCalcDiff 1;
BA_ "Confidence" SG_ 1425 EPAS3S_a150_phaVMainPathCalcDiff 1;
BA_ "SystemSignalLongSymbol" SG_ 1425 EPAS3S_a150_otherECUAssistStatus "EPAS3S_a150_otherECUAssistStatusFlag";
BA_ "Confidence" SG_ 1425 EPAS3S_a155_vehicleSpeed 1;
BA_ "Confidence" SG_ 1425 EPAS3S_a156_vehicleSpeed 1;
BA_ "Confidence" SG_ 1425 EPAS3S_a160_currentSensorStatus 1;
BA_ "Confidence" SG_ 1425 EPAS3S_a160_gateDriverStatus 1;
BA_ "Confidence" SG_ 1425 EPAS3S_a160_highSideDisconnectFe 1;
BA_ "SystemSignalLongSymbol" SG_ 1425 EPAS3S_a160_highSideDisconnectFe "EPAS3S_a160_highSideDisconnectFetStatus";
BA_ "Confidence" SG_ 1425 EPAS3S_a160_phaseDisconnectFetSt 1;
BA_ "SystemSignalLongSymbol" SG_ 1425 EPAS3S_a160_phaseDisconnectFetSt "EPAS3S_a160_phaseDisconnectFetStatus";
BA_ "Confidence" SG_ 1425 EPAS3S_a160_inverterFetStatus 1;
BA_ "Confidence" SG_ 1425 EPAS3S_a160_hsdFetFailShortTest 1;
BA_ "Confidence" SG_ 1425 EPAS3S_a160_phaDisconnFailOpenTe 1;
BA_ "SystemSignalLongSymbol" SG_ 1425 EPAS3S_a160_phaDisconnFailOpenTe "EPAS3S_a160_phaDisconnFailOpenTest";
BA_ "Confidence" SG_ 1425 EPAS3S_a160_phaDisconnFailShortT 1;
BA_ "SystemSignalLongSymbol" SG_ 1425 EPAS3S_a160_phaDisconnFailShortT "EPAS3S_a160_phaDisconnFailShortTest";
BA_ "Confidence" SG_ 1425 EPAS3S_a160_invFetInitTest 1;
BA_ "Confidence" SG_ 1425 EPAS3S_a160_gateDrvrInitTest 1;
BA_ "SystemSignalLongSymbol" SG_ 1425 EPAS3S_a160_latentFaultTestTimeo "EPAS3S_a160_latentFaultTestTimeout";
BA_ "Confidence" SG_ 1425 EPAS3S_a161_pcoMinPhaseBCurrent 1;
BA_ "Confidence" SG_ 1425 EPAS3S_a161_pcoMaxPhaseBCurrent 1;
BA_ "Confidence" SG_ 1425 EPAS3S_a161_pcoMinPhaseACurrent 1;
BA_ "Confidence" SG_ 1425 EPAS3S_a161_pcoMaxPhaseACurrent 1;
BA_ "Confidence" SG_ 1425 EPAS3S_a162_vBridgeClosed 1;
BA_ "Confidence" SG_ 1425 EPAS3S_a162_vBridgeOpen 1;
BA_ "Confidence" SG_ 1425 EPAS3S_a163_gateDrvrStatusReg 1;
BA_ "Confidence" SG_ 1425 EPAS3S_a163_gateDrvrDiag2Reg 1;
BA_ "Confidence" SG_ 1425 EPAS3S_a163_gateDrvrDiag1Reg 1;
BA_ "Confidence" SG_ 1425 EPAS3S_a163_gateDrvrDiag0Reg 1;
BA_ "Confidence" SG_ 1425 EPAS3S_a164_dcsRegister0x19 1;
VAL_ 1465 DAS_alertID 232 "w232_laneChangeRequested" 231 "w231_idfEvent" 230 "w230_alcUltrasoundBlocked" 229 "w229_alcUltrasoundDamaged" 228 "w228_DEPRECATED" 227 "w227_virtualWallBlocked" 226 "w226_lcCamCalNeededSpeedLmt" 225 "w225_lcDegradedVisSpeedLmt" 224 "w224_accCameraCalibration" 223 "w223_accObjectInPath" 222 "w222_accCameraBlind" 221 "w221_accRadarBlind" 220 "w220_lcTempUnavailableRoad" 219 "w219_lcTempUnavailableSpeed" 218 "w218_lcSpeedExceededLimit" 217 "w217_lcUnavailableSpeeding" 216 "w216_driverOverriding" 215 "w215_contDriverNotIntracting" 214 "w214_driverNotIntracting" 213 "w213_autosteerStruckOut" 212 "w212_lcUnavailableStrikeOut" 211 "w211_accNoSeatBelt" 210 "w210_camObstrcted" 209 "w209_autoSummonRequest" 208 "w208_rackDetected" 207 "w207_autosteerUnavailable" 206 "w206_autosteerNotEnabled" 205 "w205_apcFinalRear" 204 "w204_apcFinalFront" 203 "w203_apcActivation" 202 "w202_scwNoisyEnvironment" 201 "w201_lcAborting" 200 "w200_lcSlowdown" 199 "w199_apcAbort" 198 "w198_tsrUnavailable" 197 "w197_redLightWarning" 196 "w196_stopSignWarning" 195 "w195_scwUnavailable" 194 "w194_accDriverResumeRqrd" 193 "w193_camWindshieldUnclean" 181 "w181_rRepeatCamCalSaved" 180 "w180_lRepeatCamCalSaved" 179 "w179_rPillarCamCalSaved" 178 "w178_lPillarCamCalSaved" 177 "w177_fisheyeCamCalSaved" 175 "w175_rRepeatCamExtNotCal" 174 "w174_lRepeatCamExtNotCal" 173 "w173_rPillarCamExtNotCal" 172 "w172_lPillarCamExtNotCal" 171 "w171_fisheyeCamExtNotCal" 144 "w144_selfieCamInitFault" 143 "w143_IDF_event" 142 "w142_fwdCamPitchProblem" 141 "w141_ECU_Thermal_Issue" 140 "w140_backupCamInitFault" 139 "w139_rRepeatCamInitFault" 138 "w138_lRepeatCamInitFault" 137 "w137_rPillarCamInitFault" 136 "w136_lPillarCamInitFault" 135 "w135_fisheyeCamInitFault" 134 "w134_narrowCamInitFault" 133 "w133_mainCamInitFault" 132 "w132_narrowCamCalSaved" 131 "w131_mainCamCalSaved" 130 "w130_narrowCamExtNotCal" 129 "w129_mainCamExtNotCal" 106 "w106_torsionBarCalibrated" 105 "w105_DEPRECATED" 104 "w104_DEPRECATED" 103 "w103_robExperimentalAEB" 102 "w102_DEPRECATED" 101 "w101_DEPRECATED" 100 "w100_DEPRECATED" 99 "w099_DEPRECATED" 98 "w098_DEPRECATED" 97 "w097_DEPRECATED" 96 "w096_DEPRECATED" 95 "w095_DEPRECATED" 94 "w094_DEPRECATED" 93 "w093_DEPRECATED" 92 "w092_DEPRECATED" 91 "w091_DEPRECATED" 90 "w090_DEPRECATED" 89 "w089_DEPRECATED" 88 "w088_DEPRECATED" 87 "w087_DEPRECATED" 86 "w086_robCollision" 85 "w085_pmmSteering" 84 "w084_pmmIPSO" 83 "w083_inPathRADObject" 82 "w082_inPathFSviolation" 81 "w081_pmmActiveBraking" 80 "w080_accFailedActivation" 79 "w079_edrAvailable" 78 "w078_pmmActive2" 77 "w077_pmmActive" 76 "w076_mobilEyeSetC" 75 "w075_scMia" 74 "w074_inPathStationaryObst" 73 "w073_issueEscalatedLDW" 72 "w072_selfparkComplete" 71 "w071_selfparkStarted" 70 "w070_apcIncompleteCal" 69 "w069_apcSpaceMasked" 68 "w068_vlInconsistency" 67 "w067_steeringAlignment" 66 "w066_deserializerLockLost" 65 "w065_deserializerOvercurrent" 64 "w064_epasMia" 63 "w063_parkVersionMismatch" 62 "w062_radcAlignment" 61 "w061_airSuspensionMia" 60 "w060_fcw_event" 59 "w059_parkMia" 58 "w058_epbMia" 57 "w057_mcuMia" 56 "w056_diMia" 55 "w055_radcVersionMismatch" 54 "w054_camAutofix" 53 "w053_radcCommIssue" 52 "w052_radcSensorIssue" 51 "w051_radcEcuIssue" 50 "w050_aeb_event" 49 "w049_eyeqVersionMismatch" 48 "w048_DAS_Features_Disabled" 47 "w047_edrEvent" 46 "w046_eepromRecordAbsent" 45 "w045_radMia" 44 "w044_appMobileyeFailure" 43 "w043_camLongRunTime" 42 "w042_autopilotAborting" 41 "w041_autopilotRateSaturated" 40 "w040_autopilotAngleSaturated" 39 "w039_sdm_rcm_Mia" 38 "w038_camFailure" 37 "w037_camTacIssue" 36 "w036_bdyMia" 35 "w035_espMia" 34 "w034_sccmMia" 33 "w033_gtwMia" 32 "w032_canTxError" 31 "w031_canRxError" 30 "w030_Heater_Issue" 29 "w029_spi_tx_error" 28 "w028_spi_rx_error" 27 "w027_ECU_Reset_Fault" 26 "w026_ECU_timingIssue" 25 "w025_LC_Steering_Override" 24 "w024_ECU_Watchdog_Reset" 23 "w023_ECU_Cam_Statemismatc" 22 "w022_ECU_EEPROM_Failure" 21 "w021_ECU_Temperature_Issue" 20 "w020_ECU_checkstopError" 19 "w019_ECU_Stack_Overflow" 18 "w018_ECU_Power_Issue" 17 "w017_Cam_Msg_MIA" 16 "w016_aeb_e_event" 15 "w015_Camera_Failsafes" 14 "w014_swAssert" 13 "w013_Cam_Watchdog" 12 "w012_Cam_BootFailure" 11 "w011_scaEvent" 10 "w010_radcCalibIssue" 9 "w009_aebFault" 8 "w008_parkDisabled" 7 "w007_ahlbDisabled" 6 "w006_aebCancelled" 5 "w005_fcwCancelled" 4 "w004_accDisabled" 3 "w003_isaDisabled" 2 "w002_ldwDisabled" 0 "ALERT_DO_NOT_USE_ZERO" ;
VAL_ 1465 DAS_alertState 1 "SET" 0 "CLEARED" ;
VAL_ 1465 DAS_sw073_escalateLDWreason 4 "SELFIE" 3 "STW_TAKEOVER" 2 "DOUBLE_PULL" 1 "SINGLE_PULL" 0 "NONE" ;
VAL_ 401 DAS_rmfActive 1 "TRUE" 0 "FALSE" ;
VAL_ 401 DAS_autonomyUnsupervisedActive 1 "TRUE" 0 "FALSE" ;
VAL_ 401 DAS_autonomyUnavailableReason 414 "TRAJECTORY_ON_PUBLIC_ROAD_NOT_INDOORS" 413 "STOP_IN_LANE_NOT_HONORED" 412 "SIMPLE_SUMMON_OBSTACLE_BLOCKED" 411 "SEVERE_SINGLE_FRONT_VISION_OCCLUSION_AFTER_WIPE" 410 "PHONE_TOO_FAR_TO_START" 409 "MAX_SPEED_LIMIT_FOR_MODE_EXCEEDED" 408 "EPB_REDUNDANT_BRAKING_UNAVAILABLE" 407 "EGO_GEAR_NOT_ALLOWED" 406 "EGO_EXCEEDED_MAX_SUMMON_DISTANCE" 405 "DUAL_EPB_UNAVAILABLE" 404 "COMPRESSOR_FRAME_DROP_RATE_HIGH" 403 "CAN_RX_VALIDATION_ERROR" 402 "BRAKE_APPLIED_PARKED" 401 "ALARM_ACTIVE" 400 "SAFETY_DRIVER_UNBUCKLED_PRE_ACTIVATION" 399 "NOT_FACTORY_SCHEDULE" 398 "FSD_REGION_NOT_ALLOWED" 397 "FSD_QUIZ_REQUIRED" 396 "EPAS_EAC_NOT_ACTIVE_OTHER" 395 "EPAS_EAC_NOT_ACTIVE_HANDS_ON" 394 "DI_CONTROL_INTEGRATOR_WINDUP" 393 "SEVERE_SINGLE_FRONT_VISION_OCCLUSION_HIGH_FOGGING_RISK" 392 "EGO_NEAR_SUMMON_MAP_BOUNDARY_NOT_INDOORS" 391 "GOAL_NEAR_SUMMON_MAP_BOUNDARY_NOT_INDOORS" 390 "GRADE_TOO_HIGH_WITHOUT_REDUNDANT_BRAKING_LOW_MU" 389 "NAV_DESTINATION_OUTSIDE_GEOFENCE" 388 "RCM_COLLISION_SEVERITY_TRIGGERED" 387 "EPB_PARKING_AVAILABILITY_TOO_STEEP" 386 "REVERSE_GEAR_NOT_AVAILABLE" 385 "DESTINATION_OUTSIDE_GEOFENCE_AP" 384 "SSD_CLIP_LOGGING_CRITICAL" 383 "DRIVE_GEAR_NOT_AVAILABLE" 382 "SIDE_VISIBILITY_DEGRADED_PARKED_DOORS_CLOSED" 381 "PERSISTENT_FRAME_DROPS" 380 "PERSISTENT_HANDS_ON_NOT_ALLOWED" 379 "NAV_ROUTE_EXCEEDS_GEOFENCE_BUFFER" 378 "RANKER_OUTPUT_STALE" 377 "VISION_PLANNER_STALE" 376 "AUTO_WIPERS_OFF" 375 "COUNTRY_NOT_ALLOWED_FOR_OPERATION" 374 "OUTSIDE_TRACK_TEST_GEOFENCE" 373 "TEMPERATURE_EXCEEDS_ODD" 372 "RIDESHARE_NAV_GOAL_NOT_IN_SYNC" 371 "HV_BATTERY_AC_CHARGING_UNHEALTHY" 370 "HV_BATTERY_DC_CHARGING_UNHEALTHY" 369 "UI_RIDE_SETUP_IN_PROGRESS" 368 "AUTO_HEADLIGHTS_OFF" 367 "IMMOBILIZER_AUTH_AUTONOMY" 366 "DI_RESTRICTED_DRIVING_MANUAL_RECOVERY" 365 "SUMMON_ACTIVE_DURATION_EXCEEDED" 364 "ESKF_SPEED_SOURCE_ACTIVE" 363 "IMU_DATA_NOT_RELIABLE_WITH_FLEET_CONFIG_ENABLED" 362 "FASCIA_VISION_OCCLUSION_AT_LONG_STOP" 361 "HIGH_SPEED_ROAD_ON_ROUTE" 360 "EGO_ON_HIGH_SPEED_ROAD" 359 "UNACCOMPANIED_UNDERAGE_RIDER_DETECTED" 358 "AEB_FAULTED" 357 "AUDIO_HARDWARE_ODIN_FAILED" 356 "FASCIA_VISION_FAILSAFE_PARKED" 355 "APS_B_EPLANNER_NO_VALID_TRAJECTORY" 354 "APS_A_EPLANNER_NO_VALID_TRAJECTORY" 353 "FASCIA_CAM_INTEGRATED_HEATER_FAULT" 352 "BACKUP_CAM_INTEGRATED_HEATER_FAULT" 351 "RIGHT_REPEATER_CAM_INTEGRATED_HEATER_FAULT" 350 "LEFT_REPEATER_CAM_INTEGRATED_HEATER_FAULT" 349 "RIGHT_PILLAR_CAM_INTEGRATED_HEATER_FAULT" 348 "LEFT_PILLAR_CAM_INTEGRATED_HEATER_FAULT" 347 "RIGHT_PILLAR_CAM_WIRE_HEATER_FAULT" 346 "LEFT_PILLAR_CAM_WIRE_HEATER_FAULT" 345 "WINDSHIELD_CAM_WIRE_HEATER_FAULT" 344 "CONTROLLER_EPLANNER_UNHEALTHY" 343 "VEHICLE_COLLISION_DETECTED" 342 "VRU_COLLISION_DETECTED" 341 "MAJOR_COLLISION_DETECTED" 340 "ONGOING_COLLISION_DETECTED" 339 "INTEGRATOR_ACCELERATION_INVALID" 338 "CABIN_CAM_DRIVER_MONITORING_SYSTEM_UNAVAILABLE" 337 "DCAS_DRIVER_ATTENTION_STATE_DETERMINATION_DEGRADED" 336 "NON_MAIN_FRONT_CAMERAS_STREAM_LOST" 335 "MAIN_CAMERA_STREAM_LOST" 334 "DRIVER_WIPER_WASH_HEALTH_DEGRADED" 333 "EPB_AUTONOMY_BEHAVIOR_MISMATCH" 332 "DI_AUTONOMY_BEHAVIOR_MISMATCH" 331 "VC_AUTONOMY_BEHAVIOR_MISMATCH" 330 "DCAS_EXITED_REGION_TIMEOUT" 329 "WASHER_PUMP_NOT_HEALTHY" 328 "AP_B_SOC_UNHEALTHY" 327 "RCM_AIR_BAG_DEPLOY" 326 "RCM_NEAR_DEPLOY" 325 "AP_A_SOC_UNHEALTHY" 324 "ROUTE_EXCEEDS_SPEED_LIMIT" 323 "PERSISTENT_INVALID_NAV_ROUTE" 322 "NAV_ROUTE_EXITS_GEOFENCE" 321 "NAV_AVOID_HIGH_SPEED_ROADS_DISABLED" 320 "NAV_WHITELIST_ROUTING_DISABLED" 319 "NAV_ROUTE_RANKER_DISABLED" 318 "NAV_AVOID_SHORT_LANE_CHANGE_DISABLED" 317 "NAV_AVOID_UNPROTECTED_TURN_DISABLED" 316 "HIGHWAY_ON_ROUTE" 315 "EGO_ON_HIGHWAY" 314 "INVALID_VEHICLE_OPERATION_MODE" 313 "STEERING_ANGLE_OFFSET_HIGH" 312 "SAFETY_DRIVER_INATTENTIVE" 311 "TRACK_MODE_ACTIVE" 310 "EXT_TEMP_LOW_CERAMIC_BRAKES" 309 "GOAL_NEAR_SUMMON_MAP_BOUNDARY" 308 "SUMMON_HEARTBEAT_MISSING" 307 "EGO_NEAR_SUMMON_MAP_BOUNDARY" 306 "EGO_OUTSIDE_SUMMON_MAP_RADIUS" 305 "SUMMON_MAP_INVALID" 304 "RAW_UI_SUMMON_GOAL_INVALID" 303 "SUMMON_GOAL_INVALID" 302 "SYSTEM_CDP_UNAVAILABLE" 301 "SUMMON_COLLISION_DETECTION_ACTIVE" 300 "PHONE_TOO_FAR" 299 "PHONE_GPS_INVALID" 298 "GRADE_TOO_HIGH_WITHOUT_REDUNDANT_BRAKING" 297 "CABIN_CAM_DRIVER_MONITORING_UNAVAILABLE" 296 "CABIN_CAMERA_STREAM_FAILURE" 295 "DRIVER_PRESENCE_VISION_UNAVAILABLE" 294 "PEDAL_OVERRIDE_EXCEEDS_CONTROLLER_LIMITS" 293 "UPCOMING_FERRY_CROSSING" 292 "DRIVER_PARTIALLY_OCCLUDED" 291 "DRIVER_REQUIREMENTS_NOT_MET_VC" 290 "DRIVER_AGE_REQUIREMENTS_NOT_MET_VISION" 289 "GPS_DEGRADED" 288 "PILLARS_SWAP_DETECTED" 287 "NARROW_FISHEYE_SWAP_DETECTED" 286 "SCCM_MIA" 285 "RECENT_STALK_GEAR_SHIFT" 284 "IBOOSTER_MIA" 283 "PARKING_SPOT_SELECTED" 282 "SCROLL_WHEEL_INTERACTION" 281 "PEDAL_OVERRIDE_STRIKEOUT_FOR_DRIVE" 280 "PEDAL_OVERRIDE_STRIKEOUT" 279 "ABOVE_MAX_ACTIVATION_SPEED" 278 "DRIVER_MONITOR_SUSPENSION_ACTIVE" 277 "DRIVER_MONITOR_STRUCK_OUT_FOR_DRIVE" 276 "VC_CAMERA_AIR_CLEANING_STATUS_MIA" 275 "VC_CAMERA_FLUID_CLEANING_STATUS_MIA" 274 "INVALID_DI_PEDAL_POS" 273 "CABIN_CAMERA_FAN_RPM_FAULT" 272 "SELF_NETWORK_DECRYPTION_NOT_READY" 271 "OFF_ROAD_MODE_ACTIVE" 270 "SSD_CLIP_LOGGING_INACTIVE" 269 "CAMERA_EXPOSURE_INACTIVE" 268 "CAMERA_EXPOSURE_MISMATCH" 267 "CABIN_CAMERA_IR_LED_FAULTED" 266 "TAMPERING_DETECTED" 265 "NO_IMU_SOURCES_AVAILABLE" 264 "IMU_REDUNDANCY_LOST" 263 "DI_AUTONOMY_HEALTH_CAN_MESSAGE_MIA" 262 "ALL_WHEEL_SPEEDS_SENSORS_FAULTED" 261 "WHEEL_SPEEDS_CAN_MESSAGE_MIA" 260 "AP_THERMAL_MODEL_FAULT_DETECTED" 259 "SGK_AUTONOMY_MODE_NOT_IN_SYNC" 258 "SGK_AUTONOMY_STATE_NOT_IN_SYNC" 257 "ANY_RIGHT_DOOR_OPEN_BUTTON_FAULTED" 256 "ANY_LEFT_DOOR_OPEN_BUTTON_FAULTED" 255 "VCRIGHT_DOOR_STATUS_CAN_MESSAGE_MIA" 254 "VCLEFT_DOOR_STATUS_CAN_MESSAGE_MIA" 253 "BB_STATUS_CAN_MESSAGE_MIA" 252 "GTW_CAR_CONFIG_CAN_MESSAGE_MIA" 251 "TRAILER_MODE_ACTIVE" 250 "UI_LIMIT_MODE_ACTIVE" 249 "UI_QT_CAR_UNAVAILABLE" 248 "UI_CONNECTIVITY_HW_UNHEALTHY" 247 "UI_CONNECTIVITY_OFFLINE" 246 "UI_CENTER_DISPLAY_UNAVAILABLE" 245 "UI_HEALTH_STATUS_CAN_MESSAGE_MIA" 244 "ANY_LV_HEALTH_CAN_MESSAGE_INVALID" 243 "ANY_LV_HEALTH_CAN_MESSAGE_MIA" 242 "AP_SYSTEM_ISSUE_PENDING_REBOOT" 241 "AP_TASK_PENDING_REBOOT" 240 "APS_DUAL_CAMERA_POWER_FAILURE" 239 "APS_SINGLE_CAMERA_POWER_FAILURE" 238 "APS_ETH_BRIDGE_DOWN" 237 "APS_PEER_PMIC_FAULTED" 236 "APS_SELF_PMIC_FAULTED" 235 "APS_PEER_VRM_FAULTED" 234 "APS_SELF_VRM_FAULTED" 233 "APS_PEER_IMEM_FAULTED" 232 "APS_SELF_IMEM_FAULTED" 231 "APS_PEER_CAN_FAULTED" 230 "APS_SELF_CAN_FAULTED" 229 "APS_B_UNHEALTHY" 228 "APS_A_UNHEALTHY" 227 "PEER_VISION_FAILOVER_ACTIVE" 226 "ARBITER_SELECTED_BEHAVIOR_OUT_OF_DATE" 225 "ARBITER_SELECTED_BEHAVIOR_NOT_E2E" 224 "MISSION_PLANNER_DESIRED_BEHAVIOR_NOT_E2E" 223 "AUTONOMY_CONTROLLING_AND_NOT_PARKED" 222 "NO_VALID_SGK_STATUS" 221 "AUTONOMOUS_BEHAVIORS_LINK_NOT_ESTABLISHED" 220 "GNSS_PPS_MIA" 219 "GNSS_ANTENNA_DISCONNECTED" 218 "GNSS_UART_FAULTED" 217 "AP_THERMAL_DEGRADED_PULLOVER_REQ" 216 "AP_THERMAL_DEGRADED_BLOCK_ACTIVATION" 215 "DRIVER_PRESENT_NOT_ALLOWED" 214 "UNSUPERVISED_OPERATION_NOT_ALLOWED" 213 "NOT_IN_RT_NO_TAKEOVER_FLEET" 212 "SAFETY_OPERATOR_NOT_PRESENT" 211 "CAMERA_PRECONDITIONING_REQUIRED" 210 "BMS_CAN_MESSAGES_MIA" 209 "VEHICLE_LOSING_HV" 208 "HV_DRIVE_NO_RESTART" 207 "AUTONOMOUS_BEHAVIORS_TASK_SUSPENDING" 206 "AUDIO_BUS_DOWN" 205 "CAMERA_REDUNDANCY_NOT_READY" 204 "NO_VEHICLE_SPEED_SOURCE_AVAILABLE" 203 "DI_PRIMARY_SPEED_SOURCE_UNAVAILABLE" 202 "DI_SPEED_CAN_MESSAGE_MIA" 201 "DEFOG_SYSTEM_UNHEALTHY" 200 "COOLANT_SYSTEM_UNHEALTHY" 199 "DEFOG_SYSTEM_NOT_READY" 198 "COOLANT_SYSTEM_NOT_READY" 197 "NOT_AUTHENTICATED_FOR_DRIVE" 196 "UNASSIGNED_PASSENGER_UNBUCKLED" 195 "WAITING_FOR_PASSENGER_EGRESS" 194 "PASSENGER_UNEXPECTED_RIDE_INACTIVE" 193 "DRIVER_NOT_PRESENT_PRE_ACTIVATION" 192 "NARROW_WASH_NOT_AVAILABLE" 191 "REDUNDANT_IMU_CAN_MESSAGES_MIA" 190 "IMU_CAN_MESSAGES_MIA" 189 "BRAKING_CAN_MESSAGES_MIA" 188 "EPB_AUTONOMY_CAN_MESSAGES_MIA" 187 "PARK_BRAKE_CAN_MESSAGES_MIA" 186 "STEERING_CAN_MESSAGES_MIA" 185 "DI_SYSTEM_STATUS_CAN_MESSAGES_MIA" 184 "DI_CHASSIS_CONTROL_CAN_MESSAGE_MIA" 183 "APS_CAN_MESSAGES_MIA" 182 "POOR_LOCALIZATION_ACCURACY" 181 "VISION_FAILOVER_ACTIVE" 180 "SEAT_OCCUPANCY_STATUS_UNHEALTHY" 179 "TO_STREAMS_UNHEALTHY" 178 "SEATBELT_STATUS_UNHEALTHY" 177 "RCM_WARNING_INDICATOR_ON" 176 "REDUNDANT_BRAKES_FAIL_OPERATIONAL" 175 "REDUNDANT_BRAKES_REDUNDANCY_LOST" 174 "REDUNDANT_BRAKES_NOT_ARMED" 173 "REDUNDANT_BRAKES_NOT_READY" 172 "REDUNDANT_BRAKE_PATH_ACTIVE" 171 "RANKER_NOT_HEALTHY" 170 "PARKED_A_PEDAL_PRESSED" 169 "ANY_CANCEL_ACTIVE" 168 "BRAKE_CONFIRM_PENDING_PARK" 167 "BRAKE_APPLIED_D_R_N" 166 "BRAKE_RELEASE_PENDING_PARK" 165 "ENFORCED_UNPARK_DELAY_ACTIVE" 164 "WIPER_NOT_HEALTHY" 163 "RIGHT_PILLAR_CAM_HEATER_FAULT" 162 "LEFT_PILLAR_CAM_HEATER_FAULT" 161 "WINDSHIELD_CAM_HEATER_FAULT" 160 "ALL_TAIL_LIGHTS_FAULTED_IN_LOW_VIS" 159 "TAIL_LIGHT_FAULTED" 158 "REVERSE_LIGHT_FAULTED" 157 "RIGHT_TURN_LIGHT_FAULTED" 156 "LEFT_TURN_LIGHT_FAULTED" 155 "ALL_BRAKE_LIGHTS_FAULTED" 154 "BRAKE_LIGHT_FAULTED" 153 "HIGH_BEAM_LIGHT_FAULTED_IN_LOW_VIS" 152 "LOW_BEAM_LIGHT_FAULTED_IN_LOW_VIS" 151 "HIGH_BEAM_LIGHT_FAULTED" 150 "LOW_BEAM_LIGHT_FAULTED" 149 "HEADLIGHTS_NOT_AIMED" 148 "HEADLIGHTS_OFF_AT_NIGHT" 147 "AP_REDUNDANCY_UNAVAILABLE" 146 "DI_BRAKING_DECELERATION_UNAVAILABLE" 145 "DI_VDC_ACTIVE" 144 "DI_TC_ACTIVE" 143 "DI_VDC_STATE_NOT_NORMAL" 142 "DI_LOSING_PROPULSION" 141 "EPB_STATUS_NOT_PARKED" 140 "EPB_PARKING_AVAILABILITY_UNKNOWN" 139 "EPB_PARKING_AVAILABILITY_REQUEST_PATH_DEGRADED" 138 "EPB_PARKING_AVAILABILITY_SPEED_INVALID" 137 "EPB_PARKING_AVAILABILITY_FAULTED" 136 "TIRE_PRESSURE_SENSOR_FAULT" 135 "FLAT_TIRE" 134 "INTEGRATOR_HEALTH_CRITICAL" 133 "IMU_DATA_NOT_RELIABLE" 132 "FASCIA_FLUID_CLEAN_CRITICAL" 131 "BACKUP_FLUID_CLEAN_CRITICAL" 130 "RIGHT_REPEATER_FLUID_CLEAN_CRITICAL" 129 "LEFT_REPEATER_FLUID_CLEAN_CRITICAL" 128 "FASCIA_AIR_CLEAN_CRITICAL" 127 "BACKUP_AIR_CLEAN_CRITICAL" 126 "RIGHT_REPEATER_AIR_CLEAN_CRITICAL" 125 "LEFT_REPEATER_AIR_CLEAN_CRITICAL" 124 "FASCIA_FLUID_CLEAN_DEGRADED" 123 "BACKUP_FLUID_CLEAN_DEGRADED" 122 "RIGHT_REPEATER_FLUID_CLEAN_DEGRADED" 121 "LEFT_REPEATER_FLUID_CLEAN_DEGRADED" 120 "FASCIA_AIR_CLEAN_DEGRADED" 119 "BACKUP_AIR_CLEAN_DEGRADED" 118 "RIGHT_REPEATER_AIR_CLEAN_DEGRADED" 117 "LEFT_REPEATER_AIR_CLEAN_DEGRADED" 116 "TERTIARY_WASHER_FLUID_LOW" 115 "SECONDARY_WASHER_FLUID_LOW" 114 "WASHER_FLUID_LOW" 113 "ELEVATED_TIRE_PRESSURE_READING" 112 "LOW_TIRE_PRESSURE_READING" 111 "VISION_CABIN_OCCUPANCY_UNAVAILABLE" 110 "SGK_AUTOSTEER_MONITOR_ACTIVE" 109 "SGK_PLANNER_ACTIVE_D_R_N" 108 "FLEET_MAINTENANCE_EXPIRING_SOON" 107 "FLEET_MAINTENANCE_REQUIRED" 106 "CHARGE_CABLE_CONNECTED_OR_STATUS_UNKNOWN" 105 "PASSENGER_UNBUCKLED_ACTIVE_RIDE" 104 "PASSENGER_UNBUCKLED" 103 "SYSTEM_UNHEALTHY_DEV_OVERRIDE" 102 "SINGLE_SOC_HEALTHY_EXCEPTION" 101 "IMU_REPLICATION_NOT_READY" 100 "STATE_MACHINE_DISABLED" 99 "INCOMPATIBLE_SYSTEM_HEALTH" 98 "CABIN_CAM_BLINDED" 97 "RIDESHARE_INGRESS_NO_NAV_ROUTE" 96 "PASSENGER_EXPECTED" 95 "DRIVER_MONITOR_STRIKEOUT" 94 "DRIVER_NOT_PRESENT" 93 "CONTROLLER_SOLVER_CRITICAL" 92 "CONTROLLER_SOLVER_DEGRADED" 91 "CONTROLLER_DEGRADED_PEDAL_OVERRIDE" 90 "CONTROLLER_SOLVER_FAILURE" 89 "LV_CRITICAL_STATE" 88 "LV_DEGRADED_STATE" 87 "VEHICLE_AUTONOMY_BEHAVIOR_MISMATCH" 86 "CRUISE_STACK_MISMATCH" 85 "EPB_REDUNDANT_BRAKING_STATUS" 84 "EXTENDED_COMPUTE_INACTIVE_OTHER" 83 "EXTENDED_COMPUTE_TIME_SYNC_CRITICAL_DEGRADED" 82 "EXTENDED_COMPUTE_OTHER_SOC_STATE_UNKNOWN" 81 "EXTENDED_COMPUTE_OTHER_SOC_STATE_INACTIVE" 80 "EXTENDED_COMPUTE_PCIE_LINK_HEALTH" 79 "EXTENDED_COMPUTE_ETHERNET_LINK_HEALTH" 78 "EXTENDED_COMPUTE_OTHER_SOC_HEALTH_CRITICAL" 77 "EXTENDED_COMPUTE_OTHER_SOC_HEALTH_UNKNOWN" 76 "EXTENDED_COMPUTE_SOC_HEALTH_CRITICAL" 75 "EXTENDED_COMPUTE_SOC_HEALTH_UNKNOWN" 74 "FSD_FROM_PARK_DISABLED" 73 "NOT_IN_PARK_NO_TAKEOVER" 72 "NO_FIXED_ROUTE" 71 "NAV_GOAL_INVALID" 70 "ANY_EPAS_FAULT" 69 "EPAS_SYSTEM_TORQUE_REDUCED" 68 "EPAS_SECONDARY_MASTER" 67 "EPAS_REDUNDANCY_LOST" 66 "EPAS_DRIVERLESS_MODE_NOT_ACTIVE" 65 "EPAS_EAC_NOT_ACTIVE" 64 "EPAS_EAC_UNAVAILABLE" 63 "STEERING_ANGLE_INVALID" 62 "CRUISE_FAULT" 61 "CRUISE_NOT_ACTIVE_OTHER" 60 "CRUISE_NOT_ACTIVE_ESTOP" 59 "CRUISE_UNAVAILABLE_OTHER" 58 "CRUISE_UNAVAILABLE_BRAKE_APPLIED" 57 "NOT_POWER_STATE_DRIVE" 56 "FRUNK_OPEN" 55 "TRUNK_OPEN" 54 "PASSENGER_DOOR_OPEN" 53 "DRIVER_DOOR_OPEN" 52 "VISION_FPS_LOW_CAMERA_DROPS" 51 "VISION_LATENCY_HIGH" 50 "SAFETY_DRIVER_UNBUCKLED" 49 "FASCIA_VISION_OCCLUSION_AT_STOP" 48 "SEVERE_RIGHT_VISION_OCCLUSION_REVERSE" 47 "SEVERE_LEFT_VISION_OCCLUSION_REVERSE" 46 "SEVERE_BACKUP_VISION_OCCLUSION_REVERSE" 45 "SEVERE_RIGHT_VISION_OCCLUSION_MANEUVER" 44 "SEVERE_LEFT_VISION_OCCLUSION_MANEUVER" 43 "SEVERE_RIGHT_VISION_OCCLUSION" 42 "SEVERE_LEFT_VISION_OCCLUSION" 41 "SEVERE_MULTIPLE_FRONT_VISION_OCCLUSION" 40 "SEVERE_SINGLE_FRONT_VISION_OCCLUSION" 39 "CAMERA_HEALTH_METRICS_UNHEALTHY" 38 "VISION_SCENETAGS_UNHEALTHY" 37 "VISION_AUTOWIPER_UNHEALTHY" 36 "VISION_AUTOHIGHBEAM_UNHEALTHY" 35 "VISION_FAILSAFES_UNHEALTHY" 34 "RIGHT_VISION_FAILSAFE_PARKED" 33 "LEFT_VISION_FAILSAFE_PARKED" 32 "FRONT_VISION_FAILSAFE_PARKED" 31 "REAR_VISION_FAILSAFE_PARKED" 30 "CAMERA_OFFGASSING" 29 "CAMERA_OFFGASSING_PRE_ALERT" 28 "INTERMITTENT_FRAME_DROPS" 27 "CAMERA_AUTOEXPOSURE_LOST" 26 "OUT_OF_SYNC_CAMERA_STREAMS" 25 "FASCIA_CAMERA_STREAM_LOST" 24 "BACKUP_CAMERA_STREAM_LOST" 23 "RIGHT_CAMERAS_STREAM_LOST" 22 "LEFT_CAMERAS_STREAM_LOST" 21 "FRONT_CAMERAS_STREAM_LOST" 20 "CAMERA_MCU_FW_MISMATCH" 19 "FACTORY_CALIBRATION" 18 "CAMERA_PITCH_OUT_OF_BOUNDS" 17 "CAMERA_CALIBRATION" 16 "GNSS_DEGRADED_SIGNAL_STRENGTH" 15 "AP_POWER_REQUEST_NOT_NOMINAL" 14 "SENTRY_ACTIVE" 13 "NO_REDUNDANT_BRAKING" 12 "HK_RESTRICTED" 11 "OUTSIDE_GEOFENCE" 10 "RUN_MODE_NOT_FSD" 9 "AEB_ACTIVE" 8 "SUMMON_ACTIVE" 7 "AUTOPARK_ACTIVE" 6 "FSD_DISABLED" 5 "CAR_WASH_MODE" 4 "DELIVERED" 3 "NO_AUTONOMY_MODE_ACTIVE" 2 "NEUTRAL_GEAR" 1 "NONE" 0 "UNKNOWN" ;
VAL_ 583 DAS_roadEstimator 3 "ROAD_ESTIMATOR_CRITICAL" 2 "ROAD_ESTIMATOR_DEGRADED" 1 "ROAD_ESTIMATOR_UNSTABLE_MEASUREMENTS" 0 "ROAD_ESTIMATOR_HEALTHY" ;
VAL_ 583 DAS_arbiterBehavior 4 "ARBITER_CITY_STREETS" 3 "ARBITER_LANE_CHANGE_RIGHT" 2 "ARBITER_LANE_CHANGE_LEFT" 1 "ARBITER_IN_LANE" 0 "ARBITER_INVALID" ;
VAL_ 583 DAS_mapAvailability 1 "APM_MAP_AVAILABLE" 0 "APM_MAP_NOT_AVAILABLE" ;
VAL_ 583 DAS_controllerRef 6 "CONTROLLER_REFERENCE_INDETERMINATE" 5 "CONTROLLER_REFERENCE_REF_TOO_SHORT" 4 "CONTROLLER_REFERENCE_BAD_REF_UPDATE" 3 "CONTROLLER_REFERENCE_STALE_LOCALIZATION" 2 "CONTROLLER_REFERENCE_STALE_REFERENCE" 1 "CONTROLLER_REFERENCE_UNHEALTHY" 0 "CONTROLLER_REFERENCE_HEALTHY" ;
VAL_ 583 DAS_alcInternalState 12 "ALC_RETRY" 11 "ALC_SOFT_ABORTING_RIGHT" 10 "ALC_SOFT_ABORTING_LEFT" 9 "ALC_ACTIVE_ACC_RIGHT" 8 "ALC_ACTIVE_ACC_LEFT" 7 "ALC_ACTIVE_RIGHT" 6 "ALC_ACTIVE_LEFT" 5 "ALC_PRE_ACTIVE_RIGHT" 4 "ALC_PRE_ACTIVE_LEFT" 3 "ALC_BEHAVIOR_CHECK" 2 "ALC_ABORTING" 1 "ALC_IDLE" 0 "ALC_DISABLED" ;
VAL_ 583 DAS_behaviorReport 71 "BEHAVIOR_MAX_SPEED_IN_REVERSE" 70 "BEHAVIOR_STOPPING_FOR_GEAR_CHANGE" 69 "BEHAVIOR_ROAD_SPEED" 68 "BEHAVIOR_CAMERA_FAILSAFES" 67 "BEHAVIOR_CAUTION_LIGHTS" 66 "BEHAVIOR_DRY_STEERING" 65 "BEHAVIOR_CREEP_FOR_SHORT_REF" 64 "BEHAVIOR_FAILED_LANE_CHANGE" 63 "BEHAVIOR_AHB_MANUAL_OVERRIDE" 62 "BEHAVIOR_FORWARD_LATERAL_OBJECT" 61 "BEHAVIOR_POOR_VISIBILITY" 60 "BEHAVIOR_MAIN_CAMERA_SUN_GLARE" 59 "BEHAVIOR_CITY_MERGE_OBJECT" 58 "BEHAVIOR_TRAJECTORY_OUTLIER_PRESSURE" 57 "BEHAVIOR_REFERENCE_LENGTH" 56 "BEHAVIOR_PATH_BLOCKED_BEYOND_TRAJ" 55 "BEHAVIOR_PATH_BLOCKED" 54 "BEHAVIOR_UNSUPPORTED_MANEUVER" 53 "BEHAVIOR_CROSSING_OBJECT" 52 "BEHAVIOR_CLEAR_TO_GO" 51 "BEHAVIOR_APPROACHING_TURN" 50 "BEHAVIOR_DYNAMIC_PINCH_POINT" 49 "BEHAVIOR_VANISHING_CIPV_KEEP_CALM" 48 "BEHAVIOR_ONRAMP_BOOST" 47 "BEHAVIOR_TRAFFIC_CONTROL_LAUNCH" 46 "BEHAVIOR_NARROW_CORRIDOR" 45 "BEHAVIOR_SPEED_BUMP" 44 "BEHAVIOR_SUGGESTED_VISION_SPEED" 43 "BEHAVIOR_ROUNDABOUT" 42 "BEHAVIOR_TOLLBOOTH" 41 "BEHAVIOR_CROSS_TRAFFIC_AVOIDANCE" 40 "BEHAVIOR_CROSSWALK" 39 "BEHAVIOR_RELEVANT_VRU" 38 "BEHAVIOR_RISK_MANAGER" 37 "BEHAVIOR_STATIC_OBJECT_MERGE_RIGHT" 36 "BEHAVIOR_STATIC_OBJECT_MERGE_LEFT" 35 "BEHAVIOR_CUTIN_VEHICLE" 34 "BEHAVIOR_STATIC_OBJECT" 33 "BEHAVIOR_LANE_SPEED_DIFF" 32 "BEHAVIOR_END_OF_NAV_ROUTE" 31 "BEHAVIOR_STEERING_SATURATED" 30 "BEHAVIOR_ACTIVE_SAFETY_SLOWDOWN" 29 "BEHAVIOR_MP_AP_INACTIVE" 28 "BEHAVIOR_MP_ULC" 27 "BEHAVIOR_MP_DI_CRUISE" 26 "BEHAVIOR_MP_AP_STATE_MACHINE" 25 "BEHAVIOR_MP_DRIVER_MONITOR" 24 "BEHAVIOR_MP_NOT_BUCKLED" 23 "BEHAVIOR_MP_AP_RESTRICTION" 22 "BEHAVIOR_CUTIN_VEHICLE_RIGHT" 21 "BEHAVIOR_CUTIN_VEHICLE_LEFT" 20 "BEHAVIOR_MERGE_VEHICLE_RIGHT" 19 "BEHAVIOR_MERGE_VEHICLE_LEFT" 18 "BEHAVIOR_NAV_PATH_CSA" 17 "BEHAVIOR_NAV_FLEET_SPEEDS" 16 "BEHAVIOR_VISION_SPEEDS" 15 "BEHAVIOR_SLOWING_FOR_TARGET_LANE" 14 "BEHAVIOR_DRIVABLE_SPACE_VIOLATION" 13 "BEHAVIOR_MAP_LANE_GEOMETRY" 12 "BEHAVIOR_VISION_LANE_GEOMETRY" 11 "BEHAVIOR_TRAFFIC_CONTROL" 10 "BEHAVIOR_UNDERTAKE_VEHICLE" 9 "BEHAVIOR_TARGET_LANE_VEHICLE" 8 "BEHAVIOR_IN_LANE_VEHICLE" 7 "BEHAVIOR_UNDERTAKE_ASSIST_KEEP_CALM" 6 "BEHAVIOR_TRAFFIC_CONTROL_STOPPED_STATE" 5 "BEHAVIOR_FLEET_SPEEDS" 4 "BEHAVIOR_KEEP_CALM" 3 "BEHAVIOR_RADAR_ONLY_BRAKING" 2 "BEHAVIOR_CURVE_SPEED_ADAPTATION" 1 "BEHAVIOR_VIEW_RANGE" ;
VAL_ 583 DAS_controllerHealth 3 "CONTROLLER_SOLVER_FAILURE" 2 "CONTROLLER_CRITICAL" 1 "CONTROLLER_DEGRADED" 0 "CONTROLLER_HEALTHY" ;
VAL_ 583 DAS_autopilotAbortReason 255 "ABORT_REASON_MAX" 80 "ABORT_DRIVER_SEAT_TRAVEL" 79 "ABORT_DRIVER_OCCLUDED_DISTRACTED" 78 "ABORT_DRIVER_REACHING_DISTRACTED" 77 "ABORT_LOW_CABIN_ILLUMINANCE" 76 "ABORT_CABIN_CAM_OCCLUSION_DNP" 75 "ABORT_DRIVER_OCCLUDED" 74 "ABORT_DRIVER_NOT_DETECTED_SELFIE" 73 "ABORT_DRIVER_E2E_UNKNOWN" 72 "ABORT_DRIVER_EMPTY_SEAT" 71 "ABORT_DRIVER_SEAT_RECLINED" 70 "ABORT_FSD_REGION_NOT_ALLOWED" 69 "ABORT_FERRY_CROSSING" 68 "ABORT_DOOR_OPEN" 67 "ABORT_FRUNK_OPEN" 66 "ABORT_TRUNK_OPEN" 65 "ABORT_CABIN_CAM_ISSUE" 64 "ABORT_TASK_FLOW_TRACE_TIMEOUT" 63 "ABORT_SEALED_MERGE_CROSSING" 62 "ABORT_FSD_GEOFENCE_DISABLED" 61 "ABORT_EXTENDED_COMPUTE_INACTIVE_PCIE_LINK_HEALTH" 60 "ABORT_EXTENDED_COMPUTE_INACTIVE_ETHERNET_LINK_HEALTH" 59 "ABORT_EXTENDED_COMPUTE_INACTIVE_OTHER_SOC_HEALTH_CRITICAL" 58 "ABORT_EXTENDED_COMPUTE_INACTIVE_OTHER_SOC_HEALTH_UNKNOWN" 57 "ABORT_CABIN_CAM_BLIND" 56 "ABORT_AHB_MANUAL_OVERRIDE" 55 "ABORT_DRIVER_NOT_PRESENT" 54 "ABORT_PERCEPTION_HEALTH_STALE" 53 "ABORT_PERCEPTION_HEALTH_POST_PROCESSING" 52 "ABORT_EXTENDED_COMPUTE_INACTIVE" 51 "ABORT_CITY_STREETS_REF_TOO_SHORT" 50 "ABORT_INVALID_BEHAVIOR" 49 "ABORT_ONCOMING_LANE" 48 "ABORT_HEADLIGHT_OFF_AT_NIGHT" 47 "ABORT_IBOOSTER_MIA" 46 "ABORT_INTEGRATOR_HEALTH_CRITICAL" 45 "ABORT_USER_OVERRIDE_STRIKEOUT" 44 "ABORT_SEATBELT_UNBUCKLED" 43 "ABORT_PERCEPTION_HEALTH_VISION" 42 "ABORT_INVALID_VEHICLE_SPEED" 41 "ABORT_INVALID_DI_PEDAL_POS" 40 "ABORT_W048_FEATURES_DISABLED" 39 "ABORT_EPAS_STEERING_ANGLE_INVALID" 38 "ABORT_STEERING_SATURATED_LANE_DEPARTURE" 37 "ABORT_REACHED_END_OF_NAV_STOP" 36 "ABORT_GORE_INCURSION" 35 "ABORT_MISSION_PLANNER_NO_VISION_LANES_FOUND" 34 "ABORT_CONTROLLER_REF_TOO_SHORT" 33 "ABORT_AEB" 32 "ABORT_CONTROLLER_BAD_REF_UPDATE" 31 "ABORT_CONTROLLER_STALE_LOCALIZATION" 30 "ABORT_CONTROLLER_STALE_REFERENCE" 29 "ABORT_MAP_HEALTH" 28 "ABORT_THERMAL_ISSUE" 27 "ABORT_CONTROLLER_NOT_ALLOWED" 26 "ABORT_CONTROLLER_SOLVER" 25 "ABORT_CONTROLLER_REFERENCE" 24 "ABORT_ROAD_ESTIMATOR_HEALTH" 23 "ABORT_ACC_FAULT" 22 "ABORT_ACC_CANCEL_SILENT" 21 "ABORT_ACC_CANCEL_GENERIC" 20 "ABORT_RADAR_FAULT" 19 "ABORT_RADAR_BLIND" 18 "ABORT_CAMERA_CALIBRATION" 17 "ABORT_CAMERA_FAILSAFES" 16 "ABORT_EPAS_EAC_ERROR" 15 "ABORT_EPAS_EAC_NOT_ACTIVE" 14 "ABORT_VEHICLE_SPEED_ABOVE_MAX" 13 "ABORT_TRAILER_MODE_ACTIVE" 12 "ABORT_USER_DISABLED" 11 "ABORT_CRUISE_NOT_ACTIVE" 10 "ABORT_CRUISE_FAULT" 9 "ABORT_VCRIGHT_MIA" 8 "ABORT_VCFRONT_MIA" 7 "ABORT_RADAR_MIA" 6 "ABORT_SCCM_MIA" 5 "ABORT_GTW_MIA" 4 "ABORT_EPAS_MIA" 3 "ABORT_ESP_MIA" 2 "ABORT_DI_MIA" 1 "ABORT_WATCHDOG_HEALTH" 0 "ABORT_NONE" ;
VAL_ 583 DAS_rqstedBehaviorStatus 22 "RQST_BEHAVIOR_INVALID_PLAN" 21 "RQST_BEHAVIOR_BLOCKED_BY_SLOW_TARGET_R" 20 "RQST_BEHAVIOR_BLOCKED_BY_SLOW_TARGET_L" 19 "RQST_BEHAVIOR_BAD_ORIGIN_UPDATE" 18 "RQST_BEHAVIOR_OUT_OF_DATE" 17 "RQST_BEHAVIOR_ROAD_NOT_APPROPRIATE" 16 "RQST_BEHAVIOR_BLOCKED_BY_LANE_TYPE_R" 15 "RQST_BEHAVIOR_BLOCKED_BY_ULTRASOUND_AND_CAMERA_R" 14 "RQST_BEHAVIOR_BLOCKED_BY_BLINDSPOT_CAMERA_INVALID_R" 13 "RQST_BEHAVIOR_BLOCKED_BY_BLINDSPOT_CAMERA_R" 12 "RQST_BEHAVIOR_BLOCKED_BY_ULTRASOUND_R" 11 "RQST_BEHAVIOR_BLOCKED_BY_LANE_TYPE_L" 10 "RQST_BEHAVIOR_BLOCKED_BY_ULTRASOUND_AND_CAMERA_L" 9 "RQST_BEHAVIOR_BLOCKED_BY_BLINDSPOT_CAMERA_INVALID_L" 8 "RQST_BEHAVIOR_BLOCKED_BY_BLINDSPOT_CAMERA_L" 7 "RQST_BEHAVIOR_BLOCKED_BY_ULTRASOUND_L" 6 "RQST_BEHAVIOR_BUILD_ARGUMENT_FAIL" 5 "RQST_BEHAVIOR_NO_TARGET_LANE_ON_MAP" 4 "RQST_BEHAVIOR_NO_SOURCE_LANE_ON_MAP" 3 "RQST_BEHAVIOR_MAP_NOT_INITIALIZED" 2 "RQST_BEHAVIOR_NO_DEST_POLYLANE" 1 "RQST_BEHAVIOR_NO_SRC_POLYLANE" 0 "RQST_BEHAVIOR_VALID" ;
VAL_ 583 DAS_forkState 29 "FORK_AWAITING_CONFIRMATION_RIGHT" 28 "FORK_AWAITING_CONFIRMATION_LEFT" 27 "FORK_UNAVAILABLE_INTERSECTION_ACTIVE" 26 "FORK_PRE_ACTIVE_RIGHT_NAV" 25 "FORK_PRE_ACTIVE_LEFT_NAV" 24 "FORK_UNAVAILABLE_WEATHER" 23 "FORK_UNAVAILABLE_TIGHT_TURN_RADIUS" 22 "FORK_ABORT_OTHER" 21 "FORK_ABORT_DISALLOW" 20 "FORK_ABORT_NOT_RIGHT_LANE" 19 "FORK_ABORT_NOT_LEFT_LANE" 18 "FORK_ABORT_BLINKER_CHANGE" 17 "FORK_ABORT_CONTROL_INACTIVE" 16 "FORK_FORK_COMPLETE" 15 "FORK_ACTIVE_RIGHT_USER" 14 "FORK_ACTIVE_RIGHT_NAV" 13 "FORK_ACTIVE_LEFT_USER" 12 "FORK_ACTIVE_LEFT_NAV" 11 "FORK_IDLE_NO_FORKS_AVAILABLE" 10 "FORK_IDLE_RIGHT_FORK_AVAILABLE" 9 "FORK_IDLE_LEFT_FORK_AVAILABLE" 8 "FORK_IDLE_BOTH_FORKS_AVAILABLE" 7 "FORK_UNAVAILABLE_OTHER" 6 "FORK_UNAVAILABLE_TOLL_BOOTH" 5 "FORK_UNAVAILABLE_DON_INACTIVE" 4 "FORK_UNAVAILABLE_CONTROLLED_ACCESS_TOO_FAR" 3 "FORK_UNAVAILABLE_CONSTRUCTION" 2 "FORK_UNAVAILABLE_AP_INACTIVE" 1 "FORK_UNAVAILABLE_DISABLED" 0 "FORK_INVALID" ;
VAL_ 583 DAS_laneChangeState 63 "LANE_CHANGE_UNKNOWN" 43 "LANE_CHANGE_ABORTING_DESTINATION_LANE_UNSTABLE" 42 "LANE_CHANGE_UNAVAILABLE_AUTOPILOT_ABORTING" 41 "LANE_CHANGE_UNAVAILABLE_BLINKER_LATCHED" 40 "LANE_CHANGE_ABORTING_SNOOZED" 39 "LANE_CHANGE_ABORTING_SOURCE_AND_TARGET_LANES_MERGED" 38 "LANE_CHANGE_UNAVAILABLE_NO_REAR_OBJECT" 37 "LANE_CHANGE_ABORTING_NO_HANDS_ON" 36 "LANE_CHANGE_UNAVAILABLE_BLINDSPOT_RESTRICTED" 35 "LANE_CHANGE_ABORTING_WEATHER" 34 "LANE_CHANGE_ABORTING_TIGHT_TURN_RADIUS" 33 "LANE_CHANGE_ABORTING_TOLL_BOOTH_DETECTED" 32 "LANE_CHANGE_ABORTING_CONSTRUCTION_DETECTED" 31 "LANE_CHANGE_ABORTING_GORE_POINT" 30 "LANE_CHANGE_BLOCKED_RIGHT" 29 "LANE_CHANGE_BLOCKED_LEFT" 28 "LANE_CHANGE_IN_PROGRESS_RIGHT" 27 "LANE_CHANGE_IN_PROGRESS_LEFT" 26 "LANE_CHANGE_ABORTING_ALC_REQUEST_BEFORE_ULC_CONFIRM" 25 "LANE_CHANGE_ABORTING_ULC_CONFIRMATION_TIMEOUT" 24 "LANE_CHANGE_ABORTING_HIGH_ALC_PROGRESS_ERROR" 23 "LANE_CHANGE_ABORTING_BEHAVIOR_CHANGED" 22 "LANE_CHANGE_ABORTING_BELOW_MIN_SPEED" 21 "LANE_CHANGE_ABORTING_INVALID_BEHAVIOR" 20 "LANE_CHANGE_ABORTING_ULC_BLINKER_TIMEOUT" 19 "LANE_CHANGE_ABORTING_ACC_AUTOSTEER_ACTIVATED" 18 "LANE_CHANGE_ABORTING_LOST_VISION_POSE" 17 "LANE_CHANGE_ABORTING_FORK_AVAILABLE" 16 "LANE_CHANGE_ABORTING_LINE_TYPE" 15 "LANE_CHANGE_ABORTING_INVALID_MODE" 14 "LANE_CHANGE_ABORTING_BLIND_SPOT_OCCUPIED" 13 "LANE_CHANGE_ABORTING_TIMEOUT" 12 "LANE_CHANGE_ABORTING_BLINKER" 11 "LANE_CHANGE_ABORTING_INACTIVE" 10 "LANE_CHANGE_AVAILABLE_BOTH" 9 "LANE_CHANGE_AVAILABLE_RIGHT_ONLY" 8 "LANE_CHANGE_AVAILABLE_LEFT_ONLY" 7 "LANE_CHANGE_UNAVAILABLE_INVALID_MODE" 6 "LANE_CHANGE_UNAVAILABLE_ULTRASONICS_NOT_READY" 5 "LANE_CHANGE_UNAVAILABLE_FORK_MODE" 4 "LANE_CHANGE_UNAVAILABLE_INACTIVE" 3 "LANE_CHANGE_UNAVAILABLE_NO_LANES" 2 "LANE_CHANGE_UNAVAILABLE_SPEED" 1 "LANE_CHANGE_UNAVAILABLE_ROAD_NOT_APPROPRIATE" 0 "LANE_CHANGE_UNAVAILABLE_DISABLED" ;
VAL_ 583 DAS_lastWatchdogCode 136 "TRAJECTORY_RANKER_FAILED" 135 "TIME_SYNC_FAILED" 134 "GRPC_SERVER_FAILED" 133 "CONNECTIVITY_MONITOR_FAILED" 132 "COMPARATOR_FAILED" 131 "SENTRY_FAILED" 130 "UI_CAMERA_STITCH_FAILED" 129 "UI_TX_FAILED" 128 "UI_STATS_FAILED" 127 "TRIP_HISTORY_FAILED" 126 "TEXT_LOG_FAILED" 125 "AUTOPILOT_OBJECT_POSE_FAILED" 124 "RELOCALIZATION_FAILED" 123 "SLAM_MAPPING_FAILED" 122 "SLAM_BATCH_CALIB_FAILED" 121 "SLAM_BA_FAILED" 120 "SLAM_FAILED" 119 "RTDV_STREAMER_FAILED" 118 "RTDV_COMPRESSOR_FAILED" 117 "REPLAY_FAILED" 116 "REMOTE_ACCESS_FAILED" 115 "PT_TRACKER_FAILED" 114 "PERFORMANCE_COUNTER_MONITOR_FAILED" 113 "METRICS_DEV_FAILED" 112 "METRICS_API_FAILED" 111 "METRICS_FAILED" 110 "LOGGING_LOAD_GENERATOR_FAILED" 109 "LIDAR_FAILED" 108 "HTTP_SERVER_FAILED" 107 "FRAME_DECODER_FAILED" 106 "INFERENCE_ENGINE_FAILED" 105 "FACTORY_CAMERA_CALIBRATION_FAILED" 104 "DV_INSPECTOR_FAILED" 103 "DETERMINATOR_FAILED" 102 "DASH_CAM_FAILED" 101 "CLIP_REMOTE_WRITER_FAILED" 100 "COMPRESSOR_FAILED" 99 "FTRACE_SNAPSHOT_FAILED" 98 "SWITCH_MONITOR_FAILED" 97 "BLUEFIN_FAILED" 96 "BACKUP_CAMERA_FAILED" 95 "AUTONOMOUS_BEHAVIORS_FAILED" 94 "AUDIO_PROCESSOR_FAILED" 93 "CAMERA_HEALTH_FAILED" 92 "POSITIONING_ENGINE_FAILED" 91 "AUDIO_FAILED" 90 "IMU_CALIBRATION_FAILED" 89 "RADAR_EXTENDED_FAILED" 88 "TILE_PROVIDER_FAILED" 87 "RADAR_RECEIVER_FAILED" 86 "TELEMETRY_COMPLIANCE_FAILED" 85 "GEO_REGION_FAILED" 84 "FLEET_CONFIG_FAILED" 83 "X1_CLIENT_FAILED" 82 "SYNC_PIPELINE_FAILED" 81 "RADAR_FAILED" 80 "ULTRASONICS_FAILED" 79 "BEV_GRAPH_FAILED" 78 "CITY_STREETS_BEHAVIOR_FAILED" 77 "BRIDGE_FAILED" 76 "SCHEDULER_FAILED" 75 "DRIVABLE_SPACE_TRACKER_FAILED" 74 "CLIP_LOGGER_FAILED" 73 "HW_MONITOR_FAILED" 72 "PARKING_BEHAVIOR_FAILED" 71 "FIELD_CALIBRATION_FAILED" 70 "DYNAMICS_FAILED" 69 "UI_SERVER_FAILED" 68 "ACTIVE_SAFETY_FAILED" 67 "CAMERA_FAILED" 66 "MAP_MANAGER_FAILED" 65 "DRIVER_MONITOR_FAILED" 64 "MODEL_TOOLS_FAILED" 63 "LANE_CHANGE_BEHAVIOR_FAILED" 62 "UBX_LOG_FAILED" 61 "IMU_FAILED" 60 "RAIN_LIGHT_SENSING_FAILED" 59 "SNAPSHOT_TRIGGER_CLIENT_FAILED" 58 "STAY_IN_LANE_BEHAVIOR_FAILED" 57 "ATLAS_FAILED" 56 "ROAD_ESTIMATOR_FAILED" 55 "PERCEPTION_FAILED" 54 "MISSION_PLANNER_FAILED" 53 "LOCALIZER_FAILED" 52 "CONTROLLER_FAILED" 51 "AP_STATE_MACHINE_FAILED" 50 "ARBITER_FAILED" 49 "GPS_FAILED" 48 "INERTIATOR_FAILED" 47 "TEMPERATURE_MONITOR_FAILED" 46 "CAN_TX_FAILED" 45 "CAN_RX_FAILED" 44 "WATCHDOG_FAILED" 43 "LEGACY_FAILED" 42 "VISION_FAILED" 41 "SNAPSHOT_FAILED" 40 "TELEMETRY_FAILED" 39 "TELEMETRY_PACKAGER_FAILED" 30 "UNKNOWN_TASK_FAILED" 0 "NO_TASK_FAILED" ;
VAL_ 1497 DAS_carLogMultiplexer 3 "PROFILER" 2 "FCM" 1 "RADAR" 0 "FEATURE_STATE" ;
VAL_ 1497 DAS_radarTarget5_dx 0 "NO_TARGET" ;
VAL_ 1497 DAS_radarTarget1_dx 0 "NO_TARGET" ;
VAL_ 1497 DAS_radarTarget1_VxRel 0 "NO_TARGET" ;
VAL_ 1497 DAS_associated_rad_object 3 "ACC1" 2 "ACC5" 1 "OTHER" 0 "NONE" ;
VAL_ 1497 DAS_LC_handsOnReason 63 "VISUAL_DCAS_BOUNDARY_CONDITION" 62 "VISUAL_DCAS_STRICT_PHONE_USE" 61 "VISUAL_DCAS_EYES_ON_REQUEST_FAST" 60 "VISUAL_EYE_GAZE_AVERSION" 59 "VISUAL_NO_EYE_GAZE_DEVIATION" 58 "CHIME1_DCAS_STRICT_PHONE_USE" 57 "VISUAL_DCAS_EYES_ON_REQUEST" 56 "CHIME1_DCAS_EYES_ON_REQUEST_FAST" 55 "CHIME1_DCAS_EYES_ON_REQUEST" 54 "CHIME1_NO_EYE_GAZE_DEVIATION" 53 "VISUAL_ATTN_MONITORING_UNAVAILABLE" 52 "VISUAL_DRIVER_HANDS_NOT_READY" 51 "VISUAL_TIMEOUT_SUNGLASSES" 50 "CHIME1_REACHING_AFTER_AP_ACTIVATION" 49 "VISUAL_DRIVER_POSSIBLY_DISTRACTED" 48 "VISUAL_DRIVER_LOW_ATTENTION_SCORE" 47 "VISUAL_DRIVER_LOSS_OF_ATTENTION" 46 "VISUAL_VRU_FAILSAFE" 45 "VISUAL_VRU_IN_DRIVE_SPACE" 44 "CHIME1_UPCOMING_TRAFFIC_CONTROL" 43 "CHIME1_HANDS_OFF_AFTER_AP_ACTIVATION" 42 "VISUAL_UPCOMING_TRAFFIC_CONTROL" 41 "CHIME1_DISTRACTED_AFTER_AP_ACTIVATION" 40 "VISUAL_DRIVER_STATE_UNKNOWN" 39 "VISUAL_TIMEOUT_DRIVER_NOT_LIVELY" 38 "VISUAL_TIMEOUT_TORQUE_OFFSET_UNCALIBRATED" 37 "CHIME1_REFERENCE_LATERAL_ERROR" 36 "CHIME1_STREET_CAR" 35 "CHIME1_SEALED_MERGE_WARNING" 34 "CHIME1_CAUTION_LIGHTS" 33 "CHIME1_CAPTIVE_EXIT" 32 "CHIME1_CRITICAL_TRAFFIC_CONTROL" 31 "VISUAL_POOR_VISIBILITY" 30 "CHIME1_DRIVER_DISTRACTED" 29 "DEFEAT_DEVICE_DETECTED" 28 "VISUAL_TRAFFIC_CONTROLS" 27 "CHIME1_EXTREME_WEATHER" 26 "VISUAL_POOR_WEATHER" 25 "VISUAL_STOP_AND_GO" 24 "VISUAL_TIMEOUT_HOMOLOGATION" 23 "VISUAL_ULC_REQUEST" 22 "CHIME1_TOLL_BOOTH" 21 "CHIME1_STATIONARY_RADAR" 20 "CHIME1_DRIVABLE_SPACE_VIOLATION" 19 "CHIME1_RE_DEGRADED_MEASUREMENTS" 18 "CHIME1_NO_LINES" 17 "VISUAL_ALC" 16 "VISUAL_LATERAL_ACCELERATION" 15 "VISUAL_TIMEOUT_ACCELERATOR" 14 "VISUAL_TIMEOUT_RESTRICTED" 13 "VISUAL_TIMEOUT_NO_CIPV" 12 "VISUAL_TIMEOUT_CIPV" 11 "VISUAL_TIMEOUT_CUTOUT_CIPV" 10 "VISUAL_TIMEOUT_CONSTRUCTION" 9 "VISUAL_TIMEOUT_LOW_SPEED" 8 "VISUAL_TIMEOUT_MED_SPEED" 7 "VISUAL_TIMEOUT_HI_SPEED" 6 "VISUAL_TIMEOUT_LONG_TERM" 5 "VISUAL_DRIVER_NOT_PRESENT" 4 "VISUAL_FUSION_MODEL" 3 "VISUAL_FUSION_NAV" 2 "CHIME1_CONSTRUCTION" 1 "CHIME1_ANGLE_SATURATION" 0 "LC_HANDS_ON_REASON_NONE" ;
VAL_ 1497 DAS_ACC_camStatus 3 "ACC_CAM_STATUS_FAULT" 2 "ACC_CAM_STATUS_SQUINTING" 1 "ACC_CAM_STATUS_BLIND" 0 "ACC_CAM_STATUS_HEALTHY" ;
VAL_ 1497 DAS_aeb_not_activating_reason 22 "LCM_AEB_SENSORS_DO_NOT_AGREE" 21 "LCM_AEB_NOT_RADAR_CIPV" 20 "LCM_AEB_LANE_ASSIGNMENT_AGE" 19 "LCM_AEB_COLLISION_COURSE_TIME" 18 "LCM_AEB_TRACK_CONSISTENCY" 17 "LCM_AEB_DRIVABLE_SPACE" 16 "LCM_AEB_PATH_OVERLAP" 15 "LCM_AEB_RAD_NOT_ASSOCIATED" 14 "LCM_AEB_CAM_NOT_ASSOCIATED" 13 "LCM_AEB_CAMERA_CROSS_CHECK" 12 "LCM_AEB_YOUNG_TRACK" 11 "LCM_AEB_OTHER" 10 "LCM_AEB_ACTIVE" 9 "LCM_AEB_OVERRIDE" 8 "LCM_AEB_DELAYED_EVADING_DISTANCE" 7 "LCM_AEB_DELAYED_REQUIRED_ACCELERATION" 6 "LCM_AEB_CURRENT_REQUIRED_ACCELERATION" 5 "LCM_AEB_COLLISION_OVERLAP_RATIO" 4 "LCM_AEB_RELATIVE_VELOCITY" 3 "LCM_AEB_ABSOLUTE_ACCELERATION" 2 "LCM_AEB_NO_COLLISION_OBJECT" 1 "LCM_AEB_UNAVAILABLE" 0 "LCM_AEB_FAULT" ;
VAL_ 1497 DAS_handsOnDetected 2 "HANDS_ON_DETECTED" 1 "HANDS_ON_NOT_DETECTED" 0 "HANDS_ON_SNA" ;
VAL_ 1497 DAS_driveOnNavUnavailableReason 25 "DON_BLINKER_FAULTED" 24 "DON_UNAVAILABLE_AUDIO" 23 "DON_SCENE_TAG_SUN_GLARE" 22 "DON_SCENE_TAG_SEVERE_WEATHER" 21 "DON_SCENE_TAG_LENS_FLARE" 20 "DON_SCENE_TAG_FULLY_BLOCKED" 19 "DON_SCENE_TAG_FOG" 18 "DON_SCENE_TAG_BLURRY" 17 "DON_SCENE_TAG_BAD_CAMERA" 16 "DON_NAV_ROUTE_NOT_ACTIVE" 15 "DON_FEATURE_NOT_ENABLED" 14 "DON_AUTOPILOT_UNAVAILABLE" 13 "DON_INCOMPATIBLE_WAY" 12 "DON_HIGH_CURVATURE" 11 "DON_TOLLBOOTH_DETECTED" 10 "DON_CONSTRUCTION_DETECTED" 9 "DON_AUTO_WIPER_ACTIVE" 8 "DON_IMPLAUSIBLE_MAP_DATA" 7 "DON_GPS_DEGRADED" 6 "DON_ULTRASONICS_INVALID" 5 "DON_EDGE_LOCALIZATION_FAILED" 4 "DON_ROUTE_DOWNLOAD_FAILED" 3 "DON_UNAVAILABLE_CAMERA_BLOCKED" 2 "DON_CAMERA_UNAVAILABLE" 1 "DON_INVALID_NAV_GOAL" 0 "DON_UNAVAILABLE_NONE" ;
VAL_ 1497 DAS_accUnavailableReason 76 "ACC_UNAVAILABLE_REASON_SEATBELT_UNBUCKLED" 75 "ACC_UNAVAILABLE_REASON_DOOR_OPEN" 74 "ACC_UNAVAILABLE_REASON_FRUNK_OPEN" 73 "ACC_UNAVAILABLE_REASON_TRUNK_OPEN" 72 "ACC_UNAVAILABLE_REASON_OFF_ROAD_MODE_ACTIVE" 71 "ACC_UNAVAILABLE_REASON_SUPPRESS_FOR_RECENT_SCROLL_WHEEL_INTERACTION" 70 "ACC_UNAVAILABLE_REASON_SUPPRESS_FOR_RECENT_AUTOPARK_ACTIVATION" 69 "ACC_UNAVAILABLE_REASON_USER_SETTINGS_NOT_SUPPORTED" 68 "ACC_UNAVAILABLE_REASON_AUTOSTEER_INACTIVE_FOR_SINGLE_CLICK" 67 "ACC_UNAVAILABLE_REASON_AUTOSTEER_UNAVAILABLE_FOR_SINGLE_CLICK" 66 "ACC_UNAVAILABLE_REASON_TASK_FLOW_TRACE_TIMEOUT_SLAM" 65 "ACC_UNAVAILABLE_REASON_TASK_FLOW_TRACE_TIMEOUT_LOCALIZATION" 64 "ACC_UNAVAILABLE_REASON_TASK_FLOW_TRACE_TIMEOUT_STATIC_WORLD" 63 "ACC_UNAVAILABLE_REASON_TASK_FLOW_TRACE_TIMEOUT_DYNAMIC_WORLD" 62 "ACC_UNAVAILABLE_REASON_TASK_FLOW_TRACE_TIMEOUT_UNKNOWN" 61 "ACC_UNAVAILABLE_REASON_EXTENDED_COMPUTE_INACTIVE_PCIE_LINK_HEALTH" 60 "ACC_UNAVAILABLE_REASON_EXTENDED_COMPUTE_INACTIVE_ETHERNET_LINK_HEALTH" 59 "ACC_UNAVAILABLE_REASON_EXTENDED_COMPUTE_INACTIVE_OTHER_SOC_HEALTH_CRITICAL" 58 "ACC_UNAVAILABLE_REASON_EXTENDED_COMPUTE_INACTIVE_OTHER_SOC_HEALTH_UNKNOWN" 57 "ACC_UNAVAILABLE_REASON_AHB_MANUAL_OVERRIDE" 56 "ACC_UNAVAILABLE_REASON_EXTENDED_COMPUTE_INACTIVE" 55 "ACC_UNAVAILABLE_REASON_DRIVER_NOT_PRESENT" 54 "ACC_UNAVAILABLE_REASON_LOW_ODOMETRY" 53 "ACC_UNAVAILABLE_REASON_PERCEPTION_HEALTH_STALE" 52 "ACC_UNAVAILABLE_REASON_PERCEPTION_HEALTH_POST_PROCESSING" 51 "ACC_UNAVAILABLE_REASON_RECENT_USER_CANCELLATION" 50 "ACC_UNAVAILABLE_REASON_CITY_STREETS_REF_TOO_SHORT" 49 "ACC_UNAVAILABLE_REASON_INVALID_BEHAVIOR" 48 "ACC_UNAVAILABLE_REASON_RECENT_GEAR_SHIFT" 47 "ACC_UNAVAILABLE_REASON_IBOOSTER_MIA" 46 "ACC_UNAVAILABLE_INTEGRATOR_HEALTH_CRITICAL" 45 "ACC_UNAVAILABLE_REASON_UNKNOWN" 44 "ACC_UNAVAILABLE_REASON_RADAR_VERSION_MISMATCH" 43 "ACC_UNAVAILABLE_REASON_AP_NOT_CONFIGURED" 42 "ACC_UNAVAILABLE_REASON_INVALID_VEHICLE_SPEED" 41 "ACC_UNAVAILABLE_REASON_INVALID_DI_PEDAL_POS" 40 "ACC_UNAVAILABLE_REASON_W048_FEATURES_DISABLED" 39 "ACC_UNAVAILABLE_REASON_FAILED_AUTOSTEER_ACTIVATION" 38 "ACC_UNAVAILABLE_REASON_AEB_ACTIVE" 37 "ACC_UNAVAILABLE_REASON_AVAILABILITY_CHECK_HYSTERESIS" 36 "ACC_UNAVAILABLE_REASON_SONIC_OBSTACLE_DETECTED" 35 "ACC_UNAVAILABLE_REASON_TRACKED_OBSTACLE_DETECTED" 34 "ACC_UNAVAILABLE_REASON_STEERING_WHEEL_ANGLE" 33 "ACC_UNAVAILABLE_REASON_ROAD_CLASS" 32 "ACC_UNAVAILABLE_REASON_BELOW_MIN_SPEED" 31 "ACC_UNAVAILABLE_REASON_PEDESTRIAN_PRESENT_OR_NO_VEHICLE" 30 "ACC_UNAVAILABLE_REASON_BELOW_MAX_UNAVAILABLE_SPEED" 29 "ACC_UNAVAILABLE_REASON_ESP_PARTY_MIA" 28 "ACC_UNAVAILABLE_REASON_EPAS_PARTY_MIA" 27 "ACC_UNAVAILABLE_REASON_DI_PARTY_MIA" 26 "ACC_UNAVAILABLE_REASON_ECU_THERMAL_ISSUE" 25 "ACC_UNAVAILABLE_REASON_CAMERA_FAILSAFES" 24 "ACC_UNAVAILABLE_REASON_ESP_MIA" 23 "ACC_UNAVAILABLE_REASON_EPAS_MIA" 22 "ACC_UNAVAILABLE_REASON_GTW_MIA" 21 "ACC_UNAVAILABLE_REASON_DI_MIA" 20 "ACC_UNAVAILABLE_REASON_NOT_IN_DRIVE" 19 "ACC_UNAVAILABLE_REASON_CONTROLLER_INDETERMINATE" 18 "ACC_UNAVAILABLE_REASON_CONTROLLER_REFERENCE_TOO_SHORT" 17 "ACC_UNAVAILABLE_REASON_CONTROLLER_BAD_UPDATE" 16 "ACC_UNAVAILABLE_REASON_CONTROLLER_STALE_LOCALIZATION" 15 "ACC_UNAVAILABLE_REASON_CONTROLLER_STALE_REFERENCE" 14 "ACC_UNAVAILABLE_REASON_CONTROLLER_REFERENCE_UNHEALTHY" 13 "ACC_UNAVAILABLE_REASON_CONTROLLER_SOLVER_UNHEALTHY" 12 "ACC_UNAVAILABLE_REASON_CONTROLLER_NOT_ALLOWED" 11 "ACC_UNAVAILABLE_REASON_CAMERA_CALIBRATION" 10 "ACC_UNAVAILABLE_REASON_CAMERA_PITCH" 9 "ACC_UNAVAILABLE_REASON_CAMERA_BLOCKED" 8 "ACC_UNAVAILABLE_REASON_RADAR_MIA" 7 "ACC_UNAVAILABLE_REASON_RADAR_FAULT" 6 "ACC_UNAVAILABLE_REASON_RADAR_BLIND" 5 "ACC_UNAVAILABLE_REASON_PERCEPTION_HEALTH_VISION" 4 "ACC_UNAVAILABLE_REASON_PERCEPTION_HEALTH_RADAR" 3 "ACC_UNAVAILABLE_REASON_DI_CRUISE_STATE_CRITICAL" 2 "ACC_UNAVAILABLE_REASON_AUTOPARK_STATE" 1 "ACC_UNAVAILABLE_REASON_SYSTEM_HEALTH_CRITICAL" 0 "ACC_UNAVAILABLE_REASON_NONE" ;
VAL_ 1497 DAS_pmmNotActivatingReason 24 "PMM_NOT_ACTIVATING_OTHER" 23 "PMM_NOT_ACTIVATING_DI_STATUS" 22 "PMM_NOT_ACTIVATING_HARDWARE_NOT_SUPPORTED" 21 "PMM_NOT_ACTIVATING_DYNAMIC_BARRIER" 20 "PMM_NOT_ACTIVATING_TRAILER_MODE" 19 "PMM_NOT_ACTIVATING_DROPPED_CIPV" 18 "PMM_NOT_ACTIVATING_SPEED_DERIVATIVE" 17 "PMM_NOT_ACTIVATING_SCENE_TAG" 16 "PMM_NOT_ACTIVATING_MODE" 15 "PMM_NOT_ACTIVATING_SPEED_PROFILE" 14 "PMM_NOT_ACTIVATING_INSEVERE_CIPV" 13 "PMM_NOT_ACTIVATING_WHEEL_ACCELERATION" 12 "PMM_NOT_ACTIVATING_ULTRASONIC_VELOCITY" 11 "PMM_NOT_ACTIVATING_ULTRASONIC_DISTANCE" 10 "PMM_NOT_ACTIVATING_USER_DISABLED" 9 "PMM_NOT_ACTIVATING_ROAD" 8 "PMM_NOT_ACTIVATING_SDI_HEALTH" 7 "PMM_NOT_ACTIVATING_VEHICLE_SPEED" 6 "PMM_NOT_ACTIVATING_TRACK_MODE" 5 "PMM_NOT_ACTIVATING_GEAR" 4 "PMM_NOT_ACTIVATING_PEDAL_RATE" 3 "PMM_NOT_ACTIVATING_PEDAL_POS" 2 "PMM_NOT_ACTIVATING_OBSTACLE_GRID" 1 "PMM_NOT_ACTIVATING_APP_FEATURES_NOT_AVAILABLE" 0 "PMM_NOT_ACTIVATING_NONE" ;
VAL_ 1497 DAS_desiredTarget_dx 255 "SNA" ;
VAL_ 1497 DAS_radarTarget2_dx 0 "NO_TARGET" ;
VAL_ 1497 DAS_radarTarget3_dx 0 "NO_TARGET" ;
VAL_ 1497 DAS_radarTarget4_dx 0 "NO_TARGET" ;
VAL_ 1497 DAS_closestInLaneTargetDx 0 "NO_TARGET" ;
VAL_ 1497 DAS_secondInLaneTargetDx 0 "NO_TARGET" ;
VAL_ 1497 DAS_closestLeftLaneTargetDx 0 "NO_TARGET" ;
VAL_ 1497 DAS_closestRightLaneTargetDx 0 "NO_TARGET" ;
VAL_ 1497 DAS_closestInLaneTargetVxRel 0 "NO_TARGET" ;
VAL_ 970 DAS_gpsStatusMultiplexer 3 "Mux3" 2 "Mux2" 1 "Mux1" 0 "Mux0" ;
VAL_ 970 DAS_gpsTransportModeState 1 "DAS_GPS_TRANSPORT_MODE_ON" 0 "DAS_GPS_TRANSPORT_MODE_OFF" ;
VAL_ 970 DAS_gpsWheelsOffMotionDetected 1 "DAS_GPS_MOTION_DETECTED_ON" 0 "DAS_GPS_MOTION_DETECTED_OFF" ;
VAL_ 970 DAS_gpsFixTypeHardware 6 "DEAD_RECOCKONING_FIX" 5 "FLOAT_RTK_FIX" 4 "REAL_TIME_KINEMATICS_FIX" 3 "PPS_FIX" 2 "DGPS_FIX" 1 "GPS_FIX" 0 "INVALID_FIX" ;
VAL_ 970 DAS_gpsFixTypeSoftware 6 "DEAD_RECOCKONING_FIX" 5 "FLOAT_RTK_FIX" 4 "REAL_TIME_KINEMATICS_FIX" 3 "PPS_FIX" 2 "DGPS_FIX" 1 "GPS_FIX" 0 "INVALID_FIX" ;
VAL_ 970 DAS_gpsJammingState 3 "GPS_JAMMING_STATE_CRITICAL" 2 "GPS_JAMMING_STATE_WARNING" 1 "GPS_JAMMING_STATE_NOMINAL" 0 "GPS_JAMMING_STATE_UNKNOWN" ;
VAL_ 970 DAS_gpsSpoofDetectorState 3 "GPS_SPOOFING_MULTIPLE_INDICATIONS" 2 "GPS_SPOOFING_INDICATION_PRESENT" 1 "GPS_SPOOFING_NO_ACTIVE_INDICATION" 0 "GPS_SPOOFING_UNKNOWN" ;
VAL_ 970 DAS_gnssConstellationsState 2 "CONSTELLATIONS_STATE_VALID" 1 "CONSTELLATIONS_STATE_INVALID" 0 "CONSTELLATIONS_STATE_UNKNOWN" ;
VAL_ 970 DAS_gpsResetReason 13 "GPS_RESET_PPS_MISSING" 12 "GPS_RESET_SOLUTION_INCONSISTENCY" 11 "GPS_RESET_MANUAL_COLD_RESET" 10 "GPS_RESET_GNSS_CFG_CHANGE" 9 "GPS_RESET_RESUME_CONFIGURATION_FAULT" 8 "GPS_RESET_SUSPEND_CONFIGURATION_FAULT" 7 "GPS_RESET_SATELLITE_REJECTION_TIMEOUT" 6 "GPS_RESET_ENTER_TRANSPORT_MODE" 5 "GPS_RESET_EXIT_TRANSPORT_MODE" 4 "GPS_RESET_GNSS_DATA_MISSING" 3 "GPS_RESET_UBX_MISSING" 2 "GPS_RESET_DATA_CORRUPTED" 1 "GPS_RESET_DATA_MISSING" 0 "GPS_RESET_NONE" ;
VAL_ 970 DAS_gpsToMcuSource 4 "GPS_TO_MCU_SOURCE_BLUEFIN_SOLUTION" 3 "GPS_TO_MCU_SOURCE_TESLA_VIO_SOLUTION" 2 "GPS_TO_MCU_SOURCE_SOFTWARE_SOLUTION" 1 "GPS_TO_MCU_SOURCE_HARDWARE_SOLUTION" 0 "GPS_TO_MCU_SOURCE_UNKNOWN" ;
VAL_ 970 DAS_gpsSolutionSoc 2 "GPS_SOLUTION_SOC_B" 1 "GPS_SOLUTION_SOC_A" 0 "GPS_SOLUTION_SOC_UNKNOWN" ;
VAL_ 970 DAS_gpsFixTypeSoftwareSocB 6 "DEAD_RECOCKONING_FIX" 5 "FLOAT_RTK_FIX" 4 "REAL_TIME_KINEMATICS_FIX" 3 "PPS_FIX" 2 "DGPS_FIX" 1 "GPS_FIX" 0 "INVALID_FIX" ;
VAL_ 970 DAS_gnssNumSatsGps 15 "FIFTEEN_OR_MORE_SATELLITES" ;
VAL_ 970 DAS_gnssNumSatsGal 15 "FIFTEEN_OR_MORE_SATELLITES" ;
VAL_ 970 DAS_gnssNumSatsBds 15 "FIFTEEN_OR_MORE_SATELLITES" ;
VAL_ 1337 DAS_infoIndex 255 "END" 24 "EYEQ_FFS" 23 "EYEQ_APP" 20 "UDS_PROTOCOL_BOOTCRC" 19 "VERSION_DEPRECATED" 18 "BOOTLOADER_GITHASH" 17 "APP_GITHASH" 16 "EYEQ_BOOT" 15 "BOOTLOADER_CRC" 14 "BOOTLOADER_SVN" 13 "APP_CRC" 11 "PCBAID_ASSYID_USAGEID" 10 "BUILD_HWID_COMPONENTID" 9 "DEPRECATED_9" 8 "DEPRECATED_8" 7 "DEPRECATED_7" 6 "DEPRECATED_6" 5 "DEPRECATED_5" 4 "DEPRECATED_4" 3 "DEPRECATED_3" 2 "DEPRECATED_2" 1 "DEPRECATED_1" 0 "DEPRECATED_0" ;
VAL_ 1337 DAS_infoBuildType 4 "INFO_MFG_BUILD" 3 "INFO_TRACEABLE_CI_BUILD" 2 "INFO_LOCAL_BUILD" 1 "INFO_PLATFORM_BUILD" 0 "INFO_UNKNOWN_BUILD" ;
VAL_ 569 DAS_leftLineUsage 3 "BLACKLISTED" 2 "FUSED" 1 "AVAILABLE" 0 "REJECTED_UNAVAILABLE" ;
VAL_ 569 DAS_rightLineUsage 3 "BLACKLISTED" 2 "FUSED" 1 "AVAILABLE" 0 "REJECTED_UNAVAILABLE" ;
VAL_ 569 DAS_leftFork 3 "FORK_UNAVAILABLE" 2 "FORK_SELECTED" 1 "FORK_AVAILABLE" 0 "FORK_NONE" ;
VAL_ 569 DAS_rightFork 3 "FORK_UNAVAILABLE" 2 "FORK_SELECTED" 1 "FORK_AVAILABLE" 0 "FORK_NONE" ;
VAL_ 921 DAS_autopilotState 15 "SNA" 14 "FAULT" 9 "ABORTED" 8 "ABORTING" 6 "ACTIVE_FSD" 5 "ACTIVE_NAV" 4 "ACTIVE_RESTRICTED" 3 "ACTIVE_NOMINAL" 2 "AVAILABLE" 1 "UNAVAILABLE" 0 "DISABLED" ;
VAL_ 921 DAS_blindSpotRearLeft 3 "SNA" 2 "WARNING_LEVEL_2" 1 "WARNING_LEVEL_1" 0 "NO_WARNING" ;
VAL_ 921 DAS_blindSpotRearRight 3 "SNA" 2 "WARNING_LEVEL_2" 1 "WARNING_LEVEL_1" 0 "NO_WARNING" ;
VAL_ 921 DAS_fusedSpeedLimit 31 "NONE" 0 "UNKNOWN_SNA" ;
VAL_ 921 DAS_suppressSpeedWarning 1 "Suppress_Speed_Warning" 0 "Do_Not_Suppress" ;
VAL_ 921 DAS_visionOnlySpeedLimit 31 "NONE" 0 "UNKNOWN_SNA" ;
VAL_ 921 DAS_heaterState 1 "HEATER_ON" 0 "HEATER_OFF_SNA" ;
VAL_ 921 DAS_forwardCollisionWarning 3 "SNA" 1 "FORWARD_COLLISION_WARNING" 0 "NONE" ;
VAL_ 921 DAS_autoparkReady 1 "AUTOPARK_READY" 0 "AUTOPARK_UNAVAILABLE" ;
VAL_ 921 DAS_lssState 7 "LSS_STATE_OFF" 6 "LSS_STATE_ABORT" 5 "LSS_STATE_BLINDSPOT" 4 "LSS_STATE_MONITOR" 3 "LSS_STATE_ELK" 2 "LSS_STATE_LKA" 1 "LSS_STATE_LDW" 0 "LSS_STATE_FAULT" ;
VAL_ 921 DAS_sideCollisionAvoid 3 "SNA" 2 "AVOID_RIGHT" 1 "AVOID_LEFT" 0 "NONE" ;
VAL_ 921 DAS_sideCollisionWarning 3 "WARN_LEFT_RIGHT" 2 "WARN_RIGHT" 1 "WARN_LEFT" 0 "NONE" ;
VAL_ 921 DAS_sideCollisionInhibit 1 "INHIBIT" 0 "NO_INHIBIT" ;
VAL_ 921 DAS_laneDepartureWarning 5 "SNA" 4 "RIGHT_WARNING_SEVERE" 3 "LEFT_WARNING_SEVERE" 2 "RIGHT_WARNING" 1 "LEFT_WARNING" 0 "NONE" ;
VAL_ 921 DAS_fleetSpeedState 3 "FLEETSPEED_HOLD" 2 "FLEETSPEED_ACTIVE" 1 "FLEETSPEED_AVAILABLE" 0 "FLEETSPEED_UNAVAILABLE" ;
VAL_ 921 DAS_autopilotHandsOnState 15 "LC_HANDS_ON_SNA" 10 "LC_HANDS_ON_REQD_ESCALATED_CHIME_2" 9 "LC_HANDS_ON_REQD_ESCALATED_CHIME_1" 8 "LC_HANDS_ON_SUSPENDED" 7 "LC_HANDS_ON_REQD_STRUCK_OUT" 6 "LC_HANDS_ON_REQD_SLOWING" 5 "LC_HANDS_ON_REQD_CHIME_2" 4 "LC_HANDS_ON_REQD_CHIME_1" 3 "LC_HANDS_ON_REQD_VISUAL" 2 "LC_HANDS_ON_REQD_NOT_DETECTED" 1 "LC_HANDS_ON_REQD_DETECTED" 0 "LC_HANDS_ON_NOT_REQD" ;
VAL_ 921 DAS_autoLaneChangeState 31 "ALC_SNA" 30 "ALC_ABORT_MISSION_PLAN_INVALID" 29 "ALC_ABORT_TIMEOUT" 28 "ALC_WAITING_HANDS_ON" 27 "ALC_BLOCKED_LANE_TYPE_R" 26 "ALC_BLOCKED_LANE_TYPE_L" 25 "ALC_BLOCKED_VEH_TTC_AND_USS_R" 24 "ALC_BLOCKED_VEH_TTC_R" 23 "ALC_BLOCKED_VEH_TTC_AND_USS_L" 22 "ALC_BLOCKED_VEH_TTC_L" 21 "ALC_UNAVAILABLE_SOLID_LANE_LINE" 20 "ALC_ABORT_OTHER_REASON" 19 "ALC_ABORT_BLINKER_TURNED_OFF" 18 "ALC_ABORT_LC_HEALTH_BAD" 17 "ALC_ABORT_POOR_VIEW_RANGE" 16 "ALC_ABORT_SIDE_OBSTACLE_PRESENT_R" 15 "ALC_ABORT_SIDE_OBSTACLE_PRESENT_L" 14 "ALC_WAITING_FOR_FWD_OBST_TO_PASS_R" 13 "ALC_WAITING_FOR_FWD_OBST_TO_PASS_L" 12 "ALC_WAITING_FOR_SIDE_OBST_TO_PASS_R" 11 "ALC_WAITING_FOR_SIDE_OBST_TO_PASS_L" 10 "ALC_IN_PROGRESS_R" 9 "ALC_IN_PROGRESS_L" 8 "ALC_AVAILABLE_BOTH" 7 "ALC_AVAILABLE_ONLY_R" 6 "ALC_AVAILABLE_ONLY_L" 5 "ALC_UNAVAILABLE_VEHICLE_SPEED" 4 "ALC_UNAVAILABLE_EXITING_HIGHWAY" 3 "ALC_UNAVAILABLE_TP_FOLLOW" 2 "ALC_UNAVAILABLE_SONICS_INVALID" 1 "ALC_UNAVAILABLE_NO_LANES" 0 "ALC_UNAVAILABLE_DISABLED" ;
VAL_ 905 DAS_accSpeedLimit 511 "SNA" 0 "NONE" ;
VAL_ 905 DAS_pmmObstacleSeverity 7 "PMM_SNA" 6 "PMM_ACCEL_LIMIT" 5 "PMM_CRASH_FRONT" 4 "PMM_CRASH_REAR" 3 "PMM_BRAKE_REQUEST" 2 "PMM_IMMINENT_FRONT" 1 "PMM_IMMINENT_REAR" 0 "PMM_NONE" ;
VAL_ 905 DAS_pmmLoggingRequest 1 "TRUE" 0 "FALSE" ;
VAL_ 905 DAS_activationFailureStatus 2 "LC_ACTIVATION_FAILED_2" 1 "LC_ACTIVATION_FAILED_1" 0 "LC_ACTIVATION_IDLE" ;
VAL_ 905 DAS_pmmUltrasonicsFaultReason 4 "PMM_ULTRASONICS_INVALID_MIA" 3 "PMM_ULTRASONICS_BLOCKED_BOTH" 2 "PMM_ULTRASONICS_BLOCKED_REAR" 1 "PMM_ULTRASONICS_BLOCKED_FRONT" 0 "PMM_ULTRASONICS_NO_FAULT" ;
VAL_ 905 DAS_pmmRadarFaultReason 2 "PMM_RADAR_INVALID_MIA" 1 "PMM_RADAR_BLOCKED_FRONT" 0 "PMM_RADAR_NO_FAULT" ;
VAL_ 905 DAS_pmmSysFaultReason 7 "PMM_FAULT_BRAKE_PEDAL_INHIBIT" 6 "PMM_FAULT_ROAD_TYPE" 5 "PMM_FAULT_DISABLED_BY_USER" 4 "PMM_FAULT_STEERING_ANGLE_RATE" 3 "PMM_FAULT_DI_FAULT" 2 "PMM_FAULT_SPEED" 1 "PMM_FAULT_DAS_DISABLED" 0 "PMM_FAULT_NONE" ;
VAL_ 905 DAS_pmmCameraFaultReason 2 "PMM_CAMERA_INVALID_MIA" 1 "PMM_CAMERA_BLOCKED_FRONT" 0 "PMM_CAMERA_NO_FAULT" ;
VAL_ 905 DAS_ACC_report 24 "ACC_REPORT_BEHAVIOR_REPORT" 23 "ACC_REPORT_CAMERA_ONLY" 22 "ACC_REPORT_RADAR_OBJ_FIVE" 21 "ACC_REPORT_CIPV_CUTTING_OUT" 20 "ACC_REPORT_MCVLR_IN_PATH" 19 "ACC_REPORT_MCVLR_DPP" 18 "ACC_REPORT_FLEET_SPEEDS" 17 "ACC_REPORT_TARGET_MCP" 16 "ACC_REPORT_RADAR_OBJ_TWO" 15 "ACC_REPORT_RADAR_OBJ_ONE" 14 "ACC_REPORT_LC_EXTERNAL_STATE_ACTIVE_RESTRICTED" 13 "ACC_REPORT_LC_EXTERNAL_STATE_ABORTED" 12 "ACC_REPORT_LC_EXTERNAL_STATE_ABORTING" 11 "ACC_REPORT_LC_HANDS_ON_REQD_STRUCK_OUT" 10 "ACC_REPORT_CSA" 9 "ACC_REPORT_TARGET_TYPE_FAULT" 8 "ACC_REPORT_TARGET_TYPE_IPSO" 7 "ACC_REPORT_TARGET_TYPE_TRAFFIC_LIGHT" 6 "ACC_REPORT_TARGET_TYPE_STOP_SIGN" 5 "ACC_REPORT_TARGET_CUTIN" 4 "ACC_REPORT_TARGET_MCVR" 3 "ACC_REPORT_TARGET_MCVL" 2 "ACC_REPORT_TARGET_IN_FRONT_OF_CIPV" 1 "ACC_REPORT_TARGET_CIPV" 0 "ACC_REPORT_TARGET_NONE" ;
VAL_ 905 DAS_csaState 3 "CSA_EXTERNAL_STATE_HOLD" 2 "CSA_EXTERNAL_STATE_ENABLE" 1 "CSA_EXTERNAL_STATE_AVAILABLE" 0 "CSA_EXTERNAL_STATE_UNAVAILABLE" ;
VAL_ 905 DAS_radarTelemetry 2 "RADAR_TELEMETRY_URGENT" 1 "RADAR_TELEMETRY_NORMAL" 0 "RADAR_TELEMETRY_IDLE" ;
VAL_ 905 DAS_robState 3 "ROB_STATE_MAPLESS" 2 "ROB_STATE_ACTIVE" 1 "ROB_STATE_MEASURE" 0 "ROB_STATE_INHIBITED" ;
VAL_ 905 DAS_driverInteractionLevel 2 "CONTINUED_DRIVER_NOT_INTERACTING" 1 "DRIVER_NOT_INTERACTING" 0 "DRIVER_INTERACTING" ;
VAL_ 905 DAS_ppOffsetDesiredRamp 128 "PP_NO_OFFSET" ;
VAL_ 905 DAS_longCollisionWarning 15 "FCM_LONG_COLLISION_WARNING_SNA" 12 "FCM_LONG_COLLISION_WARNING_VEHICLE_CIPV2" 11 "FCM_LONG_COLLISION_WARNING_VEHICLE_MCVR2" 10 "FCM_LONG_COLLISION_WARNING_VEHICLE_MCVR" 9 "FCM_LONG_COLLISION_WARNING_VEHICLE_MCVL2" 8 "FCM_LONG_COLLISION_WARNING_VEHICLE_MCVL" 7 "FCM_LONG_COLLISION_WARNING_VEHICLE_CUTIN" 6 "FCM_LONG_COLLISION_WARNING_VEHICLE_CIPV" 5 "FCM_LONG_COLLISION_WARNING_TFL_STOPLINE" 4 "FCM_LONG_COLLISION_WARNING_STOPSIGN_STOPLINE" 3 "FCM_LONG_COLLISION_WARNING_IPSO" 2 "FCM_LONG_COLLISION_WARNING_PEDESTRIAN" 1 "FCM_LONG_COLLISION_WARNING_VEHICLE_UNKNOWN" 0 "FCM_LONG_COLLISION_WARNING_NONE" ;
VAL_ 586 DAS_autosteerVehiclesUsage 3 "BLACKLISTED" 2 "FUSED" 1 "AVAILABLE" 0 "REJECTED_UNAVAILABLE" ;
VAL_ 586 DAS_autosteerHPPUsage 3 "BLACKLISTED" 2 "FUSED" 1 "AVAILABLE" 0 "REJECTED_UNAVAILABLE" ;
VAL_ 586 DAS_autosteerNavigationUsage 3 "BLACKLISTED" 2 "FUSED" 1 "AVAILABLE" 0 "REJECTED_UNAVAILABLE" ;
VAL_ 586 DAS_autosteerModelUsage 3 "BLACKLISTED" 2 "FUSED" 1 "AVAILABLE" 0 "REJECTED_UNAVAILABLE" ;
VAL_ 586 DAS_autosteerBottsDotsUsage 3 "BLACKLISTED" 2 "FUSED" 1 "AVAILABLE" 0 "REJECTED_UNAVAILABLE" ;
VAL_ 586 DAS_offsetSide 3 "OFFSET_BOTH_OBJECTS" 2 "OFFSET_LEFT_OBJECT" 1 "OFFSET_RIGHT_OBJECT" 0 "NO_OFFSET" ;
VAL_ 586 DAS_roadSurfaceType 2 "ROAD_SURFACE_ENHANCED" 1 "ROAD_SURFACE_NORMAL" 0 "ROAD_SURFACE_SNA" ;
VAL_ 586 DAS_autosteerHealthState 5 "HEALTH_FAULT" 4 "HEALTH_ABORTING" 3 "HEALTH_SEVERELY_DEGRADED" 2 "HEALTH_DEGRADED" 1 "HEALTH_NOMINAL" 0 "HEALTH_UNAVAILABLE" ;
VAL_ 586 DAS_lastLinePreferenceReason 15 "NONE" 5 "COUNTRY_DRIVING_SIDE" 4 "AVOID_ONCOMING_LANES" 3 "NAVIGATION_BRANCH" 2 "NEIGHBOR_LANE_PROBABILIY" 1 "AGREEMENT_WITH_NEIGHBOR_LANES" 0 "OTHER_LANE_DISAGREES_WITH_MODEL" ;
VAL_ 586 DAS_plannerState 7 "TP_EXTSTATE_LANECHANGE_ABORT" 6 "TP_EXTSTATE_LANECHANGE_WAIT_FOR_FWD_OBSTACLE" 5 "TP_EXTSTATE_LANECHANGE_WAIT_FOR_SIDE_OBSTACLE" 4 "TP_EXTSTATE_LANECHANGE_IN_PROGRESS" 3 "TP_EXTSTATE_LANECHANGE_REQUESTED" 2 "TP_EXTSTATE_FOLLOW" 1 "TP_EXTSTATE_VL" 0 "TP_EXTSTATE_DISABLED" ;
VAL_ 586 DAS_lastAutosteerAbortReason 36 "UI_ABORT_REASON_AHB_MANUAL_OVERRIDE" 35 "UI_ABORT_REASON_DRIVER_NOT_PRESENT" 34 "UI_ABORT_REASON_USER_OVERRIDE_STRIKEOUT" 33 "UI_ABORT_REASON_SEATBELT_UNBUCKLED" 32 "UI_ABORT_REASON_AEB" 31 "UI_ABORT_REASON_NO_ABORT" 30 "UI_ABORT_REASON_CAMERA_FAILSAFES" 29 "UI_ABORT_REASON_ACC_CANCEL" 28 "UI_ABORT_REASON_EPAS_ERROR_CODE" 27 "UI_ABORT_REASON_PLANNER_OUTPUT_INVALID" 26 "UI_ABORT_REASON_FOLLOWER_OUTPUT_INVALID" 25 "UI_ABORT_REASON_VEHICLE_SPEED_ABOVE_MAX" 24 "UI_ABORT_REASON_DRIVING_OFF_NAV" 23 "UI_ABORT_REASON_CID_SWITCH_DISABLED" 22 "UI_ABORT_REASON_CRUISE_FAULT" 21 "UI_ABORT_REASON_COMPONENT_MIA" 20 "UI_ABORT_REASON_EPAS_EAC_DENIED" 19 "UI_ABORT_REASON_SIDE_COLLISION_IMMINENT" 18 "UI_ABORT_REASON_TRAILER_MODE" 17 "UI_ABORT_REASON_CAM_WATCHDOG" 16 "UI_ABORT_REASON_CAM_MSG_MIA" 15 "UI_ABORT_REASON_ME_MAIN_STATE_NOT_VISION" 14 "UI_ABORT_REASON_APP_ME_STATE_NOT_VISION" 2 "UI_ABORT_REASON_HM_STEERING_ERROR" 1 "UI_ABORT_REASON_HM_VIRTUAL_LANE_NO_INPUTS" 0 "UI_ABORT_REASON_HM_LANE_VIEW_RANGE" ;
VAL_ 586 DAS_navAvailable 1 "DAS_NAV_AVAILABLE" 0 "DAS_NAV_UNAVAILABLE" ;
VAL_ 586 DAS_accSmartSpeedState 7 "SNA" 5 "OFFRAMP_DELAY" 4 "SET_SPEED_SET_REQUESTED" 3 "ACTIVE_ONRAMP" 2 "ACTIVE_INTEGRATING" 1 "ACTIVE_OFFRAMP" 0 "NOT_ACTIVE" ;
VAL_ 586 DAS_ulcInProgress 1 "ULC_ACTIVE" 0 "ULC_INACTIVE" ;
VAL_ 586 DAS_isaSystemState 3 "ISA_UNAVAILABLE" 2 "ISA_INVALID" 1 "ISA_ASSUMED_LIMITS" 0 "ISA_NOMINAL" ;
VAL_ 586 DAS_behaviorType 3 "DAS_BEHAVIOR_LANE_CHANGE_RIGHT" 2 "DAS_BEHAVIOR_LANE_CHANGE_LEFT" 1 "DAS_BEHAVIOR_IN_LANE" 0 "DAS_BEHAVIOR_INVALID" ;
VAL_ 586 DAS_ulcType 2 "ULC_TYPE_SPEED" 1 "ULC_TYPE_NAV" 0 "ULC_TYPE_NONE" ;
VAL_ 586 DAS_rearVehDetectedThisCycle 1 "VEHICLE_DETECTED" 0 "VEHICLE_NOT_DETECTED" ;
VAL_ 586 DAS_rearLeftVehDetectedCurrent 1 "VEHICLE_DETECTED" 0 "VEHICLE_NOT_DETECTED" ;
VAL_ 586 DAS_rearRightVehDetectedTrip 1 "VEHICLE_DETECTED" 0 "VEHICLE_NOT_DETECTED" ;
VAL_ 586 DAS_rearLeftVehDetectedTrip 1 "VEHICLE_DETECTED" 0 "VEHICLE_NOT_DETECTED" ;
VAL_ 1425 EPAS3S_alertID 168 "a168_torsionBarTorqueQfDegraded" 167 "a167_epbStatusCsError" 166 "a166_epbStatusCntError" 165 "a165_epbStatusMia" 164 "a164_initTestDCSInfo" 163 "a163_initTestGateDrvrInfo" 162 "a162_initTestHSDFetInfo" 161 "a161_initTestPhaDisconnInfo" 160 "a160_latentFaultTestResult" 159 "a159_pmState2CsError" 158 "a158_pmState2CntError" 157 "a157_pmState2Mia" 156 "a156_angleSensorDivergence" 155 "a155_backupEacActive" 154 "a154_assistTorqueDisabled" 153 "a153_dcsInitOffset" 152 "a152_dcsDiagReg" 151 "a151_dcsCboot" 150 "a150_currentSensOffsetDetect" 149 "a149_currentSensPathSwitch" 148 "a148_vMaxAssist" 147 "a147_backupVehSpeed" 146 "a146_diSpdCsError" 145 "a145_diSpdCntError" 144 "a144_diSpdMia" 137 "a137_piCtrlCounter85" 136 "a136_piCtrlCounter50" 135 "a135_piCtrlCounter25" 134 "a134_motFeedFwdCounter85" 133 "a133_motFeedFwdCounter50" 132 "a132_motFeedFwdCounter25" 131 "a131_phaseFeedbackError" 130 "a130_sasOffsetNotCal" 129 "a129_combEcu1StatFail" 128 "a128_apsCsError" 127 "a127_apsCntError" 126 "a126_apsMia" 125 "a125_trqSensTrimOutRange" 124 "a124_tempSensStuckInRange" 123 "a123_combEcu2StatFail" 122 "a122_olpActive" 121 "a121_pvtEcuStatCrcError" 120 "a120_pvtEcuStatCntError" 119 "a119_pvtEcuStatMia" 118 "a118_privateBusOff" 117 "a117_ecuStatCrcError" 116 "a116_ecuStatCntError" 115 "a115_ecuStatMia" 114 "a114_gtwConfigMia" 113 "a113_sasStatusError" 112 "a112_sasCsError" 111 "a111_sasCntError" 110 "a110_sasMia" 109 "a109_uiTuneReqCsError" 108 "a108_uiTuneReqCntError" 107 "a107_uiTuneReqMia" 106 "a106_vcFrontTempMia" 105 "a105_vcFrontCsError" 104 "a104_vcFrontCntError" 103 "a103_vcFrontMia" 102 "a102_diCsError" 101 "a101_diCntError" 100 "a100_diMia" 99 "a099_yawRateStatus" 98 "a098_rcmCsError" 97 "a097_rcmCntError" 96 "a096_rcmMia" 95 "a095_espWsStatus" 94 "a094_espWrCsError" 93 "a093_espWrCntError" 92 "a092_espWrMia" 91 "a091_espWsCsError" 90 "a090_espWsCntError" 89 "a089_espWsMia" 88 "a088_dasCsError" 87 "a087_dasCntError" 86 "a086_dasMia" 85 "a085_canBusOff" 84 "a084_eacCancelled" 83 "a083_crcMismatch" 82 "a082_polarityCalError" 81 "a081_coggCompError" 80 "a080_ecuInitArbError" 79 "a079_backupCurrentPlaus" 78 "a078_phaseDisconnectError" 77 "a077_highSideFetError" 76 "a076_tempSensOutofRange" 75 "a075_fspPwrCut" 74 "a074_overHeatProtect" 73 "a073_motParEstError" 72 "a072_motFeedFwdError" 71 "a071_vehSpdCorrError" 70 "a070_hodCorrError" 69 "a069_eacCorrError" 68 "a068_hystCorrError" 67 "a067_yawDampCorrError" 66 "a066_returnCorrError" 65 "a065_trqTarCorrError" 64 "a064_phaseCompCorrError" 63 "a063_dampCorrError" 62 "a062_assistCorrError" 61 "a061_bridgeUv" 60 "a060_battBridgeDiff" 59 "a059_battOvReduced" 58 "a058_battOv" 57 "a057_battUvReduced" 56 "a056_battUv" 55 "a055_floatPointError" 54 "a054_memoryProtectError" 53 "a053_extWatchdogError" 52 "a052_intWatchdogError" 51 "a051_mcuSupError" 50 "a050_mcuSmuError" 49 "a049_piCtrlError" 48 "a048_motPosCalError" 47 "a047_motPosCorrError" 46 "a046_motPos2tempError" 45 "a045_motPos2LogicError" 44 "a044_motPos2MagnetMia" 43 "a043_motPos2Uv" 42 "a042_motPos2ParityError" 41 "a041_motPos1tempError" 40 "a040_motPos1LogicError" 39 "a039_motPos1MagnetMia" 38 "a038_motPos1Uv" 37 "a037_motPos1ParityError" 36 "a036_vbbSupplyOv" 35 "a035_vbbSupplyUv" 34 "a034_vRegError" 33 "a033_vRegOutputOv" 32 "a032_vRegOutputUv" 31 "a031_abnormalShutdown" 30 "a030_phaseWbootUv" 29 "a029_phaseVbootUv" 28 "a028_phaseUbootUv" 27 "a027_phaseWlowOv" 26 "a026_phaseWhighOv" 25 "a025_phaseVlowOv" 24 "a024_phaseVhighOv" 23 "a023_phaseUlowOv" 22 "a022_phaseUhighOv" 21 "a021_phaseWlowUv" 20 "a020_phaseWhighUv" 19 "a019_phaseVlowUv" 18 "a018_phaseVhighUv" 17 "a017_phaseUlowUv" 16 "a016_phaseUhighUv" 15 "a015_gateDriveEeprom" 14 "a014_gateDriveTxError" 13 "a013_gateDriveError" 12 "a012_currentSensCalError" 11 "a011_currentSensError" 10 "a010_trqSensCalError" 9 "a009_sentDiff" 8 "a008_trqSens2Eeprom" 7 "a007_trqSens2Supply" 6 "a006_sent2Error" 5 "a005_sent2Mia" 4 "a004_trqSens1Eeprom" 3 "a003_trqSens1Supply" 2 "a002_sent1Error" 1 "a001_sent1Mia" 0 "ALERT_DO_NOT_USE_ZERO" ;
VAL_ 1425 EPAS3S_alertState 1 "SET" 0 "CLEARED" ;
VAL_ 1425 EPAS3S_a147_transitionReason 2 "MIA" 1 "WSS_FAILURE" 0 "DATA_INTEGRITY" ;
VAL_ 1425 EPAS3S_a160_currentSensorStatus 2 "STATUS_UNKNOWN" 1 "PROBABLE_FAILURE" 0 "NO_ISSUE" ;
VAL_ 1425 EPAS3S_a160_gateDriverStatus 2 "STATUS_UNKNOWN" 1 "PROBABLE_FAILURE" 0 "NO_ISSUE" ;
VAL_ 1425 EPAS3S_a160_highSideDisconnectFe 2 "STATUS_UNKNOWN" 1 "PROBABLE_FAILURE" 0 "NO_ISSUE" ;
VAL_ 1425 EPAS3S_a160_phaseDisconnectFetSt 2 "STATUS_UNKNOWN" 1 "PROBABLE_FAILURE" 0 "NO_ISSUE" ;
VAL_ 1425 EPAS3S_a160_inverterFetStatus 2 "STATUS_UNKNOWN" 1 "PROBABLE_FAILURE" 0 "NO_ISSUE" ;
VAL_ 1425 EPAS3S_a160_hsdFetFailShortTest 2 "NOT_RAN" 1 "FAIL" 0 "PASS" ;
VAL_ 1425 EPAS3S_a160_phaDisconnFailOpenTe 2 "NOT_RAN" 1 "FAIL" 0 "PASS" ;
VAL_ 1425 EPAS3S_a160_phaDisconnFailShortT 2 "NOT_RAN" 1 "FAIL" 0 "PASS" ;
VAL_ 1425 EPAS3S_a160_invFetInitTest 2 "NOT_RAN" 1 "FAIL" 0 "PASS" ;
VAL_ 1425 EPAS3S_a160_gateDrvrInitTest 2 "NOT_RAN" 1 "FAIL" 0 "PASS" ;
